VERSION ""

NS_ :

BS_:

BU_:BMS FCS VCU
BO_ 2550530133 BatP5_BMS_PackPowerCapability: 8 BMS
 SG_ P5_PackDschrgPwrLmt : 7|10@0+ (1,0) [0|1000] "kW" VCU
 SG_ P5_PackDschrgPwrStat : 13|2@0+ (1,0) [0|3] "" VCU
 SG_ P5_PackChrgPwrLmt : 11|10@0+ (1,0) [0|1000] "kW" VCU
 SG_ P5_PackChrgPwrStat : 17|2@0+ (1,0) [0|3] "" VCU

BO_ 2550595669 BatP5_BMS_ChargingInfo: 8 BMS
 SG_ P5_ChrgrCplrStat : 7|1@0+ (1,0) [0|1] "" VCU
 SG_ P5_HVBattChrgSysStatus : 6|4@0+ (1,0) [0|15] "" VCU
 SG_ P5_DCChrgCrntCmd : 2|9@0+ (1,0) [0|500] "A" VCU
 SG_ P5_CC2Vlt : 9|8@0+ (0.1,0) [0|25] "V" VCU
 SG_ P5_DCRcptPosTemp : 17|9@0+ (0.5,-40) [-40|150] "C" VCU
 SG_ P5_DCRcptNegTemp : 24|9@0+ (0.5,-40) [-40|150] "C" VCU
 SG_ P5_Tm2FullChrg : 47|14@0+ (1,0) [0|65535] "min" VCU

BO_ 2550661205 BatP5_BMS_ThermalManagement: 8 BMS
 SG_ P5_Inlet1ClntTemp : 7|11@0+ (0.1,-40) [-40|150] "C" VCU
 SG_ P5_Inlet2ClntTemp : 12|11@0+ (0.1,-40) [-40|150] "C" VCU
 SG_ P5_Outlet1ClntTemp : 17|11@0+ (0.1,-40) [-40|150] "C" VCU
 SG_ P5_Outlet2ClntTemp : 38|11@0+ (0.1,-40) [-40|150] "C" VCU
 SG_ P5_TrgtClntTemp : 43|11@0+ (0.1,-40) [-40|150] "C" VCU
 SG_ P5_TrgtClntFlowRate : 48|9@0+ (0.2,0) [0|100] "C" VCU

BO_ 2550726741 BatP5_BMS_CellVoltMaxMin: 8 BMS
 SG_ P5_MaxCellVlt : 7|13@0+ (0.001,0) [0|5] "V" VCU
 SG_ P5_MaxCellVltNum : 10|9@0+ (1,0) [0|500] "" VCU
 SG_ P5_MinCellVlt : 17|13@0+ (0.001,0) [0|5] "V" VCU
 SG_ P5_MinCellVltNum : 36|9@0+ (1,0) [0|500] "" VCU
 SG_ P5_AvgCellVlt : 43|13@0+ (0.001,0) [0|5] "V" VCU

BO_ 2550792277 BatP5_BMS_CellTempMaxMin: 8 BMS
 SG_ P5_MaxCellTemp : 7|11@0+ (0.1,-40) [-40|150] "C" VCU
 SG_ P5_MaxCellTempNum : 12|9@0+ (1,0) [0|500] "" VCU
 SG_ P5_MinCellTemp : 19|11@0+ (0.1,-40) [-40|150] "C" VCU
 SG_ P5_MinCellTempNum : 24|9@0+ (1,0) [0|500] "" VCU
 SG_ P5_AvgCellTemp : 47|11@0+ (0.1,-40) [-40|150] "C" VCU

BO_ 2550857813 BatP5_BMS_PackFaultInfo1: 8 BMS
 SG_ P5_PackTotFltNum : 7|8@0+ (1,0) [0|200] "" VCU
 SG_ P5_CellOverVoltage : 15|2@0+ (1,0) [0|3] "" VCU
 SG_ P5_CellUnderVoltage : 13|2@0+ (1,0) [0|3] "" VCU
 SG_ P5_CellVoltageDiffHi : 11|1@0+ (1,0) [0|1] "" VCU
 SG_ P5_PackOverVoltage : 10|2@0+ (1,0) [0|3] "" VCU
 SG_ P5_PackUnderVoltage : 8|2@0+ (1,0) [0|3] "" VCU
 SG_ P5_CellOverTemp : 22|2@0+ (1,0) [0|3] "" VCU
 SG_ P5_CellTempLow : 20|1@0+ (1,0) [0|1] "" VCU
 SG_ P5_CellTempDiffHi : 19|1@0+ (1,0) [0|1] "" VCU
 SG_ P5_PackDschrgCrntHi : 18|2@0+ (1,0) [0|3] "" VCU
 SG_ P5_PackChrgCrntHi : 16|2@0+ (1,0) [0|3] "" VCU
 SG_ P5_PackCrnSnsr1OffsetHi : 30|1@0+ (1,0) [0|1] "" VCU
 SG_ P5_HVIsolFlt : 29|2@0+ (1,0) [0|3] "" VCU
 SG_ P5_HVILFlt : 27|1@0+ (1,0) [0|1] "" VCU
 SG_ P5_ThrmlRunaway : 26|1@0+ (1,0) [0|1] "" VCU
 SG_ P5_CellVoltInvalid : 25|1@0+ (1,0) [0|1] "" VCU
 SG_ P5_CellTempInvalid : 24|1@0+ (1,0) [0|1] "" VCU
 SG_ P5_DaisyChainComFlt : 39|1@0+ (1,0) [0|1] "" VCU
 SG_ P5_PackVoltRatFlt : 38|1@0+ (1,0) [0|1] "" VCU
 SG_ P5_CrntSnsr1Invalid : 37|1@0+ (1,0) [0|1] "" VCU
 SG_ P5_CrntSnsr1OOR : 36|1@0+ (1,0) [0|1] "" VCU
 SG_ P5_CrntSnsr2Invalid : 35|1@0+ (1,0) [0|1] "" VCU
 SG_ P5_CrntSnsr2OOR : 34|1@0+ (1,0) [0|1] "" VCU
 SG_ P5_PackCrnSnsr2OffsetHi : 33|1@0+ (1,0) [0|1] "" VCU
 SG_ P5_OutofEnergy : 32|1@0+ (1,0) [0|1] "" VCU
 SG_ P5_IsolDetCircErr : 47|1@0+ (1,0) [0|1] "" VCU
 SG_ P5_HVILCircShortToGND : 46|1@0+ (1,0) [0|1] "" VCU
 SG_ P5_HVILCircShortToPwr : 45|1@0+ (1,0) [0|1] "" VCU

BO_ 2550923349 BatP5_BMS_PackFaultInfo2: 8 BMS
 SG_ P5_MainPosCntctrStkClsd : 7|1@0+ (1,0) [0|1] "" VCU
 SG_ P5_MainPosCntctrStkOpn : 6|1@0+ (1,0) [0|1] "" VCU
 SG_ P5_MainNegCntctr1StkClsd : 5|1@0+ (1,0) [0|1] "" VCU
 SG_ P5_MainNegCntctr1StkOpn : 4|1@0+ (1,0) [0|1] "" VCU
 SG_ P5_MainNegCntctr2StkClsd : 3|1@0+ (1,0) [0|1] "" VCU
 SG_ P5_MainNegCntctr2StkOpn : 2|1@0+ (1,0) [0|1] "" VCU
 SG_ P5_PrechargTmOut : 1|1@0+ (1,0) [0|1] "" VCU
 SG_ P5_PrechrgCrntHi : 0|1@0+ (1,0) [0|1] "" VCU
 SG_ P5_ChrgCplrPosTempHi : 15|1@0+ (1,0) [0|1] "" VCU
 SG_ P5_ChrgCplrNegTempHi : 14|1@0+ (1,0) [0|1] "" VCU
 SG_ P5_BMSPwrSuplVlt1Hi : 13|1@0+ (1,0) [0|1] "" VCU
 SG_ P5_BMSPwrSuplVlt1Lo : 12|1@0+ (1,0) [0|1] "" VCU
 SG_ P5_BMSPwrSuplVlt2Hi : 11|1@0+ (1,0) [0|1] "" VCU
 SG_ P5_BMSPwrSuplVlt2Lo : 10|1@0+ (1,0) [0|1] "" VCU
 SG_ P5_CntctrCirPwrSuplVltLo : 9|1@0+ (1,0) [0|1] "" VCU
 SG_ P5_CntctrCirPwrSuplVltHi : 8|1@0+ (1,0) [0|1] "" VCU
 SG_ P5_CAN1BusOff : 23|1@0+ (1,0) [0|1] "" VCU
 SG_ P5_CAN1BusTmOut : 22|1@0+ (1,0) [0|1] "" VCU
 SG_ P5_CAN2BusOff : 21|1@0+ (1,0) [0|1] "" VCU
 SG_ P5_CAN2BusTmOut : 20|1@0+ (1,0) [0|1] "" VCU
 SG_ P5_CellBalCircTempHi : 19|1@0+ (1,0) [0|1] "" VCU
 SG_ P5_ClntInTempHi : 18|1@0+ (1,0) [0|1] "" VCU
 SG_ P5_ClntOutTempHi : 17|1@0+ (1,0) [0|1] "" VCU
 SG_ P5_CellExtrmUdrVolt : 16|1@0+ (1,0) [0|1] "" VCU
 SG_ P5_CellExtrmOvrVolt : 31|1@0+ (1,0) [0|1] "" VCU
 SG_ P5_Branch1DischrgCrntHi  : 30|1@0+ (1,0) [0|1] "" VCU
 SG_ P5_Branch2DischrgCrntHi  : 29|1@0+ (1,0) [0|1] "" VCU
 SG_ P5_Branch1ChrgCrntHi  : 28|1@0+ (1,0) [0|1] "" VCU
 SG_ P5_Branch2ChrgCrntHi  : 27|1@0+ (1,0) [0|1] "" VCU
 SG_ P5_InitFailed : 26|1@0+ (1,0) [0|1] "" VCU
 SG_ P5_PackErrCode : 25|10@0+ (1,0) [0|1023] "" VCU

BO_ 2550988885 BatP5_BMS_PackConfigInfo: 8 BMS
 SG_ P5_PackTotCellNum : 7|9@0+ (1,0) [0|500] "" VCU
 SG_ P5_PackTotCellTempSnsrNum : 14|9@0+ (1,0) [0|500] "" VCU

BO_ 2552299605 BatP5_BMS_BMSVersion: 8 BMS
 SG_ P5_BMSASWMajVerNum : 7|8@0+ (1,0) [0|9] "" VCU
 SG_ P5_BMSASWMinVerNum : 15|8@0+ (1,0) [0|99] "" VCU
 SG_ P5_BMSASWPatchVerNum : 23|8@0+ (1,0) [0|255] "" VCU
 SG_ P5_BMSBSWMajVerNum : 31|8@0+ (1,0) [0|9] "" VCU
 SG_ P5_BMSBSWMinVerNum : 39|8@0+ (1,0) [0|99] "" VCU
 SG_ P5_BMSBSWPatchVerNum : 47|8@0+ (1,0) [0|255] "" VCU

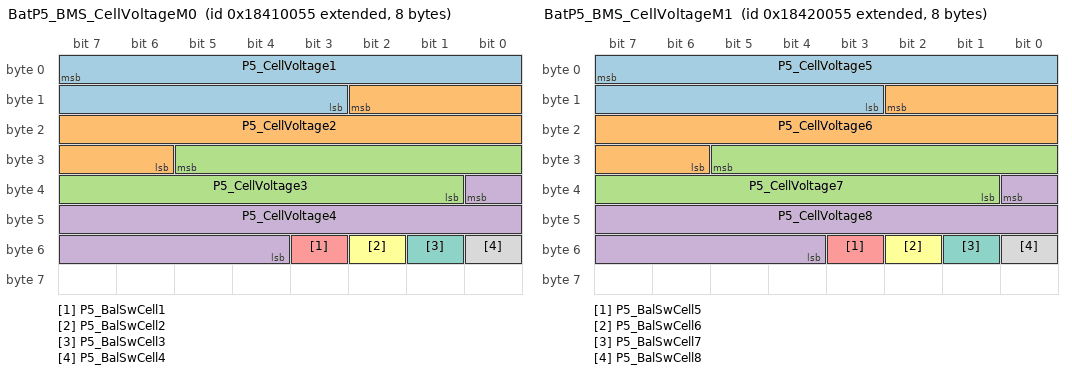
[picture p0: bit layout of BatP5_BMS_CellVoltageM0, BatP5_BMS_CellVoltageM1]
BO_ 2554396757 BatP5_BMS_CellVoltageM0: 8 BMS
 SG_ P5_CellVoltage1 : 7|13@0+ (0.001,0) [0|5] "V" VCU
 SG_ P5_CellVoltage2 : 10|13@0+ (0.001,0) [0|5] "V" VCU
 SG_ P5_CellVoltage3 : 29|13@0+ (0.001,0) [0|5] "V" VCU
 SG_ P5_CellVoltage4 : 32|13@0+ (0.001,0) [0|5] "V" VCU
 SG_ P5_BalSwCell1 : 51|1@0+ (1,0) [0|1] "" VCU
 SG_ P5_BalSwCell2 : 50|1@0+ (1,0) [0|1] "" VCU
 SG_ P5_BalSwCell3 : 49|1@0+ (1,0) [0|1] "" VCU
 SG_ P5_BalSwCell4 : 48|1@0+ (1,0) [0|1] "" VCU

BO_ 2554462293 BatP5_BMS_CellVoltageM1: 8 BMS
 SG_ P5_CellVoltage5 : 7|13@0+ (0.001,0) [0|5] "V" VCU
 SG_ P5_CellVoltage6 : 10|13@0+ (0.001,0) [0|5] "V" VCU
 SG_ P5_CellVoltage7 : 29|13@0+ (0.001,0) [0|5] "V" VCU
 SG_ P5_CellVoltage8 : 32|13@0+ (0.001,0) [0|5] "V" VCU
 SG_ P5_BalSwCell5 : 51|1@0+ (1,0) [0|1] "" VCU
 SG_ P5_BalSwCell6 : 50|1@0+ (1,0) [0|1] "" VCU
 SG_ P5_BalSwCell7 : 49|1@0+ (1,0) [0|1] "" VCU
 SG_ P5_BalSwCell8 : 48|1@0+ (1,0) [0|1] "" VCU

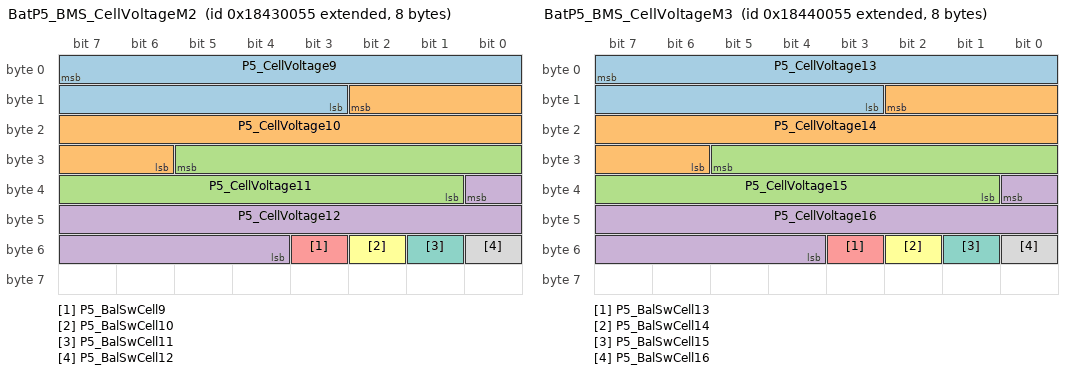
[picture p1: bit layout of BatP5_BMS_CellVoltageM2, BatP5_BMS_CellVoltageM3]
BO_ 2554527829 BatP5_BMS_CellVoltageM2: 8 BMS
 SG_ P5_CellVoltage9 : 7|13@0+ (0.001,0) [0|5] "V" VCU
 SG_ P5_CellVoltage10 : 10|13@0+ (0.001,0) [0|5] "V" VCU
 SG_ P5_CellVoltage11 : 29|13@0+ (0.001,0) [0|5] "V" VCU
 SG_ P5_CellVoltage12 : 32|13@0+ (0.001,0) [0|5] "V" VCU
 SG_ P5_BalSwCell9 : 51|1@0+ (1,0) [0|1] "" VCU
 SG_ P5_BalSwCell10 : 50|1@0+ (1,0) [0|1] "" VCU
 SG_ P5_BalSwCell11 : 49|1@0+ (1,0) [0|1] "" VCU
 SG_ P5_BalSwCell12 : 48|1@0+ (1,0) [0|1] "" VCU

BO_ 2554593365 BatP5_BMS_CellVoltageM3: 8 BMS
 SG_ P5_CellVoltage13 : 7|13@0+ (0.001,0) [0|5] "V" VCU
 SG_ P5_CellVoltage14 : 10|13@0+ (0.001,0) [0|5] "V" VCU
 SG_ P5_CellVoltage15 : 29|13@0+ (0.001,0) [0|5] "V" VCU
 SG_ P5_CellVoltage16 : 32|13@0+ (0.001,0) [0|5] "V" VCU
 SG_ P5_BalSwCell13 : 51|1@0+ (1,0) [0|1] "" VCU
 SG_ P5_BalSwCell14 : 50|1@0+ (1,0) [0|1] "" VCU
 SG_ P5_BalSwCell15 : 49|1@0+ (1,0) [0|1] "" VCU
 SG_ P5_BalSwCell16 : 48|1@0+ (1,0) [0|1] "" VCU

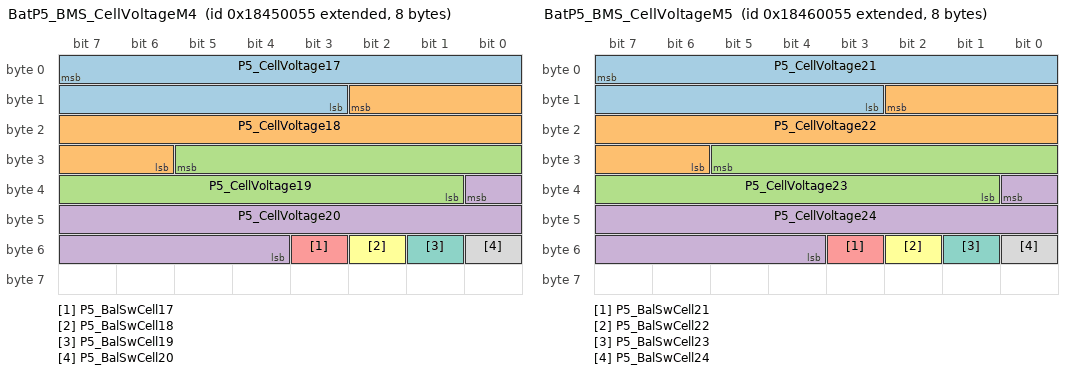
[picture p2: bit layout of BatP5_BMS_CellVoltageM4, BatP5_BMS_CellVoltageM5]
BO_ 2554658901 BatP5_BMS_CellVoltageM4: 8 BMS
 SG_ P5_CellVoltage17 : 7|13@0+ (0.001,0) [0|5] "V" VCU
 SG_ P5_CellVoltage18 : 10|13@0+ (0.001,0) [0|5] "V" VCU
 SG_ P5_CellVoltage19 : 29|13@0+ (0.001,0) [0|5] "V" VCU
 SG_ P5_CellVoltage20 : 32|13@0+ (0.001,0) [0|5] "V" VCU
 SG_ P5_BalSwCell17 : 51|1@0+ (1,0) [0|1] "" VCU
 SG_ P5_BalSwCell18 : 50|1@0+ (1,0) [0|1] "" VCU
 SG_ P5_BalSwCell19 : 49|1@0+ (1,0) [0|1] "" VCU
 SG_ P5_BalSwCell20 : 48|1@0+ (1,0) [0|1] "" VCU

BO_ 2554724437 BatP5_BMS_CellVoltageM5: 8 BMS
 SG_ P5_CellVoltage21 : 7|13@0+ (0.001,0) [0|5] "V" VCU
 SG_ P5_CellVoltage22 : 10|13@0+ (0.001,0) [0|5] "V" VCU
 SG_ P5_CellVoltage23 : 29|13@0+ (0.001,0) [0|5] "V" VCU
 SG_ P5_CellVoltage24 : 32|13@0+ (0.001,0) [0|5] "V" VCU
 SG_ P5_BalSwCell21 : 51|1@0+ (1,0) [0|1] "" VCU
 SG_ P5_BalSwCell22 : 50|1@0+ (1,0) [0|1] "" VCU
 SG_ P5_BalSwCell23 : 49|1@0+ (1,0) [0|1] "" VCU
 SG_ P5_BalSwCell24 : 48|1@0+ (1,0) [0|1] "" VCU

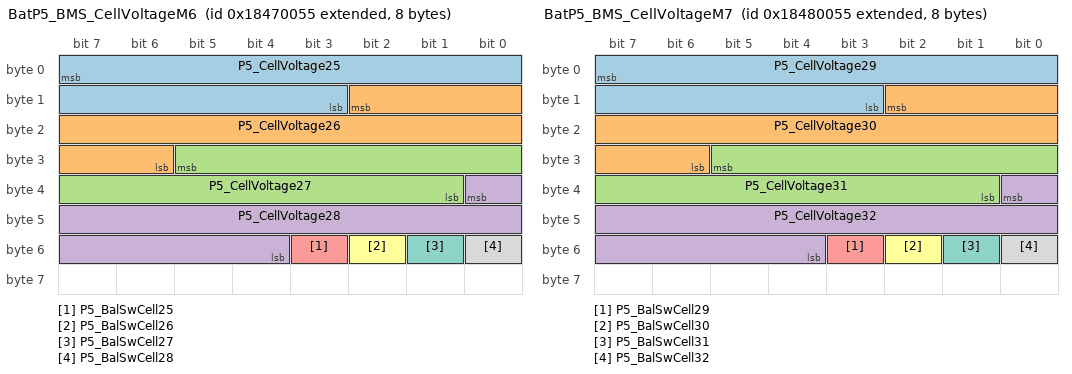
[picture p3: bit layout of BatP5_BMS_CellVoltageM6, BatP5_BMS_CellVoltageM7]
BO_ 2554789973 BatP5_BMS_CellVoltageM6: 8 BMS
 SG_ P5_CellVoltage25 : 7|13@0+ (0.001,0) [0|5] "V" VCU
 SG_ P5_CellVoltage26 : 10|13@0+ (0.001,0) [0|5] "V" VCU
 SG_ P5_CellVoltage27 : 29|13@0+ (0.001,0) [0|5] "V" VCU
 SG_ P5_CellVoltage28 : 32|13@0+ (0.001,0) [0|5] "V" VCU
 SG_ P5_BalSwCell25 : 51|1@0+ (1,0) [0|1] "" VCU
 SG_ P5_BalSwCell26 : 50|1@0+ (1,0) [0|1] "" VCU
 SG_ P5_BalSwCell27 : 49|1@0+ (1,0) [0|1] "" VCU
 SG_ P5_BalSwCell28 : 48|1@0+ (1,0) [0|1] "" VCU

BO_ 2554855509 BatP5_BMS_CellVoltageM7: 8 BMS
 SG_ P5_CellVoltage29 : 7|13@0+ (0.001,0) [0|5] "V" VCU
 SG_ P5_CellVoltage30 : 10|13@0+ (0.001,0) [0|5] "V" VCU
 SG_ P5_CellVoltage31 : 29|13@0+ (0.001,0) [0|5] "V" VCU
 SG_ P5_CellVoltage32 : 32|13@0+ (0.001,0) [0|5] "V" VCU
 SG_ P5_BalSwCell29 : 51|1@0+ (1,0) [0|1] "" VCU
 SG_ P5_BalSwCell30 : 50|1@0+ (1,0) [0|1] "" VCU
 SG_ P5_BalSwCell31 : 49|1@0+ (1,0) [0|1] "" VCU
 SG_ P5_BalSwCell32 : 48|1@0+ (1,0) [0|1] "" VCU

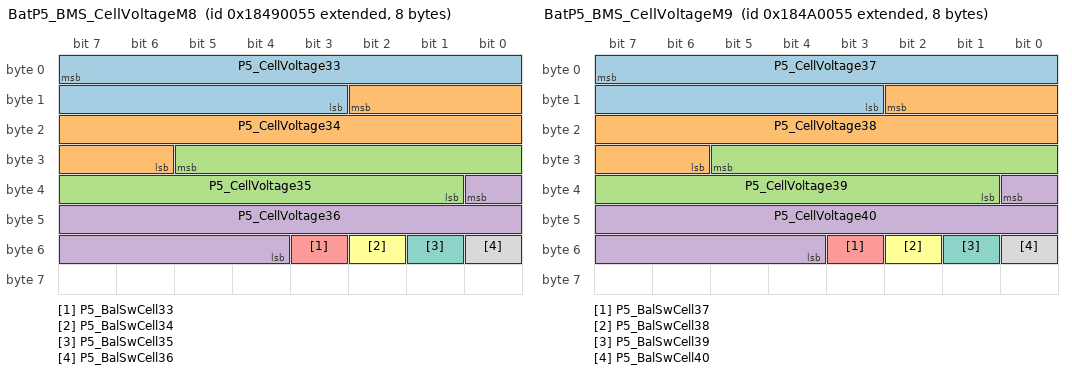
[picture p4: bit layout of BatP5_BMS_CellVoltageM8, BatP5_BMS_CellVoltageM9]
BO_ 2554921045 BatP5_BMS_CellVoltageM8: 8 BMS
 SG_ P5_CellVoltage33 : 7|13@0+ (0.001,0) [0|5] "V" VCU
 SG_ P5_CellVoltage34 : 10|13@0+ (0.001,0) [0|5] "V" VCU
 SG_ P5_CellVoltage35 : 29|13@0+ (0.001,0) [0|5] "V" VCU
 SG_ P5_CellVoltage36 : 32|13@0+ (0.001,0) [0|5] "V" VCU
 SG_ P5_BalSwCell33 : 51|1@0+ (1,0) [0|1] "" VCU
 SG_ P5_BalSwCell34 : 50|1@0+ (1,0) [0|1] "" VCU
 SG_ P5_BalSwCell35 : 49|1@0+ (1,0) [0|1] "" VCU
 SG_ P5_BalSwCell36 : 48|1@0+ (1,0) [0|1] "" VCU

BO_ 2554986581 BatP5_BMS_CellVoltageM9: 8 BMS
 SG_ P5_CellVoltage37 : 7|13@0+ (0.001,0) [0|5] "V" VCU
 SG_ P5_CellVoltage38 : 10|13@0+ (0.001,0) [0|5] "V" VCU
 SG_ P5_CellVoltage39 : 29|13@0+ (0.001,0) [0|5] "V" VCU
 SG_ P5_CellVoltage40 : 32|13@0+ (0.001,0) [0|5] "V" VCU
 SG_ P5_BalSwCell37 : 51|1@0+ (1,0) [0|1] "" VCU
 SG_ P5_BalSwCell38 : 50|1@0+ (1,0) [0|1] "" VCU
 SG_ P5_BalSwCell39 : 49|1@0+ (1,0) [0|1] "" VCU
 SG_ P5_BalSwCell40 : 48|1@0+ (1,0) [0|1] "" VCU

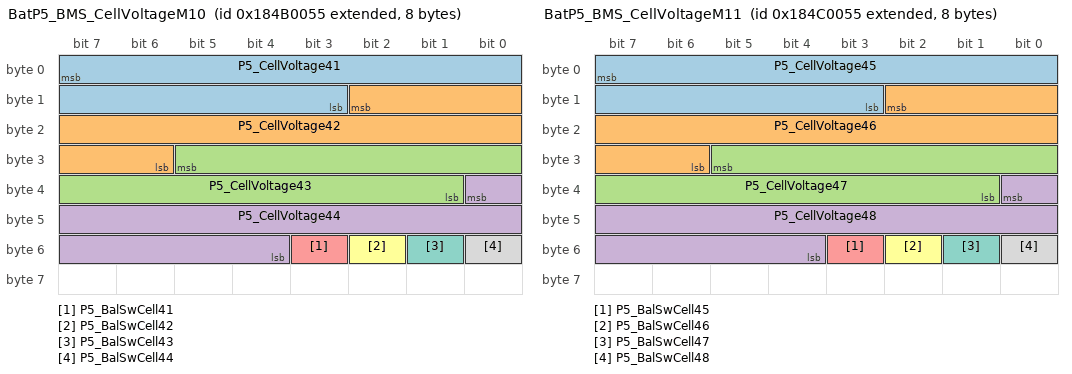
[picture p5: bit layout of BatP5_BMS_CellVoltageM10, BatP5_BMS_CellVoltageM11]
BO_ 2555052117 BatP5_BMS_CellVoltageM10: 8 BMS
 SG_ P5_CellVoltage41 : 7|13@0+ (0.001,0) [0|5] "V" VCU
 SG_ P5_CellVoltage42 : 10|13@0+ (0.001,0) [0|5] "V" VCU
 SG_ P5_CellVoltage43 : 29|13@0+ (0.001,0) [0|5] "V" VCU
 SG_ P5_CellVoltage44 : 32|13@0+ (0.001,0) [0|5] "V" VCU
 SG_ P5_BalSwCell41 : 51|1@0+ (1,0) [0|1] "" VCU
 SG_ P5_BalSwCell42 : 50|1@0+ (1,0) [0|1] "" VCU
 SG_ P5_BalSwCell43 : 49|1@0+ (1,0) [0|1] "" VCU
 SG_ P5_BalSwCell44 : 48|1@0+ (1,0) [0|1] "" VCU

BO_ 2555117653 BatP5_BMS_CellVoltageM11: 8 BMS
 SG_ P5_CellVoltage45 : 7|13@0+ (0.001,0) [0|5] "V" VCU
 SG_ P5_CellVoltage46 : 10|13@0+ (0.001,0) [0|5] "V" VCU
 SG_ P5_CellVoltage47 : 29|13@0+ (0.001,0) [0|5] "V" VCU
 SG_ P5_CellVoltage48 : 32|13@0+ (0.001,0) [0|5] "V" VCU
 SG_ P5_BalSwCell45 : 51|1@0+ (1,0) [0|1] "" VCU
 SG_ P5_BalSwCell46 : 50|1@0+ (1,0) [0|1] "" VCU
 SG_ P5_BalSwCell47 : 49|1@0+ (1,0) [0|1] "" VCU
 SG_ P5_BalSwCell48 : 48|1@0+ (1,0) [0|1] "" VCU

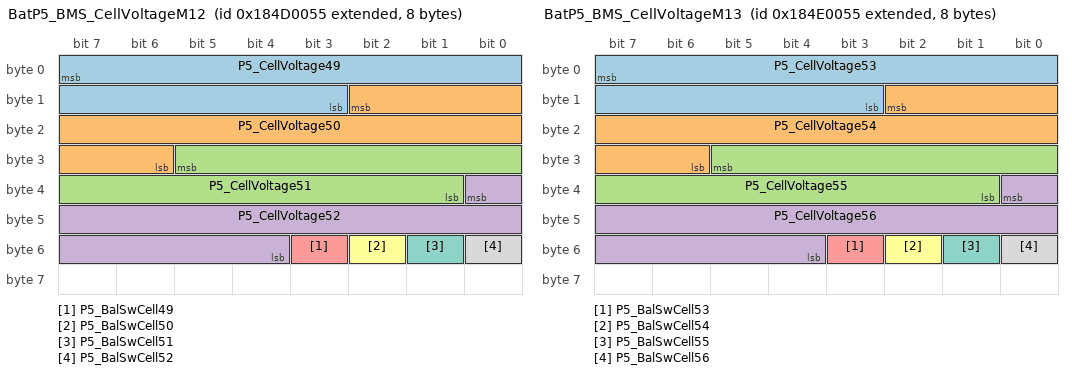
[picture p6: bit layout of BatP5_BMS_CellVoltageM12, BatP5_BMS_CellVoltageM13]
BO_ 2555183189 BatP5_BMS_CellVoltageM12: 8 BMS
 SG_ P5_CellVoltage49 : 7|13@0+ (0.001,0) [0|5] "V" VCU
 SG_ P5_CellVoltage50 : 10|13@0+ (0.001,0) [0|5] "V" VCU
 SG_ P5_CellVoltage51 : 29|13@0+ (0.001,0) [0|5] "V" VCU
 SG_ P5_CellVoltage52 : 32|13@0+ (0.001,0) [0|5] "V" VCU
 SG_ P5_BalSwCell49 : 51|1@0+ (1,0) [0|1] "" VCU
 SG_ P5_BalSwCell50 : 50|1@0+ (1,0) [0|1] "" VCU
 SG_ P5_BalSwCell51 : 49|1@0+ (1,0) [0|1] "" VCU
 SG_ P5_BalSwCell52 : 48|1@0+ (1,0) [0|1] "" VCU

BO_ 2555248725 BatP5_BMS_CellVoltageM13: 8 BMS
 SG_ P5_CellVoltage53 : 7|13@0+ (0.001,0) [0|5] "V" VCU
 SG_ P5_CellVoltage54 : 10|13@0+ (0.001,0) [0|5] "V" VCU
 SG_ P5_CellVoltage55 : 29|13@0+ (0.001,0) [0|5] "V" VCU
 SG_ P5_CellVoltage56 : 32|13@0+ (0.001,0) [0|5] "V" VCU
 SG_ P5_BalSwCell53 : 51|1@0+ (1,0) [0|1] "" VCU
 SG_ P5_BalSwCell54 : 50|1@0+ (1,0) [0|1] "" VCU
 SG_ P5_BalSwCell55 : 49|1@0+ (1,0) [0|1] "" VCU
 SG_ P5_BalSwCell56 : 48|1@0+ (1,0) [0|1] "" VCU

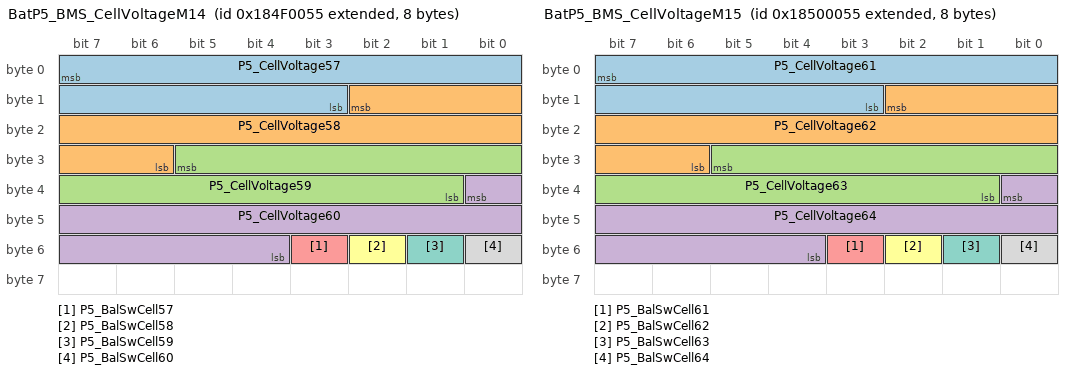
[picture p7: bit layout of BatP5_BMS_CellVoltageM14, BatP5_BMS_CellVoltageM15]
BO_ 2555314261 BatP5_BMS_CellVoltageM14: 8 BMS
 SG_ P5_CellVoltage57 : 7|13@0+ (0.001,0) [0|5] "V" VCU
 SG_ P5_CellVoltage58 : 10|13@0+ (0.001,0) [0|5] "V" VCU
 SG_ P5_CellVoltage59 : 29|13@0+ (0.001,0) [0|5] "V" VCU
 SG_ P5_CellVoltage60 : 32|13@0+ (0.001,0) [0|5] "V" VCU
 SG_ P5_BalSwCell57 : 51|1@0+ (1,0) [0|1] "" VCU
 SG_ P5_BalSwCell58 : 50|1@0+ (1,0) [0|1] "" VCU
 SG_ P5_BalSwCell59 : 49|1@0+ (1,0) [0|1] "" VCU
 SG_ P5_BalSwCell60 : 48|1@0+ (1,0) [0|1] "" VCU

BO_ 2555379797 BatP5_BMS_CellVoltageM15: 8 BMS
 SG_ P5_CellVoltage61 : 7|13@0+ (0.001,0) [0|5] "V" VCU
 SG_ P5_CellVoltage62 : 10|13@0+ (0.001,0) [0|5] "V" VCU
 SG_ P5_CellVoltage63 : 29|13@0+ (0.001,0) [0|5] "V" VCU
 SG_ P5_CellVoltage64 : 32|13@0+ (0.001,0) [0|5] "V" VCU
 SG_ P5_BalSwCell61 : 51|1@0+ (1,0) [0|1] "" VCU
 SG_ P5_BalSwCell62 : 50|1@0+ (1,0) [0|1] "" VCU
 SG_ P5_BalSwCell63 : 49|1@0+ (1,0) [0|1] "" VCU
 SG_ P5_BalSwCell64 : 48|1@0+ (1,0) [0|1] "" VCU

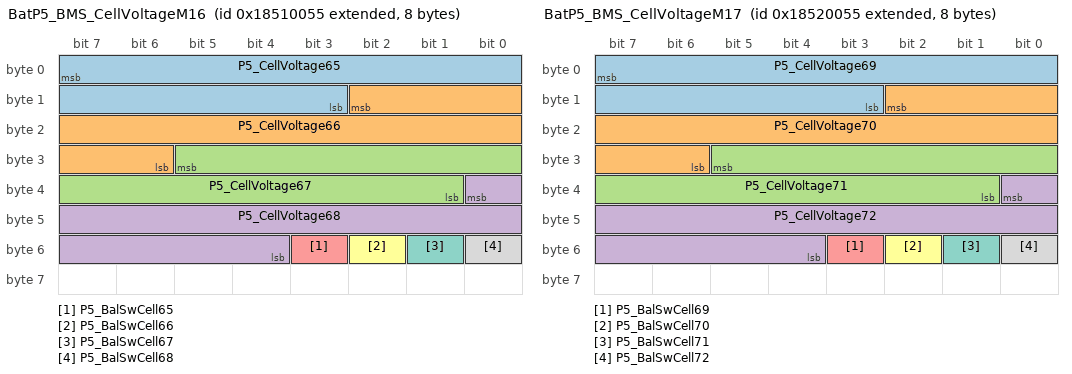
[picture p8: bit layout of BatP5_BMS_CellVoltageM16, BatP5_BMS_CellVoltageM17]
BO_ 2555445333 BatP5_BMS_CellVoltageM16: 8 BMS
 SG_ P5_CellVoltage65 : 7|13@0+ (0.001,0) [0|5] "V" VCU
 SG_ P5_CellVoltage66 : 10|13@0+ (0.001,0) [0|5] "V" VCU
 SG_ P5_CellVoltage67 : 29|13@0+ (0.001,0) [0|5] "V" VCU
 SG_ P5_CellVoltage68 : 32|13@0+ (0.001,0) [0|5] "V" VCU
 SG_ P5_BalSwCell65 : 51|1@0+ (1,0) [0|1] "" VCU
 SG_ P5_BalSwCell66 : 50|1@0+ (1,0) [0|1] "" VCU
 SG_ P5_BalSwCell67 : 49|1@0+ (1,0) [0|1] "" VCU
 SG_ P5_BalSwCell68 : 48|1@0+ (1,0) [0|1] "" VCU

BO_ 2555510869 BatP5_BMS_CellVoltageM17: 8 BMS
 SG_ P5_CellVoltage69 : 7|13@0+ (0.001,0) [0|5] "V" VCU
 SG_ P5_CellVoltage70 : 10|13@0+ (0.001,0) [0|5] "V" VCU
 SG_ P5_CellVoltage71 : 29|13@0+ (0.001,0) [0|5] "V" VCU
 SG_ P5_CellVoltage72 : 32|13@0+ (0.001,0) [0|5] "V" VCU
 SG_ P5_BalSwCell69 : 51|1@0+ (1,0) [0|1] "" VCU
 SG_ P5_BalSwCell70 : 50|1@0+ (1,0) [0|1] "" VCU
 SG_ P5_BalSwCell71 : 49|1@0+ (1,0) [0|1] "" VCU
 SG_ P5_BalSwCell72 : 48|1@0+ (1,0) [0|1] "" VCU

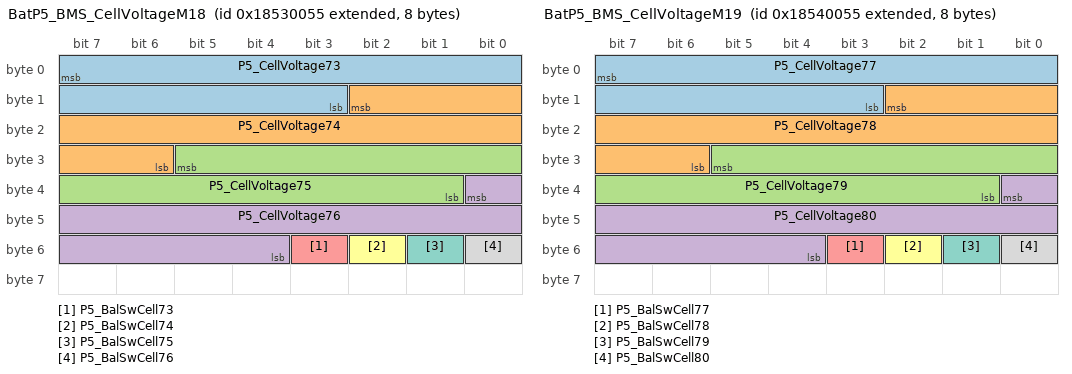
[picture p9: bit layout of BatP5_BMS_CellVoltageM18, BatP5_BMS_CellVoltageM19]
BO_ 2555576405 BatP5_BMS_CellVoltageM18: 8 BMS
 SG_ P5_CellVoltage73 : 7|13@0+ (0.001,0) [0|5] "V" VCU
 SG_ P5_CellVoltage74 : 10|13@0+ (0.001,0) [0|5] "V" VCU
 SG_ P5_CellVoltage75 : 29|13@0+ (0.001,0) [0|5] "V" VCU
 SG_ P5_CellVoltage76 : 32|13@0+ (0.001,0) [0|5] "V" VCU
 SG_ P5_BalSwCell73 : 51|1@0+ (1,0) [0|1] "" VCU
 SG_ P5_BalSwCell74 : 50|1@0+ (1,0) [0|1] "" VCU
 SG_ P5_BalSwCell75 : 49|1@0+ (1,0) [0|1] "" VCU
 SG_ P5_BalSwCell76 : 48|1@0+ (1,0) [0|1] "" VCU

BO_ 2555641941 BatP5_BMS_CellVoltageM19: 8 BMS
 SG_ P5_CellVoltage77 : 7|13@0+ (0.001,0) [0|5] "V" VCU
 SG_ P5_CellVoltage78 : 10|13@0+ (0.001,0) [0|5] "V" VCU
 SG_ P5_CellVoltage79 : 29|13@0+ (0.001,0) [0|5] "V" VCU
 SG_ P5_CellVoltage80 : 32|13@0+ (0.001,0) [0|5] "V" VCU
 SG_ P5_BalSwCell77 : 51|1@0+ (1,0) [0|1] "" VCU
 SG_ P5_BalSwCell78 : 50|1@0+ (1,0) [0|1] "" VCU
 SG_ P5_BalSwCell79 : 49|1@0+ (1,0) [0|1] "" VCU
 SG_ P5_BalSwCell80 : 48|1@0+ (1,0) [0|1] "" VCU

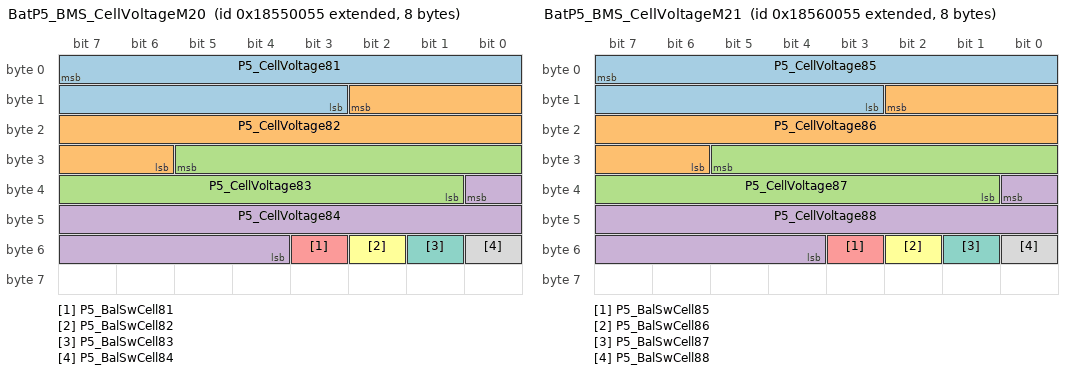
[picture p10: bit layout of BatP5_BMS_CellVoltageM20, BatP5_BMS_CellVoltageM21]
BO_ 2555707477 BatP5_BMS_CellVoltageM20: 8 BMS
 SG_ P5_CellVoltage81 : 7|13@0+ (0.001,0) [0|5] "V" VCU
 SG_ P5_CellVoltage82 : 10|13@0+ (0.001,0) [0|5] "V" VCU
 SG_ P5_CellVoltage83 : 29|13@0+ (0.001,0) [0|5] "V" VCU
 SG_ P5_CellVoltage84 : 32|13@0+ (0.001,0) [0|5] "V" VCU
 SG_ P5_BalSwCell81 : 51|1@0+ (1,0) [0|1] "" VCU
 SG_ P5_BalSwCell82 : 50|1@0+ (1,0) [0|1] "" VCU
 SG_ P5_BalSwCell83 : 49|1@0+ (1,0) [0|1] "" VCU
 SG_ P5_BalSwCell84 : 48|1@0+ (1,0) [0|1] "" VCU

BO_ 2555773013 BatP5_BMS_CellVoltageM21: 8 BMS
 SG_ P5_CellVoltage85 : 7|13@0+ (0.001,0) [0|5] "V" VCU
 SG_ P5_CellVoltage86 : 10|13@0+ (0.001,0) [0|5] "V" VCU
 SG_ P5_CellVoltage87 : 29|13@0+ (0.001,0) [0|5] "V" VCU
 SG_ P5_CellVoltage88 : 32|13@0+ (0.001,0) [0|5] "V" VCU
 SG_ P5_BalSwCell85 : 51|1@0+ (1,0) [0|1] "" VCU
 SG_ P5_BalSwCell86 : 50|1@0+ (1,0) [0|1] "" VCU
 SG_ P5_BalSwCell87 : 49|1@0+ (1,0) [0|1] "" VCU
 SG_ P5_BalSwCell88 : 48|1@0+ (1,0) [0|1] "" VCU

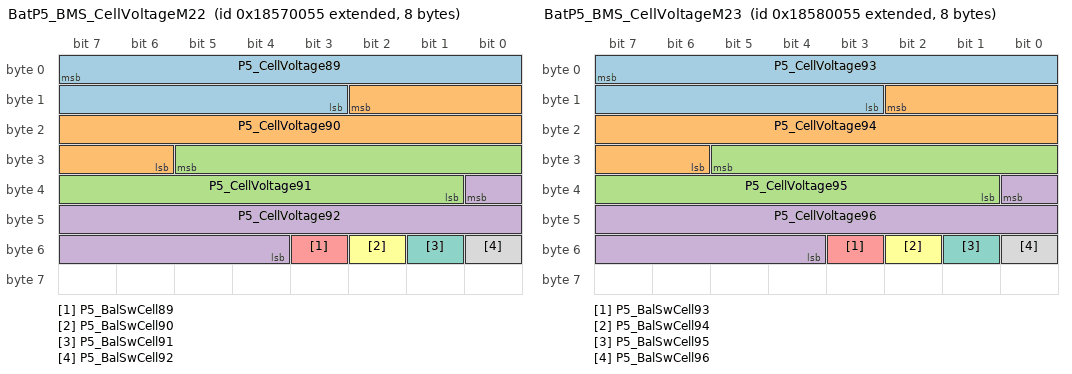
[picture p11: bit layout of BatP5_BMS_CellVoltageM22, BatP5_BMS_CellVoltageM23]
BO_ 2555838549 BatP5_BMS_CellVoltageM22: 8 BMS
 SG_ P5_CellVoltage89 : 7|13@0+ (0.001,0) [0|5] "V" VCU
 SG_ P5_CellVoltage90 : 10|13@0+ (0.001,0) [0|5] "V" VCU
 SG_ P5_CellVoltage91 : 29|13@0+ (0.001,0) [0|5] "V" VCU
 SG_ P5_CellVoltage92 : 32|13@0+ (0.001,0) [0|5] "V" VCU
 SG_ P5_BalSwCell89 : 51|1@0+ (1,0) [0|1] "" VCU
 SG_ P5_BalSwCell90 : 50|1@0+ (1,0) [0|1] "" VCU
 SG_ P5_BalSwCell91 : 49|1@0+ (1,0) [0|1] "" VCU
 SG_ P5_BalSwCell92 : 48|1@0+ (1,0) [0|1] "" VCU

BO_ 2555904085 BatP5_BMS_CellVoltageM23: 8 BMS
 SG_ P5_CellVoltage93 : 7|13@0+ (0.001,0) [0|5] "V" VCU
 SG_ P5_CellVoltage94 : 10|13@0+ (0.001,0) [0|5] "V" VCU
 SG_ P5_CellVoltage95 : 29|13@0+ (0.001,0) [0|5] "V" VCU
 SG_ P5_CellVoltage96 : 32|13@0+ (0.001,0) [0|5] "V" VCU
 SG_ P5_BalSwCell93 : 51|1@0+ (1,0) [0|1] "" VCU
 SG_ P5_BalSwCell94 : 50|1@0+ (1,0) [0|1] "" VCU
 SG_ P5_BalSwCell95 : 49|1@0+ (1,0) [0|1] "" VCU
 SG_ P5_BalSwCell96 : 48|1@0+ (1,0) [0|1] "" VCU

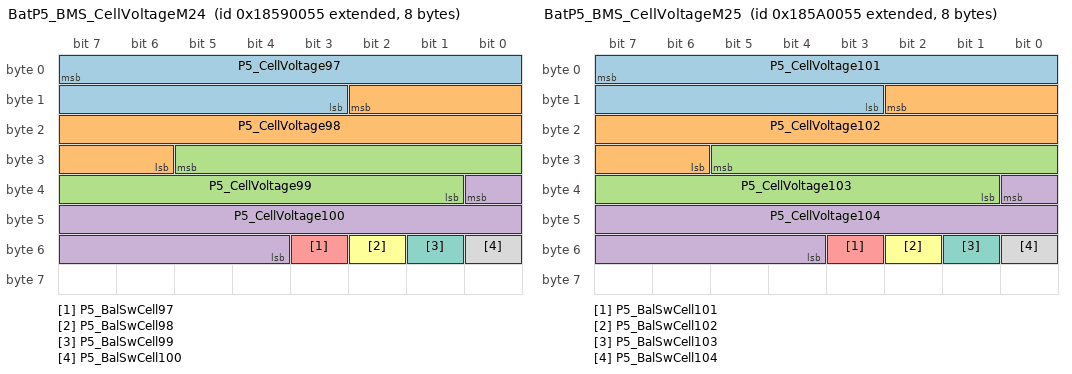
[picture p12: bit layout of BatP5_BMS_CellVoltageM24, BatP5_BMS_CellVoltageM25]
BO_ 2555969621 BatP5_BMS_CellVoltageM24: 8 BMS
 SG_ P5_CellVoltage97 : 7|13@0+ (0.001,0) [0|5] "V" VCU
 SG_ P5_CellVoltage98 : 10|13@0+ (0.001,0) [0|5] "V" VCU
 SG_ P5_CellVoltage99 : 29|13@0+ (0.001,0) [0|5] "V" VCU
 SG_ P5_CellVoltage100 : 32|13@0+ (0.001,0) [0|5] "V" VCU
 SG_ P5_BalSwCell97 : 51|1@0+ (1,0) [0|1] "" VCU
 SG_ P5_BalSwCell98 : 50|1@0+ (1,0) [0|1] "" VCU
 SG_ P5_BalSwCell99 : 49|1@0+ (1,0) [0|1] "" VCU
 SG_ P5_BalSwCell100 : 48|1@0+ (1,0) [0|1] "" VCU

BO_ 2556035157 BatP5_BMS_CellVoltageM25: 8 BMS
 SG_ P5_CellVoltage101 : 7|13@0+ (0.001,0) [0|5] "V" VCU
 SG_ P5_CellVoltage102 : 10|13@0+ (0.001,0) [0|5] "V" VCU
 SG_ P5_CellVoltage103 : 29|13@0+ (0.001,0) [0|5] "V" VCU
 SG_ P5_CellVoltage104 : 32|13@0+ (0.001,0) [0|5] "V" VCU
 SG_ P5_BalSwCell101 : 51|1@0+ (1,0) [0|1] "" VCU
 SG_ P5_BalSwCell102 : 50|1@0+ (1,0) [0|1] "" VCU
 SG_ P5_BalSwCell103 : 49|1@0+ (1,0) [0|1] "" VCU
 SG_ P5_BalSwCell104 : 48|1@0+ (1,0) [0|1] "" VCU

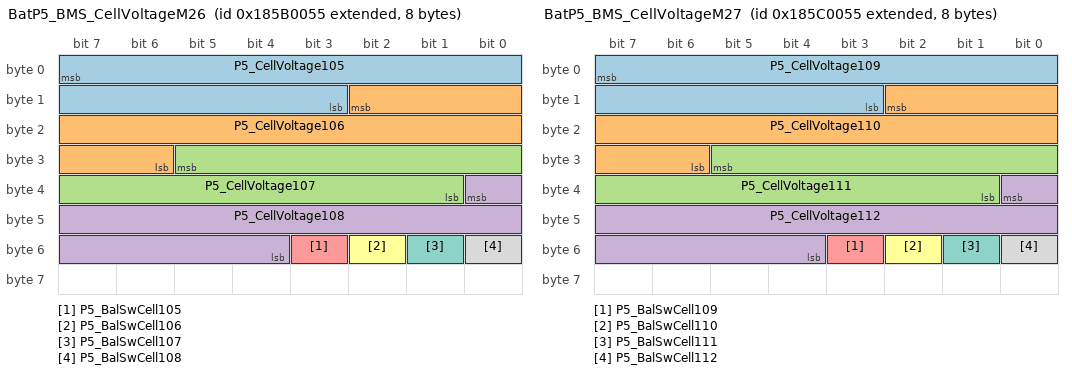
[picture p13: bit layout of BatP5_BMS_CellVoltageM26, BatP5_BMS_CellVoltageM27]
BO_ 2556100693 BatP5_BMS_CellVoltageM26: 8 BMS
 SG_ P5_CellVoltage105 : 7|13@0+ (0.001,0) [0|5] "V" VCU
 SG_ P5_CellVoltage106 : 10|13@0+ (0.001,0) [0|5] "V" VCU
 SG_ P5_CellVoltage107 : 29|13@0+ (0.001,0) [0|5] "V" VCU
 SG_ P5_CellVoltage108 : 32|13@0+ (0.001,0) [0|5] "V" VCU
 SG_ P5_BalSwCell105 : 51|1@0+ (1,0) [0|1] "" VCU
 SG_ P5_BalSwCell106 : 50|1@0+ (1,0) [0|1] "" VCU
 SG_ P5_BalSwCell107 : 49|1@0+ (1,0) [0|1] "" VCU
 SG_ P5_BalSwCell108 : 48|1@0+ (1,0) [0|1] "" VCU

BO_ 2556166229 BatP5_BMS_CellVoltageM27: 8 BMS
 SG_ P5_CellVoltage109 : 7|13@0+ (0.001,0) [0|5] "V" VCU
 SG_ P5_CellVoltage110 : 10|13@0+ (0.001,0) [0|5] "V" VCU
 SG_ P5_CellVoltage111 : 29|13@0+ (0.001,0) [0|5] "V" VCU
 SG_ P5_CellVoltage112 : 32|13@0+ (0.001,0) [0|5] "V" VCU
 SG_ P5_BalSwCell109 : 51|1@0+ (1,0) [0|1] "" VCU
 SG_ P5_BalSwCell110 : 50|1@0+ (1,0) [0|1] "" VCU
 SG_ P5_BalSwCell111 : 49|1@0+ (1,0) [0|1] "" VCU
 SG_ P5_BalSwCell112 : 48|1@0+ (1,0) [0|1] "" VCU

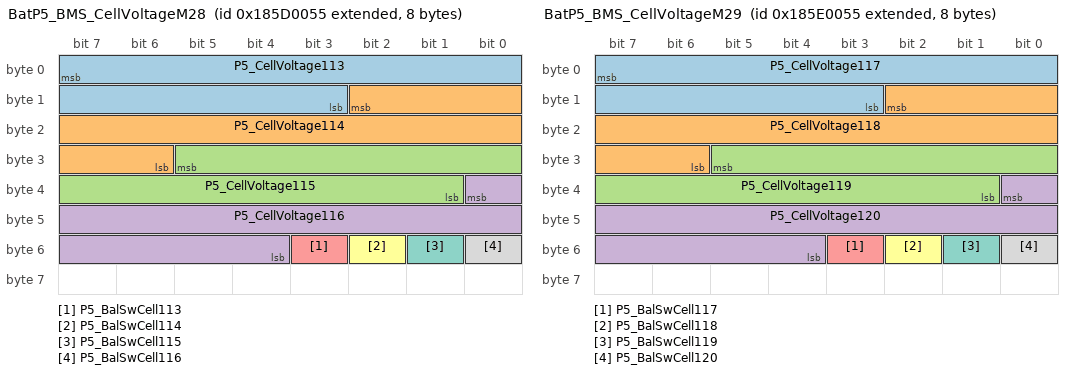
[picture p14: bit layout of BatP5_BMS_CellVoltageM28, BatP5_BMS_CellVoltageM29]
BO_ 2556231765 BatP5_BMS_CellVoltageM28: 8 BMS
 SG_ P5_CellVoltage113 : 7|13@0+ (0.001,0) [0|5] "V" VCU
 SG_ P5_CellVoltage114 : 10|13@0+ (0.001,0) [0|5] "V" VCU
 SG_ P5_CellVoltage115 : 29|13@0+ (0.001,0) [0|5] "V" VCU
 SG_ P5_CellVoltage116 : 32|13@0+ (0.001,0) [0|5] "V" VCU
 SG_ P5_BalSwCell113 : 51|1@0+ (1,0) [0|1] "" VCU
 SG_ P5_BalSwCell114 : 50|1@0+ (1,0) [0|1] "" VCU
 SG_ P5_BalSwCell115 : 49|1@0+ (1,0) [0|1] "" VCU
 SG_ P5_BalSwCell116 : 48|1@0+ (1,0) [0|1] "" VCU

BO_ 2556297301 BatP5_BMS_CellVoltageM29: 8 BMS
 SG_ P5_CellVoltage117 : 7|13@0+ (0.001,0) [0|5] "V" VCU
 SG_ P5_CellVoltage118 : 10|13@0+ (0.001,0) [0|5] "V" VCU
 SG_ P5_CellVoltage119 : 29|13@0+ (0.001,0) [0|5] "V" VCU
 SG_ P5_CellVoltage120 : 32|13@0+ (0.001,0) [0|5] "V" VCU
 SG_ P5_BalSwCell117 : 51|1@0+ (1,0) [0|1] "" VCU
 SG_ P5_BalSwCell118 : 50|1@0+ (1,0) [0|1] "" VCU
 SG_ P5_BalSwCell119 : 49|1@0+ (1,0) [0|1] "" VCU
 SG_ P5_BalSwCell120 : 48|1@0+ (1,0) [0|1] "" VCU

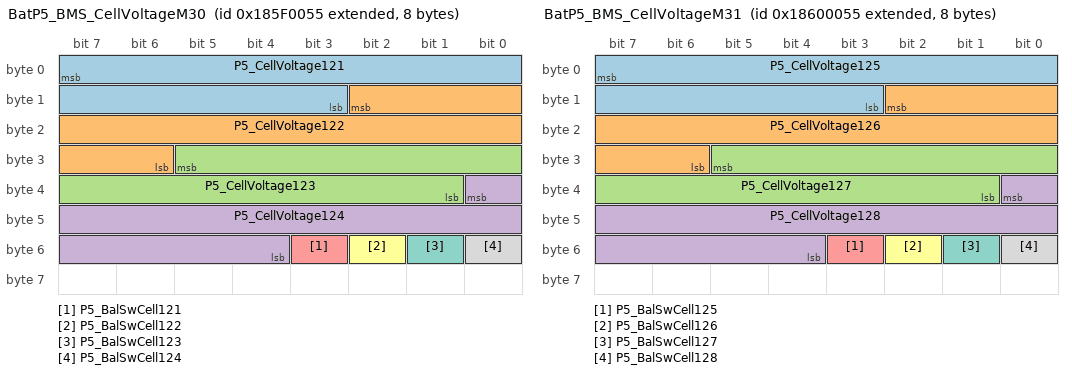
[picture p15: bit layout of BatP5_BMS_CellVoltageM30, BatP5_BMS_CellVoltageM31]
BO_ 2556362837 BatP5_BMS_CellVoltageM30: 8 BMS
 SG_ P5_CellVoltage121 : 7|13@0+ (0.001,0) [0|5] "V" VCU
 SG_ P5_CellVoltage122 : 10|13@0+ (0.001,0) [0|5] "V" VCU
 SG_ P5_CellVoltage123 : 29|13@0+ (0.001,0) [0|5] "V" VCU
 SG_ P5_CellVoltage124 : 32|13@0+ (0.001,0) [0|5] "V" VCU
 SG_ P5_BalSwCell121 : 51|1@0+ (1,0) [0|1] "" VCU
 SG_ P5_BalSwCell122 : 50|1@0+ (1,0) [0|1] "" VCU
 SG_ P5_BalSwCell123 : 49|1@0+ (1,0) [0|1] "" VCU
 SG_ P5_BalSwCell124 : 48|1@0+ (1,0) [0|1] "" VCU

BO_ 2556428373 BatP5_BMS_CellVoltageM31: 8 BMS
 SG_ P5_CellVoltage125 : 7|13@0+ (0.001,0) [0|5] "V" VCU
 SG_ P5_CellVoltage126 : 10|13@0+ (0.001,0) [0|5] "V" VCU
 SG_ P5_CellVoltage127 : 29|13@0+ (0.001,0) [0|5] "V" VCU
 SG_ P5_CellVoltage128 : 32|13@0+ (0.001,0) [0|5] "V" VCU
 SG_ P5_BalSwCell125 : 51|1@0+ (1,0) [0|1] "" VCU
 SG_ P5_BalSwCell126 : 50|1@0+ (1,0) [0|1] "" VCU
 SG_ P5_BalSwCell127 : 49|1@0+ (1,0) [0|1] "" VCU
 SG_ P5_BalSwCell128 : 48|1@0+ (1,0) [0|1] "" VCU

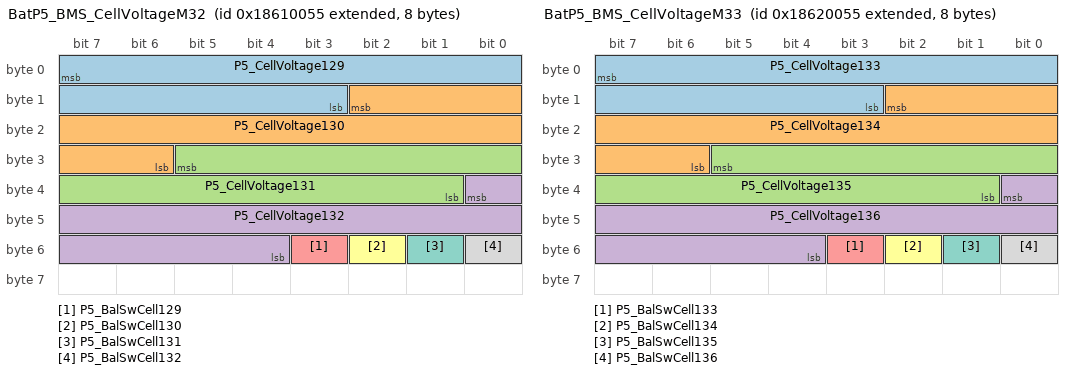
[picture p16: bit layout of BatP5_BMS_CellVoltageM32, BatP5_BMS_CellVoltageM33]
BO_ 2556493909 BatP5_BMS_CellVoltageM32: 8 BMS
 SG_ P5_CellVoltage129 : 7|13@0+ (0.001,0) [0|5] "V" VCU
 SG_ P5_CellVoltage130 : 10|13@0+ (0.001,0) [0|5] "V" VCU
 SG_ P5_CellVoltage131 : 29|13@0+ (0.001,0) [0|5] "V" VCU
 SG_ P5_CellVoltage132 : 32|13@0+ (0.001,0) [0|5] "V" VCU
 SG_ P5_BalSwCell129 : 51|1@0+ (1,0) [0|1] "" VCU
 SG_ P5_BalSwCell130 : 50|1@0+ (1,0) [0|1] "" VCU
 SG_ P5_BalSwCell131 : 49|1@0+ (1,0) [0|1] "" VCU
 SG_ P5_BalSwCell132 : 48|1@0+ (1,0) [0|1] "" VCU

BO_ 2556559445 BatP5_BMS_CellVoltageM33: 8 BMS
 SG_ P5_CellVoltage133 : 7|13@0+ (0.001,0) [0|5] "V" VCU
 SG_ P5_CellVoltage134 : 10|13@0+ (0.001,0) [0|5] "V" VCU
 SG_ P5_CellVoltage135 : 29|13@0+ (0.001,0) [0|5] "V" VCU
 SG_ P5_CellVoltage136 : 32|13@0+ (0.001,0) [0|5] "V" VCU
 SG_ P5_BalSwCell133 : 51|1@0+ (1,0) [0|1] "" VCU
 SG_ P5_BalSwCell134 : 50|1@0+ (1,0) [0|1] "" VCU
 SG_ P5_BalSwCell135 : 49|1@0+ (1,0) [0|1] "" VCU
 SG_ P5_BalSwCell136 : 48|1@0+ (1,0) [0|1] "" VCU

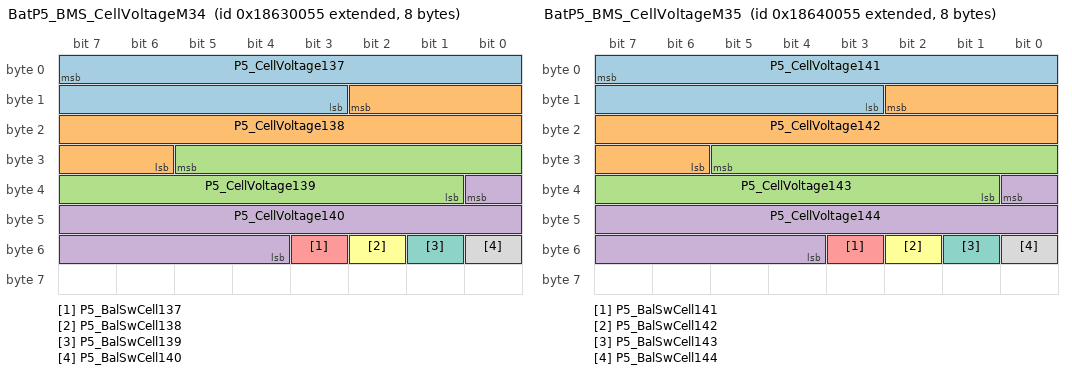
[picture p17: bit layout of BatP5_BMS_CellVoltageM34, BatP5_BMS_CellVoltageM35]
BO_ 2556624981 BatP5_BMS_CellVoltageM34: 8 BMS
 SG_ P5_CellVoltage137 : 7|13@0+ (0.001,0) [0|5] "V" VCU
 SG_ P5_CellVoltage138 : 10|13@0+ (0.001,0) [0|5] "V" VCU
 SG_ P5_CellVoltage139 : 29|13@0+ (0.001,0) [0|5] "V" VCU
 SG_ P5_CellVoltage140 : 32|13@0+ (0.001,0) [0|5] "V" VCU
 SG_ P5_BalSwCell137 : 51|1@0+ (1,0) [0|1] "" VCU
 SG_ P5_BalSwCell138 : 50|1@0+ (1,0) [0|1] "" VCU
 SG_ P5_BalSwCell139 : 49|1@0+ (1,0) [0|1] "" VCU
 SG_ P5_BalSwCell140 : 48|1@0+ (1,0) [0|1] "" VCU

BO_ 2556690517 BatP5_BMS_CellVoltageM35: 8 BMS
 SG_ P5_CellVoltage141 : 7|13@0+ (0.001,0) [0|5] "V" VCU
 SG_ P5_CellVoltage142 : 10|13@0+ (0.001,0) [0|5] "V" VCU
 SG_ P5_CellVoltage143 : 29|13@0+ (0.001,0) [0|5] "V" VCU
 SG_ P5_CellVoltage144 : 32|13@0+ (0.001,0) [0|5] "V" VCU
 SG_ P5_BalSwCell141 : 51|1@0+ (1,0) [0|1] "" VCU
 SG_ P5_BalSwCell142 : 50|1@0+ (1,0) [0|1] "" VCU
 SG_ P5_BalSwCell143 : 49|1@0+ (1,0) [0|1] "" VCU
 SG_ P5_BalSwCell144 : 48|1@0+ (1,0) [0|1] "" VCU

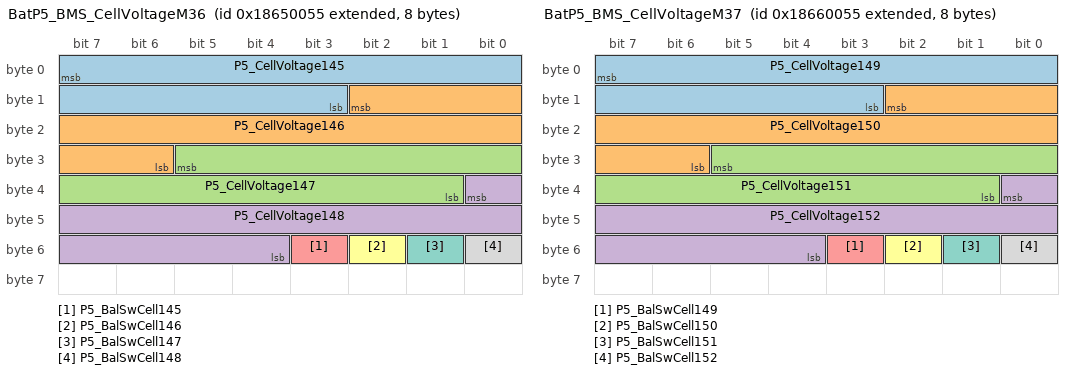
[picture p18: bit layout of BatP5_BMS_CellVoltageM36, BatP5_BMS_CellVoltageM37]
BO_ 2556756053 BatP5_BMS_CellVoltageM36: 8 BMS
 SG_ P5_CellVoltage145 : 7|13@0+ (0.001,0) [0|5] "V" VCU
 SG_ P5_CellVoltage146 : 10|13@0+ (0.001,0) [0|5] "V" VCU
 SG_ P5_CellVoltage147 : 29|13@0+ (0.001,0) [0|5] "V" VCU
 SG_ P5_CellVoltage148 : 32|13@0+ (0.001,0) [0|5] "V" VCU
 SG_ P5_BalSwCell145 : 51|1@0+ (1,0) [0|1] "" VCU
 SG_ P5_BalSwCell146 : 50|1@0+ (1,0) [0|1] "" VCU
 SG_ P5_BalSwCell147 : 49|1@0+ (1,0) [0|1] "" VCU
 SG_ P5_BalSwCell148 : 48|1@0+ (1,0) [0|1] "" VCU

BO_ 2556821589 BatP5_BMS_CellVoltageM37: 8 BMS
 SG_ P5_CellVoltage149 : 7|13@0+ (0.001,0) [0|5] "V" VCU
 SG_ P5_CellVoltage150 : 10|13@0+ (0.001,0) [0|5] "V" VCU
 SG_ P5_CellVoltage151 : 29|13@0+ (0.001,0) [0|5] "V" VCU
 SG_ P5_CellVoltage152 : 32|13@0+ (0.001,0) [0|5] "V" VCU
 SG_ P5_BalSwCell149 : 51|1@0+ (1,0) [0|1] "" VCU
 SG_ P5_BalSwCell150 : 50|1@0+ (1,0) [0|1] "" VCU
 SG_ P5_BalSwCell151 : 49|1@0+ (1,0) [0|1] "" VCU
 SG_ P5_BalSwCell152 : 48|1@0+ (1,0) [0|1] "" VCU

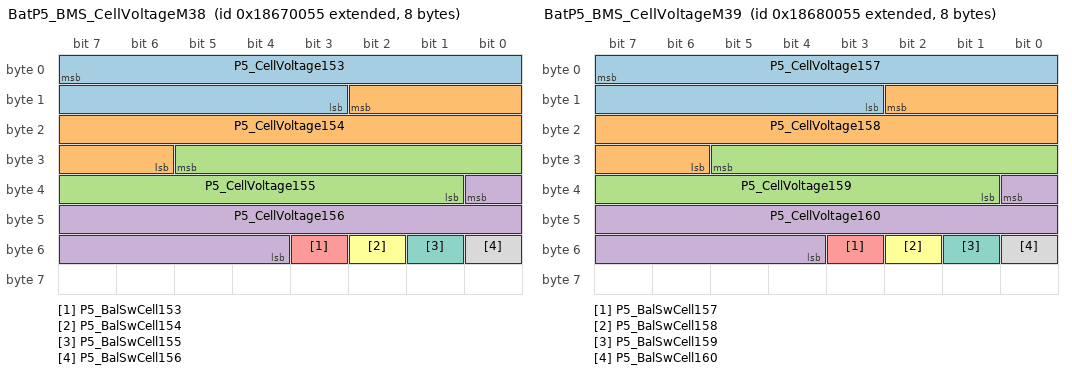
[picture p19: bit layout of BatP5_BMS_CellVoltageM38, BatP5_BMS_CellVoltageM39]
BO_ 2556887125 BatP5_BMS_CellVoltageM38: 8 BMS
 SG_ P5_CellVoltage153 : 7|13@0+ (0.001,0) [0|5] "V" VCU
 SG_ P5_CellVoltage154 : 10|13@0+ (0.001,0) [0|5] "V" VCU
 SG_ P5_CellVoltage155 : 29|13@0+ (0.001,0) [0|5] "V" VCU
 SG_ P5_CellVoltage156 : 32|13@0+ (0.001,0) [0|5] "V" VCU
 SG_ P5_BalSwCell153 : 51|1@0+ (1,0) [0|1] "" VCU
 SG_ P5_BalSwCell154 : 50|1@0+ (1,0) [0|1] "" VCU
 SG_ P5_BalSwCell155 : 49|1@0+ (1,0) [0|1] "" VCU
 SG_ P5_BalSwCell156 : 48|1@0+ (1,0) [0|1] "" VCU

BO_ 2556952661 BatP5_BMS_CellVoltageM39: 8 BMS
 SG_ P5_CellVoltage157 : 7|13@0+ (0.001,0) [0|5] "V" VCU
 SG_ P5_CellVoltage158 : 10|13@0+ (0.001,0) [0|5] "V" VCU
 SG_ P5_CellVoltage159 : 29|13@0+ (0.001,0) [0|5] "V" VCU
 SG_ P5_CellVoltage160 : 32|13@0+ (0.001,0) [0|5] "V" VCU
 SG_ P5_BalSwCell157 : 51|1@0+ (1,0) [0|1] "" VCU
 SG_ P5_BalSwCell158 : 50|1@0+ (1,0) [0|1] "" VCU
 SG_ P5_BalSwCell159 : 49|1@0+ (1,0) [0|1] "" VCU
 SG_ P5_BalSwCell160 : 48|1@0+ (1,0) [0|1] "" VCU

BO_ 2557018197 BatP5_BMS_CellVoltageM40: 8 BMS
 SG_ P5_CellVoltage161 : 7|13@0+ (0.001,0) [0|5] "V" VCU
 SG_ P5_CellVoltage162 : 10|13@0+ (0.001,0) [0|5] "V" VCU
 SG_ P5_CellVoltage163 : 29|13@0+ (0.001,0) [0|5] "V" VCU
 SG_ P5_CellVoltage164 : 32|13@0+ (0.001,0) [0|5] "V" VCU
 SG_ P5_BalSwCell161 : 51|1@0+ (1,0) [0|1] "" VCU
 SG_ P5_BalSwCell162 : 50|1@0+ (1,0) [0|1] "" VCU
 SG_ P5_BalSwCell163 : 49|1@0+ (1,0) [0|1] "" VCU
 SG_ P5_BalSwCell164 : 48|1@0+ (1,0) [0|1] "" VCU

BO_ 2557083733 BatP5_BMS_CellVoltageM41: 8 BMS
 SG_ P5_CellVoltage165 : 7|13@0+ (0.001,0) [0|5] "V" VCU
 SG_ P5_CellVoltage166 : 10|13@0+ (0.001,0) [0|5] "V" VCU
 SG_ P5_CellVoltage167 : 29|13@0+ (0.001,0) [0|5] "V" VCU
 SG_ P5_CellVoltage168 : 32|13@0+ (0.001,0) [0|5] "V" VCU
 SG_ P5_BalSwCell165 : 51|1@0+ (1,0) [0|1] "" VCU
 SG_ P5_BalSwCell166 : 50|1@0+ (1,0) [0|1] "" VCU
 SG_ P5_BalSwCell167 : 49|1@0+ (1,0) [0|1] "" VCU
 SG_ P5_BalSwCell168 : 48|1@0+ (1,0) [0|1] "" VCU

BO_ 2557149269 BatP5_BMS_CellVoltageM42: 8 BMS
 SG_ P5_CellVoltage169 : 7|13@0+ (0.001,0) [0|5] "V" VCU
 SG_ P5_CellVoltage170 : 10|13@0+ (0.001,0) [0|5] "V" VCU
 SG_ P5_CellVoltage171 : 29|13@0+ (0.001,0) [0|5] "V" VCU
 SG_ P5_CellVoltage172 : 32|13@0+ (0.001,0) [0|5] "V" VCU
 SG_ P5_BalSwCell169 : 51|1@0+ (1,0) [0|1] "" VCU
 SG_ P5_BalSwCell170 : 50|1@0+ (1,0) [0|1] "" VCU
 SG_ P5_BalSwCell171 : 49|1@0+ (1,0) [0|1] "" VCU
 SG_ P5_BalSwCell172 : 48|1@0+ (1,0) [0|1] "" VCU

BO_ 2557214805 BatP5_BMS_CellVoltageM43: 8 BMS
 SG_ P5_CellVoltage173 : 7|13@0+ (0.001,0) [0|5] "V" VCU
 SG_ P5_CellVoltage174 : 10|13@0+ (0.001,0) [0|5] "V" VCU
 SG_ P5_CellVoltage175 : 29|13@0+ (0.001,0) [0|5] "V" VCU
 SG_ P5_CellVoltage176 : 32|13@0+ (0.001,0) [0|5] "V" VCU
 SG_ P5_BalSwCell173 : 51|1@0+ (1,0) [0|1] "" VCU
 SG_ P5_BalSwCell174 : 50|1@0+ (1,0) [0|1] "" VCU
 SG_ P5_BalSwCell175 : 49|1@0+ (1,0) [0|1] "" VCU
 SG_ P5_BalSwCell176 : 48|1@0+ (1,0) [0|1] "" VCU

BO_ 2557280341 BatP5_BMS_CellVoltageM44: 8 BMS
 SG_ P5_CellVoltage177 : 7|13@0+ (0.001,0) [0|5] "V" VCU
 SG_ P5_CellVoltage178 : 10|13@0+ (0.001,0) [0|5] "V" VCU
 SG_ P5_CellVoltage179 : 29|13@0+ (0.001,0) [0|5] "V" VCU
 SG_ P5_CellVoltage180 : 32|13@0+ (0.001,0) [0|5] "V" VCU
 SG_ P5_BalSwCell177 : 51|1@0+ (1,0) [0|1] "" VCU
 SG_ P5_BalSwCell178 : 50|1@0+ (1,0) [0|1] "" VCU
 SG_ P5_BalSwCell179 : 49|1@0+ (1,0) [0|1] "" VCU
 SG_ P5_BalSwCell180 : 48|1@0+ (1,0) [0|1] "" VCU

BO_ 2557345877 BatP5_BMS_CellVoltageM45: 8 BMS
 SG_ P5_CellVoltage181 : 7|13@0+ (0.001,0) [0|5] "V" VCU
 SG_ P5_CellVoltage182 : 10|13@0+ (0.001,0) [0|5] "V" VCU
 SG_ P5_CellVoltage183 : 29|13@0+ (0.001,0) [0|5] "V" VCU
 SG_ P5_CellVoltage184 : 32|13@0+ (0.001,0) [0|5] "V" VCU
 SG_ P5_BalSwCell181 : 51|1@0+ (1,0) [0|1] "" VCU
 SG_ P5_BalSwCell182 : 50|1@0+ (1,0) [0|1] "" VCU
 SG_ P5_BalSwCell183 : 49|1@0+ (1,0) [0|1] "" VCU
 SG_ P5_BalSwCell184 : 48|1@0+ (1,0) [0|1] "" VCU

BO_ 2557411413 BatP5_BMS_CellVoltageM46: 8 BMS
 SG_ P5_CellVoltage185 : 7|13@0+ (0.001,0) [0|5] "V" VCU
 SG_ P5_CellVoltage186 : 10|13@0+ (0.001,0) [0|5] "V" VCU
 SG_ P5_CellVoltage187 : 29|13@0+ (0.001,0) [0|5] "V" VCU
 SG_ P5_CellVoltage188 : 32|13@0+ (0.001,0) [0|5] "V" VCU
 SG_ P5_BalSwCell185 : 51|1@0+ (1,0) [0|1] "" VCU
 SG_ P5_BalSwCell186 : 50|1@0+ (1,0) [0|1] "" VCU
 SG_ P5_BalSwCell187 : 49|1@0+ (1,0) [0|1] "" VCU
 SG_ P5_BalSwCell188 : 48|1@0+ (1,0) [0|1] "" VCU

BO_ 2557476949 BatP5_BMS_CellVoltageM47: 8 BMS
 SG_ P5_CellVoltage189 : 7|13@0+ (0.001,0) [0|5] "V" VCU
 SG_ P5_CellVoltage190 : 10|13@0+ (0.001,0) [0|5] "V" VCU
 SG_ P5_CellVoltage191 : 29|13@0+ (0.001,0) [0|5] "V" VCU
 SG_ P5_CellVoltage192 : 32|13@0+ (0.001,0) [0|5] "V" VCU
 SG_ P5_BalSwCell189 : 51|1@0+ (1,0) [0|1] "" VCU
 SG_ P5_BalSwCell190 : 50|1@0+ (1,0) [0|1] "" VCU
 SG_ P5_BalSwCell191 : 49|1@0+ (1,0) [0|1] "" VCU
 SG_ P5_BalSwCell192 : 48|1@0+ (1,0) [0|1] "" VCU

BO_ 2558525525 BatP5_BMS_CellTempM0: 8 BMS
 SG_ P5_CellTemp1 : 7|11@0+ (0.1,-40) [-40|150] "C" VCU
 SG_ P5_CellTemp2 : 12|11@0+ (0.1,-40) [-40|150] "C" VCU
 SG_ P5_CellTemp3 : 17|11@0+ (0.1,-40) [-40|150] "C" VCU
 SG_ P5_CellTemp4 : 38|11@0+ (0.1,-40) [-40|150] "C" VCU
 SG_ P5_CellTemp5 : 43|11@0+ (0.1,-40) [-40|150] "C" VCU

BO_ 2558591061 BatP5_BMS_CellTempM1: 8 BMS
 SG_ P5_CellTemp6 : 7|11@0+ (0.1,-40) [-40|150] "C" VCU
 SG_ P5_CellTemp7 : 12|11@0+ (0.1,-40) [-40|150] "C" VCU
 SG_ P5_CellTemp8 : 17|11@0+ (0.1,-40) [-40|150] "C" VCU
 SG_ P5_CellTemp9 : 38|11@0+ (0.1,-40) [-40|150] "C" VCU
 SG_ P5_CellTemp10 : 43|11@0+ (0.1,-40) [-40|150] "C" VCU

BO_ 2558656597 BatP5_BMS_CellTempM2: 8 BMS
 SG_ P5_CellTemp11 : 7|11@0+ (0.1,-40) [-40|150] "C" VCU
 SG_ P5_CellTemp12 : 12|11@0+ (0.1,-40) [-40|150] "C" VCU
 SG_ P5_CellTemp13 : 17|11@0+ (0.1,-40) [-40|150] "C" VCU
 SG_ P5_CellTemp14 : 38|11@0+ (0.1,-40) [-40|150] "C" VCU
 SG_ P5_CellTemp15 : 43|11@0+ (0.1,-40) [-40|150] "C" VCU

BO_ 2558722133 BatP5_BMS_CellTempM3: 8 BMS
 SG_ P5_CellTemp16 : 7|11@0+ (0.1,-40) [-40|150] "C" VCU
 SG_ P5_CellTemp17 : 12|11@0+ (0.1,-40) [-40|150] "C" VCU
 SG_ P5_CellTemp18 : 17|11@0+ (0.1,-40) [-40|150] "C" VCU
 SG_ P5_CellTemp19 : 38|11@0+ (0.1,-40) [-40|150] "C" VCU
 SG_ P5_CellTemp20 : 43|11@0+ (0.1,-40) [-40|150] "C" VCU

BO_ 2558787669 BatP5_BMS_CellTempM4: 8 BMS
 SG_ P5_CellTemp21 : 7|11@0+ (0.1,-40) [-40|150] "C" VCU
 SG_ P5_CellTemp22 : 12|11@0+ (0.1,-40) [-40|150] "C" VCU
 SG_ P5_CellTemp23 : 17|11@0+ (0.1,-40) [-40|150] "C" VCU
 SG_ P5_CellTemp24 : 38|11@0+ (0.1,-40) [-40|150] "C" VCU
 SG_ P5_CellTemp25 : 43|11@0+ (0.1,-40) [-40|150] "C" VCU

BO_ 2558853205 BatP5_BMS_CellTempM5: 8 BMS
 SG_ P5_CellTemp26 : 7|11@0+ (0.1,-40) [-40|150] "C" VCU
 SG_ P5_CellTemp27 : 12|11@0+ (0.1,-40) [-40|150] "C" VCU
 SG_ P5_CellTemp28 : 17|11@0+ (0.1,-40) [-40|150] "C" VCU
 SG_ P5_CellTemp29 : 38|11@0+ (0.1,-40) [-40|150] "C" VCU
 SG_ P5_CellTemp30 : 43|11@0+ (0.1,-40) [-40|150] "C" VCU

BO_ 2558918741 BatP5_BMS_CellTempM6: 8 BMS
 SG_ P5_CellTemp31 : 7|11@0+ (0.1,-40) [-40|150] "C" VCU
 SG_ P5_CellTemp32 : 12|11@0+ (0.1,-40) [-40|150] "C" VCU
 SG_ P5_CellTemp33 : 17|11@0+ (0.1,-40) [-40|150] "C" VCU
 SG_ P5_CellTemp34 : 38|11@0+ (0.1,-40) [-40|150] "C" VCU
 SG_ P5_CellTemp35 : 43|11@0+ (0.1,-40) [-40|150] "C" VCU

BO_ 2558984277 BatP5_BMS_CellTempM7: 8 BMS
 SG_ P5_CellTemp36 : 7|11@0+ (0.1,-40) [-40|150] "C" VCU
 SG_ P5_CellTemp37 : 12|11@0+ (0.1,-40) [-40|150] "C" VCU
 SG_ P5_CellTemp38 : 17|11@0+ (0.1,-40) [-40|150] "C" VCU
 SG_ P5_CellTemp39 : 38|11@0+ (0.1,-40) [-40|150] "C" VCU
 SG_ P5_CellTemp40 : 43|11@0+ (0.1,-40) [-40|150] "C" VCU

BO_ 2559049813 BatP5_BMS_CellTempM8: 8 BMS
 SG_ P5_CellTemp41 : 7|11@0+ (0.1,-40) [-40|150] "C" VCU
 SG_ P5_CellTemp42 : 12|11@0+ (0.1,-40) [-40|150] "C" VCU
 SG_ P5_CellTemp43 : 17|11@0+ (0.1,-40) [-40|150] "C" VCU
 SG_ P5_CellTemp44 : 38|11@0+ (0.1,-40) [-40|150] "C" VCU
 SG_ P5_CellTemp45 : 43|11@0+ (0.1,-40) [-40|150] "C" VCU

BO_ 2559115349 BatP5_BMS_CellTempM9: 8 BMS
 SG_ P5_CellTemp46 : 7|11@0+ (0.1,-40) [-40|150] "C" VCU
 SG_ P5_CellTemp47 : 12|11@0+ (0.1,-40) [-40|150] "C" VCU
 SG_ P5_CellTemp48 : 17|11@0+ (0.1,-40) [-40|150] "C" VCU
 SG_ P5_CellTemp49 : 38|11@0+ (0.1,-40) [-40|150] "C" VCU
 SG_ P5_CellTemp50 : 43|11@0+ (0.1,-40) [-40|150] "C" VCU

BO_ 2559180885 BatP5_BMS_CellTempM10: 8 BMS
 SG_ P5_CellTemp51 : 7|11@0+ (0.1,-40) [-40|150] "C" VCU
 SG_ P5_CellTemp52 : 12|11@0+ (0.1,-40) [-40|150] "C" VCU
 SG_ P5_CellTemp53 : 17|11@0+ (0.1,-40) [-40|150] "C" VCU
 SG_ P5_CellTemp54 : 38|11@0+ (0.1,-40) [-40|150] "C" VCU
 SG_ P5_CellTemp55 : 43|11@0+ (0.1,-40) [-40|150] "C" VCU

BO_ 2559246421 BatP5_BMS_CellTempM11: 8 BMS
 SG_ P5_CellTemp56 : 7|11@0+ (0.1,-40) [-40|150] "C" VCU
 SG_ P5_CellTemp57 : 12|11@0+ (0.1,-40) [-40|150] "C" VCU
 SG_ P5_CellTemp58 : 17|11@0+ (0.1,-40) [-40|150] "C" VCU
 SG_ P5_CellTemp59 : 38|11@0+ (0.1,-40) [-40|150] "C" VCU
 SG_ P5_CellTemp60 : 43|11@0+ (0.1,-40) [-40|150] "C" VCU

BO_ 2559311957 BatP5_BMS_CellTempM12: 8 BMS
 SG_ P5_CellTemp61 : 7|11@0+ (0.1,-40) [-40|150] "C" VCU
 SG_ P5_CellTemp62 : 12|11@0+ (0.1,-40) [-40|150] "C" VCU
 SG_ P5_CellTemp63 : 17|11@0+ (0.1,-40) [-40|150] "C" VCU
 SG_ P5_CellTemp64 : 38|11@0+ (0.1,-40) [-40|150] "C" VCU
 SG_ P5_CellTemp65 : 43|11@0+ (0.1,-40) [-40|150] "C" VCU

BO_ 2559377493 BatP5_BMS_CellTempM13: 8 BMS
 SG_ P5_CellTemp66 : 7|11@0+ (0.1,-40) [-40|150] "C" VCU
 SG_ P5_CellTemp67 : 12|11@0+ (0.1,-40) [-40|150] "C" VCU
 SG_ P5_CellTemp68 : 17|11@0+ (0.1,-40) [-40|150] "C" VCU
 SG_ P5_CellTemp69 : 38|11@0+ (0.1,-40) [-40|150] "C" VCU
 SG_ P5_CellTemp70 : 43|11@0+ (0.1,-40) [-40|150] "C" VCU

BO_ 2559443029 BatP5_BMS_CellTempM14: 8 BMS
 SG_ P5_CellTemp71 : 7|11@0+ (0.1,-40) [-40|150] "C" VCU
 SG_ P5_CellTemp72 : 12|11@0+ (0.1,-40) [-40|150] "C" VCU
 SG_ P5_CellTemp73 : 17|11@0+ (0.1,-40) [-40|150] "C" VCU
 SG_ P5_CellTemp74 : 38|11@0+ (0.1,-40) [-40|150] "C" VCU
 SG_ P5_CellTemp75 : 43|11@0+ (0.1,-40) [-40|150] "C" VCU

BO_ 2559508565 BatP5_BMS_CellTempM15: 8 BMS
 SG_ P5_CellTemp76 : 7|11@0+ (0.1,-40) [-40|150] "C" VCU
 SG_ P5_CellTemp77 : 12|11@0+ (0.1,-40) [-40|150] "C" VCU
 SG_ P5_CellTemp78 : 17|11@0+ (0.1,-40) [-40|150] "C" VCU
 SG_ P5_CellTemp79 : 38|11@0+ (0.1,-40) [-40|150] "C" VCU
 SG_ P5_CellTemp80 : 43|11@0+ (0.1,-40) [-40|150] "C" VCU

BO_ 2559574101 BatP5_BMS_CellTempM16: 8 BMS
 SG_ P5_CellTemp81 : 7|11@0+ (0.1,-40) [-40|150] "C" VCU
 SG_ P5_CellTemp82 : 12|11@0+ (0.1,-40) [-40|150] "C" VCU
 SG_ P5_CellTemp83 : 17|11@0+ (0.1,-40) [-40|150] "C" VCU
 SG_ P5_CellTemp84 : 38|11@0+ (0.1,-40) [-40|150] "C" VCU
 SG_ P5_CellTemp85 : 43|11@0+ (0.1,-40) [-40|150] "C" VCU

BO_ 2559639637 BatP5_BMS_CellTempM17: 8 BMS
 SG_ P5_CellTemp86 : 7|11@0+ (0.1,-40) [-40|150] "C" VCU
 SG_ P5_CellTemp87 : 12|11@0+ (0.1,-40) [-40|150] "C" VCU
 SG_ P5_CellTemp88 : 17|11@0+ (0.1,-40) [-40|150] "C" VCU
 SG_ P5_CellTemp89 : 38|11@0+ (0.1,-40) [-40|150] "C" VCU
 SG_ P5_CellTemp90 : 43|11@0+ (0.1,-40) [-40|150] "C" VCU

BO_ 2559705173 BatP5_BMS_CellTempM18: 8 BMS
 SG_ P5_CellTemp91 : 7|11@0+ (0.1,-40) [-40|150] "C" VCU
 SG_ P5_CellTemp92 : 12|11@0+ (0.1,-40) [-40|150] "C" VCU
 SG_ P5_CellTemp93 : 17|11@0+ (0.1,-40) [-40|150] "C" VCU
 SG_ P5_CellTemp94 : 38|11@0+ (0.1,-40) [-40|150] "C" VCU
 SG_ P5_CellTemp95 : 43|11@0+ (0.1,-40) [-40|150] "C" VCU

BO_ 2559770709 BatP5_BMS_CellTempM19: 8 BMS
 SG_ P5_CellTemp96 : 7|11@0+ (0.1,-40) [-40|150] "C" VCU
 SG_ P5_CellTemp97 : 12|11@0+ (0.1,-40) [-40|150] "C" VCU
 SG_ P5_CellTemp98 : 17|11@0+ (0.1,-40) [-40|150] "C" VCU
 SG_ P5_CellTemp99 : 38|11@0+ (0.1,-40) [-40|150] "C" VCU
 SG_ P5_CellTemp100 : 43|11@0+ (0.1,-40) [-40|150] "C" VCU

BO_ 2559836245 BatP5_BMS_CellTempM20: 8 BMS
 SG_ P5_CellTemp101 : 7|11@0+ (0.1,-40) [-40|150] "C" VCU
 SG_ P5_CellTemp102 : 12|11@0+ (0.1,-40) [-40|150] "C" VCU
 SG_ P5_CellTemp103 : 17|11@0+ (0.1,-40) [-40|150] "C" VCU
 SG_ P5_CellTemp104 : 38|11@0+ (0.1,-40) [-40|150] "C" VCU
 SG_ P5_CellTemp105 : 43|11@0+ (0.1,-40) [-40|150] "C" VCU

BO_ 2559901781 BatP5_BMS_CellTempM21: 8 BMS
 SG_ P5_CellTemp106 : 7|11@0+ (0.1,-40) [-40|150] "C" VCU
 SG_ P5_CellTemp107 : 12|11@0+ (0.1,-40) [-40|150] "C" VCU
 SG_ P5_CellTemp108 : 17|11@0+ (0.1,-40) [-40|150] "C" VCU
 SG_ P5_CellTemp109 : 38|11@0+ (0.1,-40) [-40|150] "C" VCU
 SG_ P5_CellTemp110 : 43|11@0+ (0.1,-40) [-40|150] "C" VCU

BO_ 2559967317 BatP5_BMS_CellTempM22: 8 BMS
 SG_ P5_CellTemp111 : 7|11@0+ (0.1,-40) [-40|150] "C" VCU
 SG_ P5_CellTemp112 : 12|11@0+ (0.1,-40) [-40|150] "C" VCU
 SG_ P5_CellTemp113 : 17|11@0+ (0.1,-40) [-40|150] "C" VCU
 SG_ P5_CellTemp114 : 38|11@0+ (0.1,-40) [-40|150] "C" VCU
 SG_ P5_CellTemp115 : 43|11@0+ (0.1,-40) [-40|150] "C" VCU

BO_ 2560032853 BatP5_BMS_CellTempM23: 8 BMS
 SG_ P5_CellTemp116 : 7|11@0+ (0.1,-40) [-40|150] "C" VCU
 SG_ P5_CellTemp117 : 12|11@0+ (0.1,-40) [-40|150] "C" VCU
 SG_ P5_CellTemp118 : 17|11@0+ (0.1,-40) [-40|150] "C" VCU
 SG_ P5_CellTemp119 : 38|11@0+ (0.1,-40) [-40|150] "C" VCU
 SG_ P5_CellTemp120 : 43|11@0+ (0.1,-40) [-40|150] "C" VCU

BO_ 2560098389 BatP5_BMS_CellTempM24: 8 BMS
 SG_ P5_CellTemp121 : 7|11@0+ (0.1,-40) [-40|150] "C" VCU
 SG_ P5_CellTemp122 : 12|11@0+ (0.1,-40) [-40|150] "C" VCU
 SG_ P5_CellTemp123 : 17|11@0+ (0.1,-40) [-40|150] "C" VCU
 SG_ P5_CellTemp124 : 38|11@0+ (0.1,-40) [-40|150] "C" VCU
 SG_ P5_CellTemp125 : 43|11@0+ (0.1,-40) [-40|150] "C" VCU

BO_ 2560163925 BatP5_BMS_CellTempM25: 8 BMS
 SG_ P5_CellTemp126 : 7|11@0+ (0.1,-40) [-40|150] "C" VCU
 SG_ P5_CellTemp127 : 12|11@0+ (0.1,-40) [-40|150] "C" VCU
 SG_ P5_CellTemp128 : 17|11@0+ (0.1,-40) [-40|150] "C" VCU
 SG_ P5_CellTemp129 : 38|11@0+ (0.1,-40) [-40|150] "C" VCU
 SG_ P5_CellTemp130 : 43|11@0+ (0.1,-40) [-40|150] "C" VCU

BO_ 2560229461 BatP5_BMS_CellTempM26: 8 BMS
 SG_ P5_CellTemp131 : 7|11@0+ (0.1,-40) [-40|150] "C" VCU
 SG_ P5_CellTemp132 : 12|11@0+ (0.1,-40) [-40|150] "C" VCU
 SG_ P5_CellTemp133 : 17|11@0+ (0.1,-40) [-40|150] "C" VCU
 SG_ P5_CellTemp134 : 38|11@0+ (0.1,-40) [-40|150] "C" VCU
 SG_ P5_CellTemp135 : 43|11@0+ (0.1,-40) [-40|150] "C" VCU

BO_ 2560294997 BatP5_BMS_CellTempM27: 8 BMS
 SG_ P5_CellTemp136 : 7|11@0+ (0.1,-40) [-40|150] "C" VCU
 SG_ P5_CellTemp137 : 12|11@0+ (0.1,-40) [-40|150] "C" VCU
 SG_ P5_CellTemp138 : 17|11@0+ (0.1,-40) [-40|150] "C" VCU
 SG_ P5_CellTemp139 : 38|11@0+ (0.1,-40) [-40|150] "C" VCU
 SG_ P5_CellTemp140 : 43|11@0+ (0.1,-40) [-40|150] "C" VCU

BO_ 2560360533 BatP5_BMS_CellTempM28: 8 BMS
 SG_ P5_CellTemp141 : 7|11@0+ (0.1,-40) [-40|150] "C" VCU
 SG_ P5_CellTemp142 : 12|11@0+ (0.1,-40) [-40|150] "C" VCU
 SG_ P5_CellTemp143 : 17|11@0+ (0.1,-40) [-40|150] "C" VCU
 SG_ P5_CellTemp144 : 38|11@0+ (0.1,-40) [-40|150] "C" VCU
 SG_ P5_CellTemp145 : 43|11@0+ (0.1,-40) [-40|150] "C" VCU

BO_ 2560426069 BatP5_BMS_CellTempM29: 8 BMS
 SG_ P5_CellTemp146 : 7|11@0+ (0.1,-40) [-40|150] "C" VCU
 SG_ P5_CellTemp147 : 12|11@0+ (0.1,-40) [-40|150] "C" VCU
 SG_ P5_CellTemp148 : 17|11@0+ (0.1,-40) [-40|150] "C" VCU
 SG_ P5_CellTemp149 : 38|11@0+ (0.1,-40) [-40|150] "C" VCU
 SG_ P5_CellTemp150 : 43|11@0+ (0.1,-40) [-40|150] "C" VCU

BO_ 2560491605 BatP5_BMS_CellTempM30: 8 BMS
 SG_ P5_CellTemp151 : 7|11@0+ (0.1,-40) [-40|150] "C" VCU
 SG_ P5_CellTemp152 : 12|11@0+ (0.1,-40) [-40|150] "C" VCU
 SG_ P5_CellTemp153 : 17|11@0+ (0.1,-40) [-40|150] "C" VCU
 SG_ P5_CellTemp154 : 38|11@0+ (0.1,-40) [-40|150] "C" VCU
 SG_ P5_CellTemp155 : 43|11@0+ (0.1,-40) [-40|150] "C" VCU

BO_ 2560557141 BatP5_BMS_CellTempM31: 8 BMS
 SG_ P5_CellTemp156 : 7|11@0+ (0.1,-40) [-40|150] "C" VCU
 SG_ P5_CellTemp157 : 12|11@0+ (0.1,-40) [-40|150] "C" VCU
 SG_ P5_CellTemp158 : 17|11@0+ (0.1,-40) [-40|150] "C" VCU
 SG_ P5_CellTemp159 : 38|11@0+ (0.1,-40) [-40|150] "C" VCU
 SG_ P5_CellTemp160 : 43|11@0+ (0.1,-40) [-40|150] "C" VCU

BO_ 2560622677 BatP5_BMS_CellTempM32: 8 BMS
 SG_ P5_CellTemp161 : 7|11@0+ (0.1,-40) [-40|150] "C" VCU
 SG_ P5_CellTemp162 : 12|11@0+ (0.1,-40) [-40|150] "C" VCU
 SG_ P5_CellTemp163 : 17|11@0+ (0.1,-40) [-40|150] "C" VCU
 SG_ P5_CellTemp164 : 38|11@0+ (0.1,-40) [-40|150] "C" VCU
 SG_ P5_CellTemp165 : 43|11@0+ (0.1,-40) [-40|150] "C" VCU

BO_ 2560688213 BatP5_BMS_CellTempM33: 8 BMS
 SG_ P5_CellTemp166 : 7|11@0+ (0.1,-40) [-40|150] "C" VCU
 SG_ P5_CellTemp167 : 12|11@0+ (0.1,-40) [-40|150] "C" VCU
 SG_ P5_CellTemp168 : 17|11@0+ (0.1,-40) [-40|150] "C" VCU
 SG_ P5_CellTemp169 : 38|11@0+ (0.1,-40) [-40|150] "C" VCU
 SG_ P5_CellTemp170 : 43|11@0+ (0.1,-40) [-40|150] "C" VCU

BO_ 2560753749 BatP5_BMS_CellTempM34: 8 BMS
 SG_ P5_CellTemp171 : 7|11@0+ (0.1,-40) [-40|150] "C" VCU
 SG_ P5_CellTemp172 : 12|11@0+ (0.1,-40) [-40|150] "C" VCU
 SG_ P5_CellTemp173 : 17|11@0+ (0.1,-40) [-40|150] "C" VCU
 SG_ P5_CellTemp174 : 38|11@0+ (0.1,-40) [-40|150] "C" VCU
 SG_ P5_CellTemp175 : 43|11@0+ (0.1,-40) [-40|150] "C" VCU

BO_ 2560819285 BatP5_BMS_CellTempM35: 8 BMS
 SG_ P5_CellTemp176 : 7|11@0+ (0.1,-40) [-40|150] "C" VCU
 SG_ P5_CellTemp177 : 12|11@0+ (0.1,-40) [-40|150] "C" VCU
 SG_ P5_CellTemp178 : 17|11@0+ (0.1,-40) [-40|150] "C" VCU
 SG_ P5_CellTemp179 : 38|11@0+ (0.1,-40) [-40|150] "C" VCU
 SG_ P5_CellTemp180 : 43|11@0+ (0.1,-40) [-40|150] "C" VCU

BO_ 2560884821 BatP5_BMS_CellTempM36: 8 BMS
 SG_ P5_CellTemp181 : 7|11@0+ (0.1,-40) [-40|150] "C" VCU
 SG_ P5_CellTemp182 : 12|11@0+ (0.1,-40) [-40|150] "C" VCU
 SG_ P5_CellTemp183 : 17|11@0+ (0.1,-40) [-40|150] "C" VCU
 SG_ P5_CellTemp184 : 38|11@0+ (0.1,-40) [-40|150] "C" VCU
 SG_ P5_CellTemp185 : 43|11@0+ (0.1,-40) [-40|150] "C" VCU

BO_ 2560950357 BatP5_BMS_CellTempM37: 8 BMS
 SG_ P5_CellTemp186 : 7|11@0+ (0.1,-40) [-40|150] "C" VCU
 SG_ P5_CellTemp187 : 12|11@0+ (0.1,-40) [-40|150] "C" VCU
 SG_ P5_CellTemp188 : 17|11@0+ (0.1,-40) [-40|150] "C" VCU
 SG_ P5_CellTemp189 : 38|11@0+ (0.1,-40) [-40|150] "C" VCU
 SG_ P5_CellTemp190 : 43|11@0+ (0.1,-40) [-40|150] "C" VCU

BO_ 2561015893 BatP5_BMS_CellTempM38: 8 BMS
 SG_ P5_CellTemp191 : 7|11@0+ (0.1,-40) [-40|150] "C" VCU
 SG_ P5_CellTemp192 : 12|11@0+ (0.1,-40) [-40|150] "C" VCU
 SG_ P5_DatLen16DbgInfo1 : 7|16@0+ (1,0) [0|65535] "" VCU
 SG_ P5_DatLen16DbgInfo2 : 23|16@0+ (1,0) [0|65535] "" VCU
 SG_ P5_DatLen16DbgInfo3 : 39|16@0+ (1,0) [0|65535] "" VCU
 SG_ P5_DatLen16DbgInfo4 : 55|16@0+ (1,0) [0|65535] "" VCU

BO_ 2550399078 BatP6_BMS_PowerSupplyInfo: 8 BMS
 SG_ P6_BMSPwrSuplVlt1 : 7|9@0+ (0.1,0) [0|50] "V" VCU
 SG_ P6_BMSPwrSuplVlt2 : 14|9@0+ (0.1,0) [0|50] "V" VCU
 SG_ P6_ChrgStationAuxPwrSuplVlt : 21|9@0+ (0.1,0) [0|50] "V" VCU
 SG_ P6_BMSKL15ON : 28|1@0+ (1,0) [0|1] "" VCU
 SG_ P6_DCStepState : 27|8@0+ (1,0) [0|255] "" VCU
 SG_ P6_ExtLvWakeup_28VOnly : 35|9@0+ (0.1,0) [0|50] "V" VCU

BO_ 2550464614 BatP6_BMS_PackUsageLimit: 8 BMS
 SG_ P6_PackVltUprLmt : 7|14@0+ (0.1,0) [0|1200] "V" VCU
 SG_ P6_PackVltLoLmt : 9|14@0+ (0.1,0) [0|1200] "V" VCU
 SG_ P6_PackMaxDschrgCrnt : 27|14@0+ (0.1,0) [0|1600] "A" VCU
 SG_ P6_PackMaxChrgCrnt : 45|14@0+ (0.1,0) [0|1600] "A" VCU

BO_ 2550530150 BatP6_BMS_PackPowerCapability: 8 BMS
 SG_ P6_PackDschrgPwrLmt : 7|10@0+ (1,0) [0|1000] "kW" VCU
 SG_ P6_PackDschrgPwrStat : 13|2@0+ (1,0) [0|3] "" VCU
 SG_ P6_PackChrgPwrLmt : 11|10@0+ (1,0) [0|1000] "kW" VCU
 SG_ P6_PackChrgPwrStat : 17|2@0+ (1,0) [0|3] "" VCU

BO_ 2550595686 BatP6_BMS_ChargingInfo: 8 BMS
 SG_ P6_ChrgrCplrStat : 7|1@0+ (1,0) [0|1] "" VCU
 SG_ P6_HVBattChrgSysStatus : 6|4@0+ (1,0) [0|15] "" VCU
 SG_ P6_DCChrgCrntCmd : 2|9@0+ (1,0) [0|500] "A" VCU
 SG_ P6_CC2Vlt : 9|8@0+ (0.1,0) [0|25] "V" VCU
 SG_ P6_DCRcptPosTemp : 17|9@0+ (0.5,-40) [-40|150] "C" VCU
 SG_ P6_DCRcptNegTemp : 24|9@0+ (0.5,-40) [-40|150] "C" VCU
 SG_ P6_Tm2FullChrg : 47|14@0+ (1,0) [0|65535] "min" VCU

BO_ 2550661222 BatP6_BMS_ThermalManagement: 8 BMS
 SG_ P6_Inlet1ClntTemp : 7|11@0+ (0.1,-40) [-40|150] "C" VCU
 SG_ P6_Inlet2ClntTemp : 12|11@0+ (0.1,-40) [-40|150] "C" VCU
 SG_ P6_Outlet1ClntTemp : 17|11@0+ (0.1,-40) [-40|150] "C" VCU
 SG_ P6_Outlet2ClntTemp : 38|11@0+ (0.1,-40) [-40|150] "C" VCU
 SG_ P6_TrgtClntTemp : 43|11@0+ (0.1,-40) [-40|150] "C" VCU
 SG_ P6_TrgtClntFlowRate : 48|9@0+ (0.2,0) [0|100] "C" VCU

BO_ 2550726758 BatP6_BMS_CellVoltMaxMin: 8 BMS
 SG_ P6_MaxCellVlt : 7|13@0+ (0.001,0) [0|5] "V" VCU
 SG_ P6_MaxCellVltNum : 10|9@0+ (1,0) [0|500] "" VCU
 SG_ P6_MinCellVlt : 17|13@0+ (0.001,0) [0|5] "V" VCU
 SG_ P6_MinCellVltNum : 36|9@0+ (1,0) [0|500] "" VCU
 SG_ P6_AvgCellVlt : 43|13@0+ (0.001,0) [0|5] "V" VCU

BO_ 2550792294 BatP6_BMS_CellTempMaxMin: 8 BMS
 SG_ P6_MaxCellTemp : 7|11@0+ (0.1,-40) [-40|150] "C" VCU
 SG_ P6_MaxCellTempNum : 12|9@0+ (1,0) [0|500] "" VCU
 SG_ P6_MinCellTemp : 19|11@0+ (0.1,-40) [-40|150] "C" VCU
 SG_ P6_MinCellTempNum : 24|9@0+ (1,0) [0|500] "" VCU
 SG_ P6_AvgCellTemp : 47|11@0+ (0.1,-40) [-40|150] "C" VCU

BO_ 2550857830 BatP6_BMS_PackFaultInfo1: 8 BMS
 SG_ P6_PackTotFltNum : 7|8@0+ (1,0) [0|200] "" VCU
 SG_ P6_CellOverVoltage : 15|2@0+ (1,0) [0|3] "" VCU
 SG_ P6_CellUnderVoltage : 13|2@0+ (1,0) [0|3] "" VCU
 SG_ P6_CellVoltageDiffHi : 11|1@0+ (1,0) [0|1] "" VCU
 SG_ P6_PackOverVoltage : 10|2@0+ (1,0) [0|3] "" VCU
 SG_ P6_PackUnderVoltage : 8|2@0+ (1,0) [0|3] "" VCU
 SG_ P6_CellOverTemp : 22|2@0+ (1,0) [0|3] "" VCU
 SG_ P6_CellTempLow : 20|1@0+ (1,0) [0|1] "" VCU
 SG_ P6_CellTempDiffHi : 19|1@0+ (1,0) [0|1] "" VCU
 SG_ P6_PackDschrgCrntHi : 18|2@0+ (1,0) [0|3] "" VCU
 SG_ P6_PackChrgCrntHi : 16|2@0+ (1,0) [0|3] "" VCU
 SG_ P6_PackCrnSnsr1OffsetHi : 30|1@0+ (1,0) [0|1] "" VCU
 SG_ P6_HVIsolFlt : 29|2@0+ (1,0) [0|3] "" VCU
 SG_ P6_HVILFlt : 27|1@0+ (1,0) [0|1] "" VCU
 SG_ P6_ThrmlRunaway : 26|1@0+ (1,0) [0|1] "" VCU
 SG_ P6_CellVoltInvalid : 25|1@0+ (1,0) [0|1] "" VCU
 SG_ P6_CellTempInvalid : 24|1@0+ (1,0) [0|1] "" VCU
 SG_ P6_DaisyChainComFlt : 39|1@0+ (1,0) [0|1] "" VCU
 SG_ P6_PackVoltRatFlt : 38|1@0+ (1,0) [0|1] "" VCU
 SG_ P6_CrntSnsr1Invalid : 37|1@0+ (1,0) [0|1] "" VCU
 SG_ P6_CrntSnsr1OOR : 36|1@0+ (1,0) [0|1] "" VCU
 SG_ P6_CrntSnsr2Invalid : 35|1@0+ (1,0) [0|1] "" VCU
 SG_ P6_CrntSnsr2OOR : 34|1@0+ (1,0) [0|1] "" VCU
 SG_ P6_PackCrnSnsr2OffsetHi : 33|1@0+ (1,0) [0|1] "" VCU
 SG_ P6_OutofEnergy : 32|1@0+ (1,0) [0|1] "" VCU
 SG_ P6_IsolDetCircErr : 47|1@0+ (1,0) [0|1] "" VCU
 SG_ P6_HVILCircShortToGND : 46|1@0+ (1,0) [0|1] "" VCU
 SG_ P6_HVILCircShortToPwr : 45|1@0+ (1,0) [0|1] "" VCU

BO_ 2550923366 BatP6_BMS_PackFaultInfo2: 8 BMS
 SG_ P6_MainPosCntctrStkClsd : 7|1@0+ (1,0) [0|1] "" VCU
 SG_ P6_MainPosCntctrStkOpn : 6|1@0+ (1,0) [0|1] "" VCU
 SG_ P6_MainNegCntctr1StkClsd : 5|1@0+ (1,0) [0|1] "" VCU
 SG_ P6_MainNegCntctr1StkOpn : 4|1@0+ (1,0) [0|1] "" VCU
 SG_ P6_MainNegCntctr2StkClsd : 3|1@0+ (1,0) [0|1] "" VCU
 SG_ P6_MainNegCntctr2StkOpn : 2|1@0+ (1,0) [0|1] "" VCU
 SG_ P6_PrechargTmOut : 1|1@0+ (1,0) [0|1] "" VCU
 SG_ P6_PrechrgCrntHi : 0|1@0+ (1,0) [0|1] "" VCU
 SG_ P6_ChrgCplrPosTempHi : 15|1@0+ (1,0) [0|1] "" VCU
 SG_ P6_ChrgCplrNegTempHi : 14|1@0+ (1,0) [0|1] "" VCU
 SG_ P6_BMSPwrSuplVlt1Hi : 13|1@0+ (1,0) [0|1] "" VCU
 SG_ P6_BMSPwrSuplVlt1Lo : 12|1@0+ (1,0) [0|1] "" VCU
 SG_ P6_BMSPwrSuplVlt2Hi : 11|1@0+ (1,0) [0|1] "" VCU
 SG_ P6_BMSPwrSuplVlt2Lo : 10|1@0+ (1,0) [0|1] "" VCU
 SG_ P6_CntctrCirPwrSuplVltLo : 9|1@0+ (1,0) [0|1] "" VCU
 SG_ P6_CntctrCirPwrSuplVltHi : 8|1@0+ (1,0) [0|1] "" VCU
 SG_ P6_CAN1BusOff : 23|1@0+ (1,0) [0|1] "" VCU
 SG_ P6_CAN1BusTmOut : 22|1@0+ (1,0) [0|1] "" VCU
 SG_ P6_CAN2BusOff : 21|1@0+ (1,0) [0|1] "" VCU
 SG_ P6_CAN2BusTmOut : 20|1@0+ (1,0) [0|1] "" VCU
 SG_ P6_CellBalCircTempHi : 19|1@0+ (1,0) [0|1] "" VCU
 SG_ P6_ClntInTempHi : 18|1@0+ (1,0) [0|1] "" VCU
 SG_ P6_ClntOutTempHi : 17|1@0+ (1,0) [0|1] "" VCU
 SG_ P6_CellExtrmUdrVolt : 16|1@0+ (1,0) [0|1] "" VCU
 SG_ P6_CellExtrmOvrVolt : 31|1@0+ (1,0) [0|1] "" VCU
 SG_ P6_Branch1DischrgCrntHi  : 30|1@0+ (1,0) [0|1] "" VCU
 SG_ P6_Branch2DischrgCrntHi  : 29|1@0+ (1,0) [0|1] "" VCU
 SG_ P6_Branch1ChrgCrntHi  : 28|1@0+ (1,0) [0|1] "" VCU
 SG_ P6_Branch2ChrgCrntHi  : 27|1@0+ (1,0) [0|1] "" VCU
 SG_ P6_InitFailed : 26|1@0+ (1,0) [0|1] "" VCU
 SG_ P6_PackErrCode : 25|10@0+ (1,0) [0|1023] "" VCU

BO_ 2550988902 BatP6_BMS_PackConfigInfo: 8 BMS
 SG_ P6_PackTotCellNum : 7|9@0+ (1,0) [0|500] "" VCU
 SG_ P6_PackTotCellTempSnsrNum : 14|9@0+ (1,0) [0|500] "" VCU

BO_ 2552299622 BatP6_BMS_BMSVersion: 8 BMS
 SG_ P6_BMSASWMajVerNum : 7|8@0+ (1,0) [0|9] "" VCU
 SG_ P6_BMSASWMinVerNum : 15|8@0+ (1,0) [0|99] "" VCU
 SG_ P6_BMSASWPatchVerNum : 23|8@0+ (1,0) [0|255] "" VCU
 SG_ P6_BMSBSWMajVerNum : 31|8@0+ (1,0) [0|9] "" VCU
 SG_ P6_BMSBSWMinVerNum : 39|8@0+ (1,0) [0|99] "" VCU
 SG_ P6_BMSBSWPatchVerNum : 47|8@0+ (1,0) [0|255] "" VCU

BO_ 2554396774 BatP6_BMS_CellVoltageM0: 8 BMS
 SG_ P6_CellVoltage1 : 7|13@0+ (0.001,0) [0|5] "V" VCU
 SG_ P6_CellVoltage2 : 10|13@0+ (0.001,0) [0|5] "V" VCU
 SG_ P6_CellVoltage3 : 29|13@0+ (0.001,0) [0|5] "V" VCU
 SG_ P6_CellVoltage4 : 32|13@0+ (0.001,0) [0|5] "V" VCU
 SG_ P6_BalSwCell1 : 51|1@0+ (1,0) [0|1] "" VCU
 SG_ P6_BalSwCell2 : 50|1@0+ (1,0) [0|1] "" VCU
 SG_ P6_BalSwCell3 : 49|1@0+ (1,0) [0|1] "" VCU
 SG_ P6_BalSwCell4 : 48|1@0+ (1,0) [0|1] "" VCU

BO_ 2554462310 BatP6_BMS_CellVoltageM1: 8 BMS
 SG_ P6_CellVoltage5 : 7|13@0+ (0.001,0) [0|5] "V" VCU
 SG_ P6_CellVoltage6 : 10|13@0+ (0.001,0) [0|5] "V" VCU
 SG_ P6_CellVoltage7 : 29|13@0+ (0.001,0) [0|5] "V" VCU
 SG_ P6_CellVoltage8 : 32|13@0+ (0.001,0) [0|5] "V" VCU
 SG_ P6_BalSwCell5 : 51|1@0+ (1,0) [0|1] "" VCU
 SG_ P6_BalSwCell6 : 50|1@0+ (1,0) [0|1] "" VCU
 SG_ P6_BalSwCell7 : 49|1@0+ (1,0) [0|1] "" VCU
 SG_ P6_BalSwCell8 : 48|1@0+ (1,0) [0|1] "" VCU

BO_ 2554527846 BatP6_BMS_CellVoltageM2: 8 BMS
 SG_ P6_CellVoltage9 : 7|13@0+ (0.001,0) [0|5] "V" VCU
 SG_ P6_CellVoltage10 : 10|13@0+ (0.001,0) [0|5] "V" VCU
 SG_ P6_CellVoltage11 : 29|13@0+ (0.001,0) [0|5] "V" VCU
 SG_ P6_CellVoltage12 : 32|13@0+ (0.001,0) [0|5] "V" VCU
 SG_ P6_BalSwCell9 : 51|1@0+ (1,0) [0|1] "" VCU
 SG_ P6_BalSwCell10 : 50|1@0+ (1,0) [0|1] "" VCU
 SG_ P6_BalSwCell11 : 49|1@0+ (1,0) [0|1] "" VCU
 SG_ P6_BalSwCell12 : 48|1@0+ (1,0) [0|1] "" VCU

BO_ 2554593382 BatP6_BMS_CellVoltageM3: 8 BMS
 SG_ P6_CellVoltage13 : 7|13@0+ (0.001,0) [0|5] "V" VCU
 SG_ P6_CellVoltage14 : 10|13@0+ (0.001,0) [0|5] "V" VCU
 SG_ P6_CellVoltage15 : 29|13@0+ (0.001,0) [0|5] "V" VCU
 SG_ P6_CellVoltage16 : 32|13@0+ (0.001,0) [0|5] "V" VCU
 SG_ P6_BalSwCell13 : 51|1@0+ (1,0) [0|1] "" VCU
 SG_ P6_BalSwCell14 : 50|1@0+ (1,0) [0|1] "" VCU
 SG_ P6_BalSwCell15 : 49|1@0+ (1,0) [0|1] "" VCU
 SG_ P6_BalSwCell16 : 48|1@0+ (1,0) [0|1] "" VCU

BO_ 2554658918 BatP6_BMS_CellVoltageM4: 8 BMS
 SG_ P6_CellVoltage17 : 7|13@0+ (0.001,0) [0|5] "V" VCU
 SG_ P6_CellVoltage18 : 10|13@0+ (0.001,0) [0|5] "V" VCU
 SG_ P6_CellVoltage19 : 29|13@0+ (0.001,0) [0|5] "V" VCU
 SG_ P6_CellVoltage20 : 32|13@0+ (0.001,0) [0|5] "V" VCU
 SG_ P6_BalSwCell17 : 51|1@0+ (1,0) [0|1] "" VCU
 SG_ P6_BalSwCell18 : 50|1@0+ (1,0) [0|1] "" VCU
 SG_ P6_BalSwCell19 : 49|1@0+ (1,0) [0|1] "" VCU
 SG_ P6_BalSwCell20 : 48|1@0+ (1,0) [0|1] "" VCU

BO_ 2554724454 BatP6_BMS_CellVoltageM5: 8 BMS
 SG_ P6_CellVoltage21 : 7|13@0+ (0.001,0) [0|5] "V" VCU
 SG_ P6_CellVoltage22 : 10|13@0+ (0.001,0) [0|5] "V" VCU
 SG_ P6_CellVoltage23 : 29|13@0+ (0.001,0) [0|5] "V" VCU
 SG_ P6_CellVoltage24 : 32|13@0+ (0.001,0) [0|5] "V" VCU
 SG_ P6_BalSwCell21 : 51|1@0+ (1,0) [0|1] "" VCU
 SG_ P6_BalSwCell22 : 50|1@0+ (1,0) [0|1] "" VCU
 SG_ P6_BalSwCell23 : 49|1@0+ (1,0) [0|1] "" VCU
 SG_ P6_BalSwCell24 : 48|1@0+ (1,0) [0|1] "" VCU

BO_ 2554789990 BatP6_BMS_CellVoltageM6: 8 BMS
 SG_ P6_CellVoltage25 : 7|13@0+ (0.001,0) [0|5] "V" VCU
 SG_ P6_CellVoltage26 : 10|13@0+ (0.001,0) [0|5] "V" VCU
 SG_ P6_CellVoltage27 : 29|13@0+ (0.001,0) [0|5] "V" VCU
 SG_ P6_CellVoltage28 : 32|13@0+ (0.001,0) [0|5] "V" VCU
 SG_ P6_BalSwCell25 : 51|1@0+ (1,0) [0|1] "" VCU
 SG_ P6_BalSwCell26 : 50|1@0+ (1,0) [0|1] "" VCU
 SG_ P6_BalSwCell27 : 49|1@0+ (1,0) [0|1] "" VCU
 SG_ P6_BalSwCell28 : 48|1@0+ (1,0) [0|1] "" VCU

BO_ 2554855526 BatP6_BMS_CellVoltageM7: 8 BMS
 SG_ P6_CellVoltage29 : 7|13@0+ (0.001,0) [0|5] "V" VCU
 SG_ P6_CellVoltage30 : 10|13@0+ (0.001,0) [0|5] "V" VCU
 SG_ P6_CellVoltage31 : 29|13@0+ (0.001,0) [0|5] "V" VCU
 SG_ P6_CellVoltage32 : 32|13@0+ (0.001,0) [0|5] "V" VCU
 SG_ P6_BalSwCell29 : 51|1@0+ (1,0) [0|1] "" VCU
 SG_ P6_BalSwCell30 : 50|1@0+ (1,0) [0|1] "" VCU
 SG_ P6_BalSwCell31 : 49|1@0+ (1,0) [0|1] "" VCU
 SG_ P6_BalSwCell32 : 48|1@0+ (1,0) [0|1] "" VCU

BO_ 2554921062 BatP6_BMS_CellVoltageM8: 8 BMS
 SG_ P6_CellVoltage33 : 7|13@0+ (0.001,0) [0|5] "V" VCU
 SG_ P6_CellVoltage34 : 10|13@0+ (0.001,0) [0|5] "V" VCU
 SG_ P6_CellVoltage35 : 29|13@0+ (0.001,0) [0|5] "V" VCU
 SG_ P6_CellVoltage36 : 32|13@0+ (0.001,0) [0|5] "V" VCU
 SG_ P6_BalSwCell33 : 51|1@0+ (1,0) [0|1] "" VCU
 SG_ P6_BalSwCell34 : 50|1@0+ (1,0) [0|1] "" VCU
 SG_ P6_BalSwCell35 : 49|1@0+ (1,0) [0|1] "" VCU
 SG_ P6_BalSwCell36 : 48|1@0+ (1,0) [0|1] "" VCU

BO_ 2554986598 BatP6_BMS_CellVoltageM9: 8 BMS
 SG_ P6_CellVoltage37 : 7|13@0+ (0.001,0) [0|5] "V" VCU
 SG_ P6_CellVoltage38 : 10|13@0+ (0.001,0) [0|5] "V" VCU
 SG_ P6_CellVoltage39 : 29|13@0+ (0.001,0) [0|5] "V" VCU
 SG_ P6_CellVoltage40 : 32|13@0+ (0.001,0) [0|5] "V" VCU
 SG_ P6_BalSwCell37 : 51|1@0+ (1,0) [0|1] "" VCU
 SG_ P6_BalSwCell38 : 50|1@0+ (1,0) [0|1] "" VCU
 SG_ P6_BalSwCell39 : 49|1@0+ (1,0) [0|1] "" VCU
 SG_ P6_BalSwCell40 : 48|1@0+ (1,0) [0|1] "" VCU

BO_ 2555052134 BatP6_BMS_CellVoltageM10: 8 BMS
 SG_ P6_CellVoltage41 : 7|13@0+ (0.001,0) [0|5] "V" VCU
 SG_ P6_CellVoltage42 : 10|13@0+ (0.001,0) [0|5] "V" VCU
 SG_ P6_CellVoltage43 : 29|13@0+ (0.001,0) [0|5] "V" VCU
 SG_ P6_CellVoltage44 : 32|13@0+ (0.001,0) [0|5] "V" VCU
 SG_ P6_BalSwCell41 : 51|1@0+ (1,0) [0|1] "" VCU
 SG_ P6_BalSwCell42 : 50|1@0+ (1,0) [0|1] "" VCU
 SG_ P6_BalSwCell43 : 49|1@0+ (1,0) [0|1] "" VCU
 SG_ P6_BalSwCell44 : 48|1@0+ (1,0) [0|1] "" VCU

BO_ 2555117670 BatP6_BMS_CellVoltageM11: 8 BMS
 SG_ P6_CellVoltage45 : 7|13@0+ (0.001,0) [0|5] "V" VCU
 SG_ P6_CellVoltage46 : 10|13@0+ (0.001,0) [0|5] "V" VCU
 SG_ P6_CellVoltage47 : 29|13@0+ (0.001,0) [0|5] "V" VCU
 SG_ P6_CellVoltage48 : 32|13@0+ (0.001,0) [0|5] "V" VCU
 SG_ P6_BalSwCell45 : 51|1@0+ (1,0) [0|1] "" VCU
 SG_ P6_BalSwCell46 : 50|1@0+ (1,0) [0|1] "" VCU
 SG_ P6_BalSwCell47 : 49|1@0+ (1,0) [0|1] "" VCU
 SG_ P6_BalSwCell48 : 48|1@0+ (1,0) [0|1] "" VCU

BO_ 2555183206 BatP6_BMS_CellVoltageM12: 8 BMS
 SG_ P6_CellVoltage49 : 7|13@0+ (0.001,0) [0|5] "V" VCU
 SG_ P6_CellVoltage50 : 10|13@0+ (0.001,0) [0|5] "V" VCU
 SG_ P6_CellVoltage51 : 29|13@0+ (0.001,0) [0|5] "V" VCU
 SG_ P6_CellVoltage52 : 32|13@0+ (0.001,0) [0|5] "V" VCU
 SG_ P6_BalSwCell49 : 51|1@0+ (1,0) [0|1] "" VCU
 SG_ P6_BalSwCell50 : 50|1@0+ (1,0) [0|1] "" VCU
 SG_ P6_BalSwCell51 : 49|1@0+ (1,0) [0|1] "" VCU
 SG_ P6_BalSwCell52 : 48|1@0+ (1,0) [0|1] "" VCU

BO_ 2555248742 BatP6_BMS_CellVoltageM13: 8 BMS
 SG_ P6_CellVoltage53 : 7|13@0+ (0.001,0) [0|5] "V" VCU
 SG_ P6_CellVoltage54 : 10|13@0+ (0.001,0) [0|5] "V" VCU
 SG_ P6_CellVoltage55 : 29|13@0+ (0.001,0) [0|5] "V" VCU
 SG_ P6_CellVoltage56 : 32|13@0+ (0.001,0) [0|5] "V" VCU
 SG_ P6_BalSwCell53 : 51|1@0+ (1,0) [0|1] "" VCU
 SG_ P6_BalSwCell54 : 50|1@0+ (1,0) [0|1] "" VCU
 SG_ P6_BalSwCell55 : 49|1@0+ (1,0) [0|1] "" VCU
 SG_ P6_BalSwCell56 : 48|1@0+ (1,0) [0|1] "" VCU

BO_ 2555314278 BatP6_BMS_CellVoltageM14: 8 BMS
 SG_ P6_CellVoltage57 : 7|13@0+ (0.001,0) [0|5] "V" VCU
 SG_ P6_CellVoltage58 : 10|13@0+ (0.001,0) [0|5] "V" VCU
 SG_ P6_CellVoltage59 : 29|13@0+ (0.001,0) [0|5] "V" VCU
 SG_ P6_CellVoltage60 : 32|13@0+ (0.001,0) [0|5] "V" VCU
 SG_ P6_BalSwCell57 : 51|1@0+ (1,0) [0|1] "" VCU
 SG_ P6_BalSwCell58 : 50|1@0+ (1,0) [0|1] "" VCU
 SG_ P6_BalSwCell59 : 49|1@0+ (1,0) [0|1] "" VCU
 SG_ P6_BalSwCell60 : 48|1@0+ (1,0) [0|1] "" VCU

BO_ 2555379814 BatP6_BMS_CellVoltageM15: 8 BMS
 SG_ P6_CellVoltage61 : 7|13@0+ (0.001,0) [0|5] "V" VCU
 SG_ P6_CellVoltage62 : 10|13@0+ (0.001,0) [0|5] "V" VCU
 SG_ P6_CellVoltage63 : 29|13@0+ (0.001,0) [0|5] "V" VCU
 SG_ P6_CellVoltage64 : 32|13@0+ (0.001,0) [0|5] "V" VCU
 SG_ P6_BalSwCell61 : 51|1@0+ (1,0) [0|1] "" VCU
 SG_ P6_BalSwCell62 : 50|1@0+ (1,0) [0|1] "" VCU
 SG_ P6_BalSwCell63 : 49|1@0+ (1,0) [0|1] "" VCU
 SG_ P6_BalSwCell64 : 48|1@0+ (1,0) [0|1] "" VCU

BO_ 2555445350 BatP6_BMS_CellVoltageM16: 8 BMS
 SG_ P6_CellVoltage65 : 7|13@0+ (0.001,0) [0|5] "V" VCU
 SG_ P6_CellVoltage66 : 10|13@0+ (0.001,0) [0|5] "V" VCU
 SG_ P6_CellVoltage67 : 29|13@0+ (0.001,0) [0|5] "V" VCU
 SG_ P6_CellVoltage68 : 32|13@0+ (0.001,0) [0|5] "V" VCU
 SG_ P6_BalSwCell65 : 51|1@0+ (1,0) [0|1] "" VCU
 SG_ P6_BalSwCell66 : 50|1@0+ (1,0) [0|1] "" VCU
 SG_ P6_BalSwCell67 : 49|1@0+ (1,0) [0|1] "" VCU
 SG_ P6_BalSwCell68 : 48|1@0+ (1,0) [0|1] "" VCU

BO_ 2555510886 BatP6_BMS_CellVoltageM17: 8 BMS
 SG_ P6_CellVoltage69 : 7|13@0+ (0.001,0) [0|5] "V" VCU
 SG_ P6_CellVoltage70 : 10|13@0+ (0.001,0) [0|5] "V" VCU
 SG_ P6_CellVoltage71 : 29|13@0+ (0.001,0) [0|5] "V" VCU
 SG_ P6_CellVoltage72 : 32|13@0+ (0.001,0) [0|5] "V" VCU
 SG_ P6_BalSwCell69 : 51|1@0+ (1,0) [0|1] "" VCU
 SG_ P6_BalSwCell70 : 50|1@0+ (1,0) [0|1] "" VCU
 SG_ P6_BalSwCell71 : 49|1@0+ (1,0) [0|1] "" VCU
 SG_ P6_BalSwCell72 : 48|1@0+ (1,0) [0|1] "" VCU

BO_ 2555576422 BatP6_BMS_CellVoltageM18: 8 BMS
 SG_ P6_CellVoltage73 : 7|13@0+ (0.001,0) [0|5] "V" VCU
 SG_ P6_CellVoltage74 : 10|13@0+ (0.001,0) [0|5] "V" VCU
 SG_ P6_CellVoltage75 : 29|13@0+ (0.001,0) [0|5] "V" VCU
 SG_ P6_CellVoltage76 : 32|13@0+ (0.001,0) [0|5] "V" VCU
 SG_ P6_BalSwCell73 : 51|1@0+ (1,0) [0|1] "" VCU
 SG_ P6_BalSwCell74 : 50|1@0+ (1,0) [0|1] "" VCU
 SG_ P6_BalSwCell75 : 49|1@0+ (1,0) [0|1] "" VCU
 SG_ P6_BalSwCell76 : 48|1@0+ (1,0) [0|1] "" VCU

BO_ 2555641958 BatP6_BMS_CellVoltageM19: 8 BMS
 SG_ P6_CellVoltage77 : 7|13@0+ (0.001,0) [0|5] "V" VCU
 SG_ P6_CellVoltage78 : 10|13@0+ (0.001,0) [0|5] "V" VCU
 SG_ P6_CellVoltage79 : 29|13@0+ (0.001,0) [0|5] "V" VCU
 SG_ P6_CellVoltage80 : 32|13@0+ (0.001,0) [0|5] "V" VCU
 SG_ P6_BalSwCell77 : 51|1@0+ (1,0) [0|1] "" VCU
 SG_ P6_BalSwCell78 : 50|1@0+ (1,0) [0|1] "" VCU
 SG_ P6_BalSwCell79 : 49|1@0+ (1,0) [0|1] "" VCU
 SG_ P6_BalSwCell80 : 48|1@0+ (1,0) [0|1] "" VCU

BO_ 2555707494 BatP6_BMS_CellVoltageM20: 8 BMS
 SG_ P6_CellVoltage81 : 7|13@0+ (0.001,0) [0|5] "V" VCU
 SG_ P6_CellVoltage82 : 10|13@0+ (0.001,0) [0|5] "V" VCU
 SG_ P6_CellVoltage83 : 29|13@0+ (0.001,0) [0|5] "V" VCU
 SG_ P6_CellVoltage84 : 32|13@0+ (0.001,0) [0|5] "V" VCU
 SG_ P6_BalSwCell81 : 51|1@0+ (1,0) [0|1] "" VCU
 SG_ P6_BalSwCell82 : 50|1@0+ (1,0) [0|1] "" VCU
 SG_ P6_BalSwCell83 : 49|1@0+ (1,0) [0|1] "" VCU
 SG_ P6_BalSwCell84 : 48|1@0+ (1,0) [0|1] "" VCU

BO_ 2555773030 BatP6_BMS_CellVoltageM21: 8 BMS
 SG_ P6_CellVoltage85 : 7|13@0+ (0.001,0) [0|5] "V" VCU
 SG_ P6_CellVoltage86 : 10|13@0+ (0.001,0) [0|5] "V" VCU
 SG_ P6_CellVoltage87 : 29|13@0+ (0.001,0) [0|5] "V" VCU
 SG_ P6_CellVoltage88 : 32|13@0+ (0.001,0) [0|5] "V" VCU
 SG_ P6_BalSwCell85 : 51|1@0+ (1,0) [0|1] "" VCU
 SG_ P6_BalSwCell86 : 50|1@0+ (1,0) [0|1] "" VCU
 SG_ P6_BalSwCell87 : 49|1@0+ (1,0) [0|1] "" VCU
 SG_ P6_BalSwCell88 : 48|1@0+ (1,0) [0|1] "" VCU

BO_ 2555838566 BatP6_BMS_CellVoltageM22: 8 BMS
 SG_ P6_CellVoltage89 : 7|13@0+ (0.001,0) [0|5] "V" VCU
 SG_ P6_CellVoltage90 : 10|13@0+ (0.001,0) [0|5] "V" VCU
 SG_ P6_CellVoltage91 : 29|13@0+ (0.001,0) [0|5] "V" VCU
 SG_ P6_CellVoltage92 : 32|13@0+ (0.001,0) [0|5] "V" VCU
 SG_ P6_BalSwCell89 : 51|1@0+ (1,0) [0|1] "" VCU
 SG_ P6_BalSwCell90 : 50|1@0+ (1,0) [0|1] "" VCU
 SG_ P6_BalSwCell91 : 49|1@0+ (1,0) [0|1] "" VCU
 SG_ P6_BalSwCell92 : 48|1@0+ (1,0) [0|1] "" VCU

BO_ 2555904102 BatP6_BMS_CellVoltageM23: 8 BMS
 SG_ P6_CellVoltage93 : 7|13@0+ (0.001,0) [0|5] "V" VCU
 SG_ P6_CellVoltage94 : 10|13@0+ (0.001,0) [0|5] "V" VCU
 SG_ P6_CellVoltage95 : 29|13@0+ (0.001,0) [0|5] "V" VCU
 SG_ P6_CellVoltage96 : 32|13@0+ (0.001,0) [0|5] "V" VCU
 SG_ P6_BalSwCell93 : 51|1@0+ (1,0) [0|1] "" VCU
 SG_ P6_BalSwCell94 : 50|1@0+ (1,0) [0|1] "" VCU
 SG_ P6_BalSwCell95 : 49|1@0+ (1,0) [0|1] "" VCU
 SG_ P6_BalSwCell96 : 48|1@0+ (1,0) [0|1] "" VCU

BO_ 2555969638 BatP6_BMS_CellVoltageM24: 8 BMS
 SG_ P6_CellVoltage97 : 7|13@0+ (0.001,0) [0|5] "V" VCU
 SG_ P6_CellVoltage98 : 10|13@0+ (0.001,0) [0|5] "V" VCU
 SG_ P6_CellVoltage99 : 29|13@0+ (0.001,0) [0|5] "V" VCU
 SG_ P6_CellVoltage100 : 32|13@0+ (0.001,0) [0|5] "V" VCU
 SG_ P6_BalSwCell97 : 51|1@0+ (1,0) [0|1] "" VCU
 SG_ P6_BalSwCell98 : 50|1@0+ (1,0) [0|1] "" VCU
 SG_ P6_BalSwCell99 : 49|1@0+ (1,0) [0|1] "" VCU
 SG_ P6_BalSwCell100 : 48|1@0+ (1,0) [0|1] "" VCU

BO_ 2556035174 BatP6_BMS_CellVoltageM25: 8 BMS
 SG_ P6_CellVoltage101 : 7|13@0+ (0.001,0) [0|5] "V" VCU
 SG_ P6_CellVoltage102 : 10|13@0+ (0.001,0) [0|5] "V" VCU
 SG_ P6_CellVoltage103 : 29|13@0+ (0.001,0) [0|5] "V" VCU
 SG_ P6_CellVoltage104 : 32|13@0+ (0.001,0) [0|5] "V" VCU
 SG_ P6_BalSwCell101 : 51|1@0+ (1,0) [0|1] "" VCU
 SG_ P6_BalSwCell102 : 50|1@0+ (1,0) [0|1] "" VCU
 SG_ P6_BalSwCell103 : 49|1@0+ (1,0) [0|1] "" VCU
 SG_ P6_BalSwCell104 : 48|1@0+ (1,0) [0|1] "" VCU

BO_ 2556100710 BatP6_BMS_CellVoltageM26: 8 BMS
 SG_ P6_CellVoltage105 : 7|13@0+ (0.001,0) [0|5] "V" VCU
 SG_ P6_CellVoltage106 : 10|13@0+ (0.001,0) [0|5] "V" VCU
 SG_ P6_CellVoltage107 : 29|13@0+ (0.001,0) [0|5] "V" VCU
 SG_ P6_CellVoltage108 : 32|13@0+ (0.001,0) [0|5] "V" VCU
 SG_ P6_BalSwCell105 : 51|1@0+ (1,0) [0|1] "" VCU
 SG_ P6_BalSwCell106 : 50|1@0+ (1,0) [0|1] "" VCU
 SG_ P6_BalSwCell107 : 49|1@0+ (1,0) [0|1] "" VCU
 SG_ P6_BalSwCell108 : 48|1@0+ (1,0) [0|1] "" VCU

BO_ 2556166246 BatP6_BMS_CellVoltageM27: 8 BMS
 SG_ P6_CellVoltage109 : 7|13@0+ (0.001,0) [0|5] "V" VCU
 SG_ P6_CellVoltage110 : 10|13@0+ (0.001,0) [0|5] "V" VCU
 SG_ P6_CellVoltage111 : 29|13@0+ (0.001,0) [0|5] "V" VCU
 SG_ P6_CellVoltage112 : 32|13@0+ (0.001,0) [0|5] "V" VCU
 SG_ P6_BalSwCell109 : 51|1@0+ (1,0) [0|1] "" VCU
 SG_ P6_BalSwCell110 : 50|1@0+ (1,0) [0|1] "" VCU
 SG_ P6_BalSwCell111 : 49|1@0+ (1,0) [0|1] "" VCU
 SG_ P6_BalSwCell112 : 48|1@0+ (1,0) [0|1] "" VCU

BO_ 2556231782 BatP6_BMS_CellVoltageM28: 8 BMS
 SG_ P6_CellVoltage113 : 7|13@0+ (0.001,0) [0|5] "V" VCU
 SG_ P6_CellVoltage114 : 10|13@0+ (0.001,0) [0|5] "V" VCU
 SG_ P6_CellVoltage115 : 29|13@0+ (0.001,0) [0|5] "V" VCU
 SG_ P6_CellVoltage116 : 32|13@0+ (0.001,0) [0|5] "V" VCU
 SG_ P6_BalSwCell113 : 51|1@0+ (1,0) [0|1] "" VCU
 SG_ P6_BalSwCell114 : 50|1@0+ (1,0) [0|1] "" VCU
 SG_ P6_BalSwCell115 : 49|1@0+ (1,0) [0|1] "" VCU
 SG_ P6_BalSwCell116 : 48|1@0+ (1,0) [0|1] "" VCU

BO_ 2556297318 BatP6_BMS_CellVoltageM29: 8 BMS
 SG_ P6_CellVoltage117 : 7|13@0+ (0.001,0) [0|5] "V" VCU
 SG_ P6_CellVoltage118 : 10|13@0+ (0.001,0) [0|5] "V" VCU
 SG_ P6_CellVoltage119 : 29|13@0+ (0.001,0) [0|5] "V" VCU
 SG_ P6_CellVoltage120 : 32|13@0+ (0.001,0) [0|5] "V" VCU
 SG_ P6_BalSwCell117 : 51|1@0+ (1,0) [0|1] "" VCU
 SG_ P6_BalSwCell118 : 50|1@0+ (1,0) [0|1] "" VCU
 SG_ P6_BalSwCell119 : 49|1@0+ (1,0) [0|1] "" VCU
 SG_ P6_BalSwCell120 : 48|1@0+ (1,0) [0|1] "" VCU

BO_ 2556362854 BatP6_BMS_CellVoltageM30: 8 BMS
 SG_ P6_CellVoltage121 : 7|13@0+ (0.001,0) [0|5] "V" VCU
 SG_ P6_CellVoltage122 : 10|13@0+ (0.001,0) [0|5] "V" VCU
 SG_ P6_CellVoltage123 : 29|13@0+ (0.001,0) [0|5] "V" VCU
 SG_ P6_CellVoltage124 : 32|13@0+ (0.001,0) [0|5] "V" VCU
 SG_ P6_BalSwCell121 : 51|1@0+ (1,0) [0|1] "" VCU
 SG_ P6_BalSwCell122 : 50|1@0+ (1,0) [0|1] "" VCU
 SG_ P6_BalSwCell123 : 49|1@0+ (1,0) [0|1] "" VCU
 SG_ P6_BalSwCell124 : 48|1@0+ (1,0) [0|1] "" VCU

BO_ 2556428390 BatP6_BMS_CellVoltageM31: 8 BMS
 SG_ P6_CellVoltage125 : 7|13@0+ (0.001,0) [0|5] "V" VCU
 SG_ P6_CellVoltage126 : 10|13@0+ (0.001,0) [0|5] "V" VCU
 SG_ P6_CellVoltage127 : 29|13@0+ (0.001,0) [0|5] "V" VCU
 SG_ P6_CellVoltage128 : 32|13@0+ (0.001,0) [0|5] "V" VCU
 SG_ P6_BalSwCell125 : 51|1@0+ (1,0) [0|1] "" VCU
 SG_ P6_BalSwCell126 : 50|1@0+ (1,0) [0|1] "" VCU
 SG_ P6_BalSwCell127 : 49|1@0+ (1,0) [0|1] "" VCU
 SG_ P6_BalSwCell128 : 48|1@0+ (1,0) [0|1] "" VCU

BO_ 2556493926 BatP6_BMS_CellVoltageM32: 8 BMS
 SG_ P6_CellVoltage129 : 7|13@0+ (0.001,0) [0|5] "V" VCU
 SG_ P6_CellVoltage130 : 10|13@0+ (0.001,0) [0|5] "V" VCU
 SG_ P6_CellVoltage131 : 29|13@0+ (0.001,0) [0|5] "V" VCU
 SG_ P6_CellVoltage132 : 32|13@0+ (0.001,0) [0|5] "V" VCU
 SG_ P6_BalSwCell129 : 51|1@0+ (1,0) [0|1] "" VCU
 SG_ P6_BalSwCell130 : 50|1@0+ (1,0) [0|1] "" VCU
 SG_ P6_BalSwCell131 : 49|1@0+ (1,0) [0|1] "" VCU
 SG_ P6_BalSwCell132 : 48|1@0+ (1,0) [0|1] "" VCU

BO_ 2556559462 BatP6_BMS_CellVoltageM33: 8 BMS
 SG_ P6_CellVoltage133 : 7|13@0+ (0.001,0) [0|5] "V" VCU
 SG_ P6_CellVoltage134 : 10|13@0+ (0.001,0) [0|5] "V" VCU
 SG_ P6_CellVoltage135 : 29|13@0+ (0.001,0) [0|5] "V" VCU
 SG_ P6_CellVoltage136 : 32|13@0+ (0.001,0) [0|5] "V" VCU
 SG_ P6_BalSwCell133 : 51|1@0+ (1,0) [0|1] "" VCU
 SG_ P6_BalSwCell134 : 50|1@0+ (1,0) [0|1] "" VCU
 SG_ P6_BalSwCell135 : 49|1@0+ (1,0) [0|1] "" VCU
 SG_ P6_BalSwCell136 : 48|1@0+ (1,0) [0|1] "" VCU

BO_ 2556624998 BatP6_BMS_CellVoltageM34: 8 BMS
 SG_ P6_CellVoltage137 : 7|13@0+ (0.001,0) [0|5] "V" VCU
 SG_ P6_CellVoltage138 : 10|13@0+ (0.001,0) [0|5] "V" VCU
 SG_ P6_CellVoltage139 : 29|13@0+ (0.001,0) [0|5] "V" VCU
 SG_ P6_CellVoltage140 : 32|13@0+ (0.001,0) [0|5] "V" VCU
 SG_ P6_BalSwCell137 : 51|1@0+ (1,0) [0|1] "" VCU
 SG_ P6_BalSwCell138 : 50|1@0+ (1,0) [0|1] "" VCU
 SG_ P6_BalSwCell139 : 49|1@0+ (1,0) [0|1] "" VCU
 SG_ P6_BalSwCell140 : 48|1@0+ (1,0) [0|1] "" VCU

BO_ 2556690534 BatP6_BMS_CellVoltageM35: 8 BMS
 SG_ P6_CellVoltage141 : 7|13@0+ (0.001,0) [0|5] "V" VCU
 SG_ P6_CellVoltage142 : 10|13@0+ (0.001,0) [0|5] "V" VCU
 SG_ P6_CellVoltage143 : 29|13@0+ (0.001,0) [0|5] "V" VCU
 SG_ P6_CellVoltage144 : 32|13@0+ (0.001,0) [0|5] "V" VCU
 SG_ P6_BalSwCell141 : 51|1@0+ (1,0) [0|1] "" VCU
 SG_ P6_BalSwCell142 : 50|1@0+ (1,0) [0|1] "" VCU
 SG_ P6_BalSwCell143 : 49|1@0+ (1,0) [0|1] "" VCU
 SG_ P6_BalSwCell144 : 48|1@0+ (1,0) [0|1] "" VCU

BO_ 2556756070 BatP6_BMS_CellVoltageM36: 8 BMS
 SG_ P6_CellVoltage145 : 7|13@0+ (0.001,0) [0|5] "V" VCU
 SG_ P6_CellVoltage146 : 10|13@0+ (0.001,0) [0|5] "V" VCU
 SG_ P6_CellVoltage147 : 29|13@0+ (0.001,0) [0|5] "V" VCU
 SG_ P6_CellVoltage148 : 32|13@0+ (0.001,0) [0|5] "V" VCU
 SG_ P6_BalSwCell145 : 51|1@0+ (1,0) [0|1] "" VCU
 SG_ P6_BalSwCell146 : 50|1@0+ (1,0) [0|1] "" VCU
 SG_ P6_BalSwCell147 : 49|1@0+ (1,0) [0|1] "" VCU
 SG_ P6_BalSwCell148 : 48|1@0+ (1,0) [0|1] "" VCU

BO_ 2556821606 BatP6_BMS_CellVoltageM37: 8 BMS
 SG_ P6_CellVoltage149 : 7|13@0+ (0.001,0) [0|5] "V" VCU
 SG_ P6_CellVoltage150 : 10|13@0+ (0.001,0) [0|5] "V" VCU
 SG_ P6_CellVoltage151 : 29|13@0+ (0.001,0) [0|5] "V" VCU
 SG_ P6_CellVoltage152 : 32|13@0+ (0.001,0) [0|5] "V" VCU
 SG_ P6_BalSwCell149 : 51|1@0+ (1,0) [0|1] "" VCU
 SG_ P6_BalSwCell150 : 50|1@0+ (1,0) [0|1] "" VCU
 SG_ P6_BalSwCell151 : 49|1@0+ (1,0) [0|1] "" VCU
 SG_ P6_BalSwCell152 : 48|1@0+ (1,0) [0|1] "" VCU

BO_ 2556887142 BatP6_BMS_CellVoltageM38: 8 BMS
 SG_ P6_CellVoltage153 : 7|13@0+ (0.001,0) [0|5] "V" VCU
 SG_ P6_CellVoltage154 : 10|13@0+ (0.001,0) [0|5] "V" VCU
 SG_ P6_CellVoltage155 : 29|13@0+ (0.001,0) [0|5] "V" VCU
 SG_ P6_CellVoltage156 : 32|13@0+ (0.001,0) [0|5] "V" VCU
 SG_ P6_BalSwCell153 : 51|1@0+ (1,0) [0|1] "" VCU
 SG_ P6_BalSwCell154 : 50|1@0+ (1,0) [0|1] "" VCU
 SG_ P6_BalSwCell155 : 49|1@0+ (1,0) [0|1] "" VCU
 SG_ P6_BalSwCell156 : 48|1@0+ (1,0) [0|1] "" VCU

BO_ 2556952678 BatP6_BMS_CellVoltageM39: 8 BMS
 SG_ P6_CellVoltage157 : 7|13@0+ (0.001,0) [0|5] "V" VCU
 SG_ P6_CellVoltage158 : 10|13@0+ (0.001,0) [0|5] "V" VCU
 SG_ P6_CellVoltage159 : 29|13@0+ (0.001,0) [0|5] "V" VCU
 SG_ P6_CellVoltage160 : 32|13@0+ (0.001,0) [0|5] "V" VCU
 SG_ P6_BalSwCell157 : 51|1@0+ (1,0) [0|1] "" VCU
 SG_ P6_BalSwCell158 : 50|1@0+ (1,0) [0|1] "" VCU
 SG_ P6_BalSwCell159 : 49|1@0+ (1,0) [0|1] "" VCU
 SG_ P6_BalSwCell160 : 48|1@0+ (1,0) [0|1] "" VCU

BO_ 2557018214 BatP6_BMS_CellVoltageM40: 8 BMS
 SG_ P6_CellVoltage161 : 7|13@0+ (0.001,0) [0|5] "V" VCU
 SG_ P6_CellVoltage162 : 10|13@0+ (0.001,0) [0|5] "V" VCU
 SG_ P6_CellVoltage163 : 29|13@0+ (0.001,0) [0|5] "V" VCU
 SG_ P6_CellVoltage164 : 32|13@0+ (0.001,0) [0|5] "V" VCU
 SG_ P6_BalSwCell161 : 51|1@0+ (1,0) [0|1] "" VCU
 SG_ P6_BalSwCell162 : 50|1@0+ (1,0) [0|1] "" VCU
 SG_ P6_BalSwCell163 : 49|1@0+ (1,0) [0|1] "" VCU
 SG_ P6_BalSwCell164 : 48|1@0+ (1,0) [0|1] "" VCU

BO_ 2557083750 BatP6_BMS_CellVoltageM41: 8 BMS
 SG_ P6_CellVoltage165 : 7|13@0+ (0.001,0) [0|5] "V" VCU
 SG_ P6_CellVoltage166 : 10|13@0+ (0.001,0) [0|5] "V" VCU
 SG_ P6_CellVoltage167 : 29|13@0+ (0.001,0) [0|5] "V" VCU
 SG_ P6_CellVoltage168 : 32|13@0+ (0.001,0) [0|5] "V" VCU
 SG_ P6_BalSwCell165 : 51|1@0+ (1,0) [0|1] "" VCU
 SG_ P6_BalSwCell166 : 50|1@0+ (1,0) [0|1] "" VCU
 SG_ P6_BalSwCell167 : 49|1@0+ (1,0) [0|1] "" VCU
 SG_ P6_BalSwCell168 : 48|1@0+ (1,0) [0|1] "" VCU

BO_ 2557149286 BatP6_BMS_CellVoltageM42: 8 BMS
 SG_ P6_CellVoltage169 : 7|13@0+ (0.001,0) [0|5] "V" VCU
 SG_ P6_CellVoltage170 : 10|13@0+ (0.001,0) [0|5] "V" VCU
 SG_ P6_CellVoltage171 : 29|13@0+ (0.001,0) [0|5] "V" VCU
 SG_ P6_CellVoltage172 : 32|13@0+ (0.001,0) [0|5] "V" VCU
 SG_ P6_BalSwCell169 : 51|1@0+ (1,0) [0|1] "" VCU
 SG_ P6_BalSwCell170 : 50|1@0+ (1,0) [0|1] "" VCU
 SG_ P6_BalSwCell171 : 49|1@0+ (1,0) [0|1] "" VCU
 SG_ P6_BalSwCell172 : 48|1@0+ (1,0) [0|1] "" VCU

BO_ 2557214822 BatP6_BMS_CellVoltageM43: 8 BMS
 SG_ P6_CellVoltage173 : 7|13@0+ (0.001,0) [0|5] "V" VCU
 SG_ P6_CellVoltage174 : 10|13@0+ (0.001,0) [0|5] "V" VCU
 SG_ P6_CellVoltage175 : 29|13@0+ (0.001,0) [0|5] "V" VCU
 SG_ P6_CellVoltage176 : 32|13@0+ (0.001,0) [0|5] "V" VCU
 SG_ P6_BalSwCell173 : 51|1@0+ (1,0) [0|1] "" VCU
 SG_ P6_BalSwCell174 : 50|1@0+ (1,0) [0|1] "" VCU
 SG_ P6_BalSwCell175 : 49|1@0+ (1,0) [0|1] "" VCU
 SG_ P6_BalSwCell176 : 48|1@0+ (1,0) [0|1] "" VCU

BO_ 2557280358 BatP6_BMS_CellVoltageM44: 8 BMS
 SG_ P6_CellVoltage177 : 7|13@0+ (0.001,0) [0|5] "V" VCU
 SG_ P6_CellVoltage178 : 10|13@0+ (0.001,0) [0|5] "V" VCU
 SG_ P6_CellVoltage179 : 29|13@0+ (0.001,0) [0|5] "V" VCU
 SG_ P6_CellVoltage180 : 32|13@0+ (0.001,0) [0|5] "V" VCU
 SG_ P6_BalSwCell177 : 51|1@0+ (1,0) [0|1] "" VCU
 SG_ P6_BalSwCell178 : 50|1@0+ (1,0) [0|1] "" VCU
 SG_ P6_BalSwCell179 : 49|1@0+ (1,0) [0|1] "" VCU
 SG_ P6_BalSwCell180 : 48|1@0+ (1,0) [0|1] "" VCU

BO_ 2557345894 BatP6_BMS_CellVoltageM45: 8 BMS
 SG_ P6_CellVoltage181 : 7|13@0+ (0.001,0) [0|5] "V" VCU
 SG_ P6_CellVoltage182 : 10|13@0+ (0.001,0) [0|5] "V" VCU
 SG_ P6_CellVoltage183 : 29|13@0+ (0.001,0) [0|5] "V" VCU
 SG_ P6_CellVoltage184 : 32|13@0+ (0.001,0) [0|5] "V" VCU
 SG_ P6_BalSwCell181 : 51|1@0+ (1,0) [0|1] "" VCU
 SG_ P6_BalSwCell182 : 50|1@0+ (1,0) [0|1] "" VCU
 SG_ P6_BalSwCell183 : 49|1@0+ (1,0) [0|1] "" VCU
 SG_ P6_BalSwCell184 : 48|1@0+ (1,0) [0|1] "" VCU

BO_ 2557411430 BatP6_BMS_CellVoltageM46: 8 BMS
 SG_ P6_CellVoltage185 : 7|13@0+ (0.001,0) [0|5] "V" VCU
 SG_ P6_CellVoltage186 : 10|13@0+ (0.001,0) [0|5] "V" VCU
 SG_ P6_CellVoltage187 : 29|13@0+ (0.001,0) [0|5] "V" VCU
 SG_ P6_CellVoltage188 : 32|13@0+ (0.001,0) [0|5] "V" VCU
 SG_ P6_BalSwCell185 : 51|1@0+ (1,0) [0|1] "" VCU
 SG_ P6_BalSwCell186 : 50|1@0+ (1,0) [0|1] "" VCU
 SG_ P6_BalSwCell187 : 49|1@0+ (1,0) [0|1] "" VCU
 SG_ P6_BalSwCell188 : 48|1@0+ (1,0) [0|1] "" VCU

BO_ 2557476966 BatP6_BMS_CellVoltageM47: 8 BMS
 SG_ P6_CellVoltage189 : 7|13@0+ (0.001,0) [0|5] "V" VCU
 SG_ P6_CellVoltage190 : 10|13@0+ (0.001,0) [0|5] "V" VCU
 SG_ P6_CellVoltage191 : 29|13@0+ (0.001,0) [0|5] "V" VCU
 SG_ P6_CellVoltage192 : 32|13@0+ (0.001,0) [0|5] "V" VCU
 SG_ P6_BalSwCell189 : 51|1@0+ (1,0) [0|1] "" VCU
 SG_ P6_BalSwCell190 : 50|1@0+ (1,0) [0|1] "" VCU
 SG_ P6_BalSwCell191 : 49|1@0+ (1,0) [0|1] "" VCU
 SG_ P6_BalSwCell192 : 48|1@0+ (1,0) [0|1] "" VCU

BO_ 2558525542 BatP6_BMS_CellTempM0: 8 BMS
 SG_ P6_CellTemp1 : 7|11@0+ (0.1,-40) [-40|150] "C" VCU
 SG_ P6_CellTemp2 : 12|11@0+ (0.1,-40) [-40|150] "C" VCU
 SG_ P6_CellTemp3 : 17|11@0+ (0.1,-40) [-40|150] "C" VCU
 SG_ P6_CellTemp4 : 38|11@0+ (0.1,-40) [-40|150] "C" VCU
 SG_ P6_CellTemp5 : 43|11@0+ (0.1,-40) [-40|150] "C" VCU

BO_ 2558591078 BatP6_BMS_CellTempM1: 8 BMS
 SG_ P6_CellTemp6 : 7|11@0+ (0.1,-40) [-40|150] "C" VCU
 SG_ P6_CellTemp7 : 12|11@0+ (0.1,-40) [-40|150] "C" VCU
 SG_ P6_CellTemp8 : 17|11@0+ (0.1,-40) [-40|150] "C" VCU
 SG_ P6_CellTemp9 : 38|11@0+ (0.1,-40) [-40|150] "C" VCU
 SG_ P6_CellTemp10 : 43|11@0+ (0.1,-40) [-40|150] "C" VCU

BO_ 2558656614 BatP6_BMS_CellTempM2: 8 BMS
 SG_ P6_CellTemp11 : 7|11@0+ (0.1,-40) [-40|150] "C" VCU
 SG_ P6_CellTemp12 : 12|11@0+ (0.1,-40) [-40|150] "C" VCU
 SG_ P6_CellTemp13 : 17|11@0+ (0.1,-40) [-40|150] "C" VCU
 SG_ P6_CellTemp14 : 38|11@0+ (0.1,-40) [-40|150] "C" VCU
 SG_ P6_CellTemp15 : 43|11@0+ (0.1,-40) [-40|150] "C" VCU

BO_ 2558722150 BatP6_BMS_CellTempM3: 8 BMS
 SG_ P6_CellTemp16 : 7|11@0+ (0.1,-40) [-40|150] "C" VCU
 SG_ P6_CellTemp17 : 12|11@0+ (0.1,-40) [-40|150] "C" VCU
 SG_ P6_CellTemp18 : 17|11@0+ (0.1,-40) [-40|150] "C" VCU
 SG_ P6_CellTemp19 : 38|11@0+ (0.1,-40) [-40|150] "C" VCU
 SG_ P6_CellTemp20 : 43|11@0+ (0.1,-40) [-40|150] "C" VCU

BO_ 2558787686 BatP6_BMS_CellTempM4: 8 BMS
 SG_ P6_CellTemp21 : 7|11@0+ (0.1,-40) [-40|150] "C" VCU
 SG_ P6_CellTemp22 : 12|11@0+ (0.1,-40) [-40|150] "C" VCU
 SG_ P6_CellTemp23 : 17|11@0+ (0.1,-40) [-40|150] "C" VCU
 SG_ P6_CellTemp24 : 38|11@0+ (0.1,-40) [-40|150] "C" VCU
 SG_ P6_CellTemp25 : 43|11@0+ (0.1,-40) [-40|150] "C" VCU

BO_ 2558853222 BatP6_BMS_CellTempM5: 8 BMS
 SG_ P6_CellTemp26 : 7|11@0+ (0.1,-40) [-40|150] "C" VCU
 SG_ P6_CellTemp27 : 12|11@0+ (0.1,-40) [-40|150] "C" VCU
 SG_ P6_CellTemp28 : 17|11@0+ (0.1,-40) [-40|150] "C" VCU
 SG_ P6_CellTemp29 : 38|11@0+ (0.1,-40) [-40|150] "C" VCU
 SG_ P6_CellTemp30 : 43|11@0+ (0.1,-40) [-40|150] "C" VCU

BO_ 2558918758 BatP6_BMS_CellTempM6: 8 BMS
 SG_ P6_CellTemp31 : 7|11@0+ (0.1,-40) [-40|150] "C" VCU
 SG_ P6_CellTemp32 : 12|11@0+ (0.1,-40) [-40|150] "C" VCU
 SG_ P6_CellTemp33 : 17|11@0+ (0.1,-40) [-40|150] "C" VCU
 SG_ P6_CellTemp34 : 38|11@0+ (0.1,-40) [-40|150] "C" VCU
 SG_ P6_CellTemp35 : 43|11@0+ (0.1,-40) [-40|150] "C" VCU

BO_ 2558984294 BatP6_BMS_CellTempM7: 8 BMS
 SG_ P6_CellTemp36 : 7|11@0+ (0.1,-40) [-40|150] "C" VCU
 SG_ P6_CellTemp37 : 12|11@0+ (0.1,-40) [-40|150] "C" VCU
 SG_ P6_CellTemp38 : 17|11@0+ (0.1,-40) [-40|150] "C" VCU
 SG_ P6_CellTemp39 : 38|11@0+ (0.1,-40) [-40|150] "C" VCU
 SG_ P6_CellTemp40 : 43|11@0+ (0.1,-40) [-40|150] "C" VCU

BO_ 2559049830 BatP6_BMS_CellTempM8: 8 BMS
 SG_ P6_CellTemp41 : 7|11@0+ (0.1,-40) [-40|150] "C" VCU
 SG_ P6_CellTemp42 : 12|11@0+ (0.1,-40) [-40|150] "C" VCU
 SG_ P6_CellTemp43 : 17|11@0+ (0.1,-40) [-40|150] "C" VCU
 SG_ P6_CellTemp44 : 38|11@0+ (0.1,-40) [-40|150] "C" VCU
 SG_ P6_CellTemp45 : 43|11@0+ (0.1,-40) [-40|150] "C" VCU

BO_ 2559115366 BatP6_BMS_CellTempM9: 8 BMS
 SG_ P6_CellTemp46 : 7|11@0+ (0.1,-40) [-40|150] "C" VCU
 SG_ P6_CellTemp47 : 12|11@0+ (0.1,-40) [-40|150] "C" VCU
 SG_ P6_CellTemp48 : 17|11@0+ (0.1,-40) [-40|150] "C" VCU
 SG_ P6_CellTemp49 : 38|11@0+ (0.1,-40) [-40|150] "C" VCU
 SG_ P6_CellTemp50 : 43|11@0+ (0.1,-40) [-40|150] "C" VCU

BO_ 2559180902 BatP6_BMS_CellTempM10: 8 BMS
 SG_ P6_CellTemp51 : 7|11@0+ (0.1,-40) [-40|150] "C" VCU
 SG_ P6_CellTemp52 : 12|11@0+ (0.1,-40) [-40|150] "C" VCU
 SG_ P6_CellTemp53 : 17|11@0+ (0.1,-40) [-40|150] "C" VCU
 SG_ P6_CellTemp54 : 38|11@0+ (0.1,-40) [-40|150] "C" VCU
 SG_ P6_CellTemp55 : 43|11@0+ (0.1,-40) [-40|150] "C" VCU

BO_ 2559246438 BatP6_BMS_CellTempM11: 8 BMS
 SG_ P6_CellTemp56 : 7|11@0+ (0.1,-40) [-40|150] "C" VCU
 SG_ P6_CellTemp57 : 12|11@0+ (0.1,-40) [-40|150] "C" VCU
 SG_ P6_CellTemp58 : 17|11@0+ (0.1,-40) [-40|150] "C" VCU
 SG_ P6_CellTemp59 : 38|11@0+ (0.1,-40) [-40|150] "C" VCU
 SG_ P6_CellTemp60 : 43|11@0+ (0.1,-40) [-40|150] "C" VCU

BO_ 2559311974 BatP6_BMS_CellTempM12: 8 BMS
 SG_ P6_CellTemp61 : 7|11@0+ (0.1,-40) [-40|150] "C" VCU
 SG_ P6_CellTemp62 : 12|11@0+ (0.1,-40) [-40|150] "C" VCU
 SG_ P6_CellTemp63 : 17|11@0+ (0.1,-40) [-40|150] "C" VCU
 SG_ P6_CellTemp64 : 38|11@0+ (0.1,-40) [-40|150] "C" VCU
 SG_ P6_CellTemp65 : 43|11@0+ (0.1,-40) [-40|150] "C" VCU

BO_ 2559377510 BatP6_BMS_CellTempM13: 8 BMS
 SG_ P6_CellTemp66 : 7|11@0+ (0.1,-40) [-40|150] "C" VCU
 SG_ P6_CellTemp67 : 12|11@0+ (0.1,-40) [-40|150] "C" VCU
 SG_ P6_CellTemp68 : 17|11@0+ (0.1,-40) [-40|150] "C" VCU
 SG_ P6_CellTemp69 : 38|11@0+ (0.1,-40) [-40|150] "C" VCU
 SG_ P6_CellTemp70 : 43|11@0+ (0.1,-40) [-40|150] "C" VCU

BO_ 2559443046 BatP6_BMS_CellTempM14: 8 BMS
 SG_ P6_CellTemp71 : 7|11@0+ (0.1,-40) [-40|150] "C" VCU
 SG_ P6_CellTemp72 : 12|11@0+ (0.1,-40) [-40|150] "C" VCU
 SG_ P6_CellTemp73 : 17|11@0+ (0.1,-40) [-40|150] "C" VCU
 SG_ P6_CellTemp74 : 38|11@0+ (0.1,-40) [-40|150] "C" VCU
 SG_ P6_CellTemp75 : 43|11@0+ (0.1,-40) [-40|150] "C" VCU

BO_ 2559508582 BatP6_BMS_CellTempM15: 8 BMS
 SG_ P6_CellTemp76 : 7|11@0+ (0.1,-40) [-40|150] "C" VCU
 SG_ P6_CellTemp77 : 12|11@0+ (0.1,-40) [-40|150] "C" VCU
 SG_ P6_CellTemp78 : 17|11@0+ (0.1,-40) [-40|150] "C" VCU
 SG_ P6_CellTemp79 : 38|11@0+ (0.1,-40) [-40|150] "C" VCU
 SG_ P6_CellTemp80 : 43|11@0+ (0.1,-40) [-40|150] "C" VCU

BO_ 2559574118 BatP6_BMS_CellTempM16: 8 BMS
 SG_ P6_CellTemp81 : 7|11@0+ (0.1,-40) [-40|150] "C" VCU
 SG_ P6_CellTemp82 : 12|11@0+ (0.1,-40) [-40|150] "C" VCU
 SG_ P6_CellTemp83 : 17|11@0+ (0.1,-40) [-40|150] "C" VCU
 SG_ P6_CellTemp84 : 38|11@0+ (0.1,-40) [-40|150] "C" VCU
 SG_ P6_CellTemp85 : 43|11@0+ (0.1,-40) [-40|150] "C" VCU

BO_ 2559639654 BatP6_BMS_CellTempM17: 8 BMS
 SG_ P6_CellTemp86 : 7|11@0+ (0.1,-40) [-40|150] "C" VCU
 SG_ P6_CellTemp87 : 12|11@0+ (0.1,-40) [-40|150] "C" VCU
 SG_ P6_CellTemp88 : 17|11@0+ (0.1,-40) [-40|150] "C" VCU
 SG_ P6_CellTemp89 : 38|11@0+ (0.1,-40) [-40|150] "C" VCU
 SG_ P6_CellTemp90 : 43|11@0+ (0.1,-40) [-40|150] "C" VCU

BO_ 2559705190 BatP6_BMS_CellTempM18: 8 BMS
 SG_ P6_CellTemp91 : 7|11@0+ (0.1,-40) [-40|150] "C" VCU
 SG_ P6_CellTemp92 : 12|11@0+ (0.1,-40) [-40|150] "C" VCU
 SG_ P6_CellTemp93 : 17|11@0+ (0.1,-40) [-40|150] "C" VCU
 SG_ P6_CellTemp94 : 38|11@0+ (0.1,-40) [-40|150] "C" VCU
 SG_ P6_CellTemp95 : 43|11@0+ (0.1,-40) [-40|150] "C" VCU

BO_ 2559770726 BatP6_BMS_CellTempM19: 8 BMS
 SG_ P6_CellTemp96 : 7|11@0+ (0.1,-40) [-40|150] "C" VCU
 SG_ P6_CellTemp97 : 12|11@0+ (0.1,-40) [-40|150] "C" VCU
 SG_ P6_CellTemp98 : 17|11@0+ (0.1,-40) [-40|150] "C" VCU
 SG_ P6_CellTemp99 : 38|11@0+ (0.1,-40) [-40|150] "C" VCU
 SG_ P6_CellTemp100 : 43|11@0+ (0.1,-40) [-40|150] "C" VCU

BO_ 2559836262 BatP6_BMS_CellTempM20: 8 BMS
 SG_ P6_CellTemp101 : 7|11@0+ (0.1,-40) [-40|150] "C" VCU
 SG_ P6_CellTemp102 : 12|11@0+ (0.1,-40) [-40|150] "C" VCU
 SG_ P6_CellTemp103 : 17|11@0+ (0.1,-40) [-40|150] "C" VCU
 SG_ P6_CellTemp104 : 38|11@0+ (0.1,-40) [-40|150] "C" VCU
 SG_ P6_CellTemp105 : 43|11@0+ (0.1,-40) [-40|150] "C" VCU

BO_ 2559901798 BatP6_BMS_CellTempM21: 8 BMS
 SG_ P6_CellTemp106 : 7|11@0+ (0.1,-40) [-40|150] "C" VCU
 SG_ P6_CellTemp107 : 12|11@0+ (0.1,-40) [-40|150] "C" VCU
 SG_ P6_CellTemp108 : 17|11@0+ (0.1,-40) [-40|150] "C" VCU
 SG_ P6_CellTemp109 : 38|11@0+ (0.1,-40) [-40|150] "C" VCU
 SG_ P6_CellTemp110 : 43|11@0+ (0.1,-40) [-40|150] "C" VCU

BO_ 2559967334 BatP6_BMS_CellTempM22: 8 BMS
 SG_ P6_CellTemp111 : 7|11@0+ (0.1,-40) [-40|150] "C" VCU
 SG_ P6_CellTemp112 : 12|11@0+ (0.1,-40) [-40|150] "C" VCU
 SG_ P6_CellTemp113 : 17|11@0+ (0.1,-40) [-40|150] "C" VCU
 SG_ P6_CellTemp114 : 38|11@0+ (0.1,-40) [-40|150] "C" VCU
 SG_ P6_CellTemp115 : 43|11@0+ (0.1,-40) [-40|150] "C" VCU

BO_ 2560032870 BatP6_BMS_CellTempM23: 8 BMS
 SG_ P6_CellTemp116 : 7|11@0+ (0.1,-40) [-40|150] "C" VCU
 SG_ P6_CellTemp117 : 12|11@0+ (0.1,-40) [-40|150] "C" VCU
 SG_ P6_CellTemp118 : 17|11@0+ (0.1,-40) [-40|150] "C" VCU
 SG_ P6_CellTemp119 : 38|11@0+ (0.1,-40) [-40|150] "C" VCU
 SG_ P6_CellTemp120 : 43|11@0+ (0.1,-40) [-40|150] "C" VCU

BO_ 2560098406 BatP6_BMS_CellTempM24: 8 BMS
 SG_ P6_CellTemp121 : 7|11@0+ (0.1,-40) [-40|150] "C" VCU
 SG_ P6_CellTemp122 : 12|11@0+ (0.1,-40) [-40|150] "C" VCU
 SG_ P6_CellTemp123 : 17|11@0+ (0.1,-40) [-40|150] "C" VCU
 SG_ P6_CellTemp124 : 38|11@0+ (0.1,-40) [-40|150] "C" VCU
 SG_ P6_CellTemp125 : 43|11@0+ (0.1,-40) [-40|150] "C" VCU

BO_ 2560163942 BatP6_BMS_CellTempM25: 8 BMS
 SG_ P6_CellTemp126 : 7|11@0+ (0.1,-40) [-40|150] "C" VCU
 SG_ P6_CellTemp127 : 12|11@0+ (0.1,-40) [-40|150] "C" VCU
 SG_ P6_CellTemp128 : 17|11@0+ (0.1,-40) [-40|150] "C" VCU
 SG_ P6_CellTemp129 : 38|11@0+ (0.1,-40) [-40|150] "C" VCU
 SG_ P6_CellTemp130 : 43|11@0+ (0.1,-40) [-40|150] "C" VCU

BO_ 2560229478 BatP6_BMS_CellTempM26: 8 BMS
 SG_ P6_CellTemp131 : 7|11@0+ (0.1,-40) [-40|150] "C" VCU
 SG_ P6_CellTemp132 : 12|11@0+ (0.1,-40) [-40|150] "C" VCU
 SG_ P6_CellTemp133 : 17|11@0+ (0.1,-40) [-40|150] "C" VCU
 SG_ P6_CellTemp134 : 38|11@0+ (0.1,-40) [-40|150] "C" VCU
 SG_ P6_CellTemp135 : 43|11@0+ (0.1,-40) [-40|150] "C" VCU

BO_ 2560295014 BatP6_BMS_CellTempM27: 8 BMS
 SG_ P6_CellTemp136 : 7|11@0+ (0.1,-40) [-40|150] "C" VCU
 SG_ P6_CellTemp137 : 12|11@0+ (0.1,-40) [-40|150] "C" VCU
 SG_ P6_CellTemp138 : 17|11@0+ (0.1,-40) [-40|150] "C" VCU
 SG_ P6_CellTemp139 : 38|11@0+ (0.1,-40) [-40|150] "C" VCU
 SG_ P6_CellTemp140 : 43|11@0+ (0.1,-40) [-40|150] "C" VCU

BO_ 2560360550 BatP6_BMS_CellTempM28: 8 BMS
 SG_ P6_CellTemp141 : 7|11@0+ (0.1,-40) [-40|150] "C" VCU
 SG_ P6_CellTemp142 : 12|11@0+ (0.1,-40) [-40|150] "C" VCU
 SG_ P6_CellTemp143 : 17|11@0+ (0.1,-40) [-40|150] "C" VCU
 SG_ P6_CellTemp144 : 38|11@0+ (0.1,-40) [-40|150] "C" VCU
 SG_ P6_CellTemp145 : 43|11@0+ (0.1,-40) [-40|150] "C" VCU

BO_ 2560426086 BatP6_BMS_CellTempM29: 8 BMS
 SG_ P6_CellTemp146 : 7|11@0+ (0.1,-40) [-40|150] "C" VCU
 SG_ P6_CellTemp147 : 12|11@0+ (0.1,-40) [-40|150] "C" VCU
 SG_ P6_CellTemp148 : 17|11@0+ (0.1,-40) [-40|150] "C" VCU
 SG_ P6_CellTemp149 : 38|11@0+ (0.1,-40) [-40|150] "C" VCU
 SG_ P6_CellTemp150 : 43|11@0+ (0.1,-40) [-40|150] "C" VCU

BO_ 2560491622 BatP6_BMS_CellTempM30: 8 BMS
 SG_ P6_CellTemp151 : 7|11@0+ (0.1,-40) [-40|150] "C" VCU
 SG_ P6_CellTemp152 : 12|11@0+ (0.1,-40) [-40|150] "C" VCU
 SG_ P6_CellTemp153 : 17|11@0+ (0.1,-40) [-40|150] "C" VCU
 SG_ P6_CellTemp154 : 38|11@0+ (0.1,-40) [-40|150] "C" VCU
 SG_ P6_CellTemp155 : 43|11@0+ (0.1,-40) [-40|150] "C" VCU

BO_ 2560557158 BatP6_BMS_CellTempM31: 8 BMS
 SG_ P6_CellTemp156 : 7|11@0+ (0.1,-40) [-40|150] "C" VCU
 SG_ P6_CellTemp157 : 12|11@0+ (0.1,-40) [-40|150] "C" VCU
 SG_ P6_CellTemp158 : 17|11@0+ (0.1,-40) [-40|150] "C" VCU
 SG_ P6_CellTemp159 : 38|11@0+ (0.1,-40) [-40|150] "C" VCU
 SG_ P6_CellTemp160 : 43|11@0+ (0.1,-40) [-40|150] "C" VCU

BO_ 2560622694 BatP6_BMS_CellTempM32: 8 BMS
 SG_ P6_CellTemp161 : 7|11@0+ (0.1,-40) [-40|150] "C" VCU
 SG_ P6_CellTemp162 : 12|11@0+ (0.1,-40) [-40|150] "C" VCU
 SG_ P6_CellTemp163 : 17|11@0+ (0.1,-40) [-40|150] "C" VCU
 SG_ P6_CellTemp164 : 38|11@0+ (0.1,-40) [-40|150] "C" VCU
 SG_ P6_CellTemp165 : 43|11@0+ (0.1,-40) [-40|150] "C" VCU

BO_ 2560688230 BatP6_BMS_CellTempM33: 8 BMS
 SG_ P6_CellTemp166 : 7|11@0+ (0.1,-40) [-40|150] "C" VCU
 SG_ P6_CellTemp167 : 12|11@0+ (0.1,-40) [-40|150] "C" VCU
 SG_ P6_CellTemp168 : 17|11@0+ (0.1,-40) [-40|150] "C" VCU
 SG_ P6_CellTemp169 : 38|11@0+ (0.1,-40) [-40|150] "C" VCU
 SG_ P6_CellTemp170 : 43|11@0+ (0.1,-40) [-40|150] "C" VCU

BO_ 2560753766 BatP6_BMS_CellTempM34: 8 BMS
 SG_ P6_CellTemp171 : 7|11@0+ (0.1,-40) [-40|150] "C" VCU
 SG_ P6_CellTemp172 : 12|11@0+ (0.1,-40) [-40|150] "C" VCU
 SG_ P6_CellTemp173 : 17|11@0+ (0.1,-40) [-40|150] "C" VCU
 SG_ P6_CellTemp174 : 38|11@0+ (0.1,-40) [-40|150] "C" VCU
 SG_ P6_CellTemp175 : 43|11@0+ (0.1,-40) [-40|150] "C" VCU

BO_ 2560819302 BatP6_BMS_CellTempM35: 8 BMS
 SG_ P6_CellTemp176 : 7|11@0+ (0.1,-40) [-40|150] "C" VCU
 SG_ P6_CellTemp177 : 12|11@0+ (0.1,-40) [-40|150] "C" VCU
 SG_ P6_CellTemp178 : 17|11@0+ (0.1,-40) [-40|150] "C" VCU
 SG_ P6_CellTemp179 : 38|11@0+ (0.1,-40) [-40|150] "C" VCU
 SG_ P6_CellTemp180 : 43|11@0+ (0.1,-40) [-40|150] "C" VCU

BO_ 2560884838 BatP6_BMS_CellTempM36: 8 BMS
 SG_ P6_CellTemp181 : 7|11@0+ (0.1,-40) [-40|150] "C" VCU
 SG_ P6_CellTemp182 : 12|11@0+ (0.1,-40) [-40|150] "C" VCU
 SG_ P6_CellTemp183 : 17|11@0+ (0.1,-40) [-40|150] "C" VCU
 SG_ P6_CellTemp184 : 38|11@0+ (0.1,-40) [-40|150] "C" VCU
 SG_ P6_CellTemp185 : 43|11@0+ (0.1,-40) [-40|150] "C" VCU

BO_ 2560950374 BatP6_BMS_CellTempM37: 8 BMS
 SG_ P6_CellTemp186 : 7|11@0+ (0.1,-40) [-40|150] "C" VCU
 SG_ P6_CellTemp187 : 12|11@0+ (0.1,-40) [-40|150] "C" VCU
 SG_ P6_CellTemp188 : 17|11@0+ (0.1,-40) [-40|150] "C" VCU
 SG_ P6_CellTemp189 : 38|11@0+ (0.1,-40) [-40|150] "C" VCU
 SG_ P6_CellTemp190 : 43|11@0+ (0.1,-40) [-40|150] "C" VCU

BO_ 2561015910 BatP6_BMS_CellTempM38: 8 BMS
 SG_ P6_CellTemp191 : 7|11@0+ (0.1,-40) [-40|150] "C" VCU
 SG_ P6_CellTemp192 : 12|11@0+ (0.1,-40) [-40|150] "C" VCU
 SG_ P6_DatLen16DbgInfo1 : 7|16@0+ (1,0) [0|65535] "" VCU
 SG_ P6_DatLen16DbgInfo2 : 23|16@0+ (1,0) [0|65535] "" VCU
 SG_ P6_DatLen16DbgInfo3 : 39|16@0+ (1,0) [0|65535] "" VCU
 SG_ P6_DatLen16DbgInfo4 : 55|16@0+ (1,0) [0|65535] "" VCU

BO_ 2550399095 BatP7_BMS_PowerSupplyInfo: 8 BMS
 SG_ P7_BMSPwrSuplVlt1 : 7|9@0+ (0.1,0) [0|50] "V" VCU
 SG_ P7_BMSPwrSuplVlt2 : 14|9@0+ (0.1,0) [0|50] "V" VCU
 SG_ P7_ChrgStationAuxPwrSuplVlt : 21|9@0+ (0.1,0) [0|50] "V" VCU
 SG_ P7_BMSKL15ON : 28|1@0+ (1,0) [0|1] "" VCU
 SG_ P7_DCStepState : 27|8@0+ (1,0) [0|255] "" VCU
 SG_ P7_ExtLvWakeup_28VOnly : 35|9@0+ (0.1,0) [0|50] "V" VCU

BO_ 2550464631 BatP7_BMS_PackUsageLimit: 8 BMS
 SG_ P7_PackVltUprLmt : 7|14@0+ (0.1,0) [0|1200] "V" VCU
 SG_ P7_PackVltLoLmt : 9|14@0+ (0.1,0) [0|1200] "V" VCU
 SG_ P7_PackMaxDschrgCrnt : 27|14@0+ (0.1,0) [0|1600] "A" VCU
 SG_ P7_PackMaxChrgCrnt : 45|14@0+ (0.1,0) [0|1600] "A" VCU

BO_ 2550530167 BatP7_BMS_PackPowerCapability: 8 BMS
 SG_ P7_PackDschrgPwrLmt : 7|10@0+ (1,0) [0|1000] "kW" VCU
 SG_ P7_PackDschrgPwrStat : 13|2@0+ (1,0) [0|3] "" VCU
 SG_ P7_PackChrgPwrLmt : 11|10@0+ (1,0) [0|1000] "kW" VCU
 SG_ P7_PackChrgPwrStat : 17|2@0+ (1,0) [0|3] "" VCU

CM_ SG_ 2550530133 P5_PackDschrgPwrLmt "电池包5的放电功率限值";
CM_ SG_ 2550530133 P5_PackDschrgPwrStat "电池包5的放电功率状态";
CM_ SG_ 2550530133 P5_PackChrgPwrLmt "电池包5的充电功率限值";
CM_ SG_ 2550530133 P5_PackChrgPwrStat "电池包5的充电功率状态";
CM_ SG_ 2550595669 P5_ChrgrCplrStat "电池包5的充电枪连接状态";
CM_ SG_ 2550595669 P5_HVBattChrgSysStatus "电池包5的充电系统状态";
CM_ SG_ 2550595669 P5_DCChrgCrntCmd "电池包5的直流充电请求电流";
CM_ SG_ 2550595669 P5_CC2Vlt "电池包5的CC2电压值";
CM_ SG_ 2550595669 P5_DCRcptPosTemp "电池包5的快充充电插座正极温度";
CM_ SG_ 2550595669 P5_DCRcptNegTemp "电池包5的快充充电插座负极温度";
CM_ SG_ 2550595669 P5_Tm2FullChrg "电池包5满充剩余时间";
CM_ SG_ 2550661205 P5_Inlet1ClntTemp "进水口1冷却液温度";
CM_ SG_ 2550661205 P5_Inlet2ClntTemp "进水口2冷却液温度";
CM_ SG_ 2550661205 P5_Outlet1ClntTemp "出水口1冷却液温度";
CM_ SG_ 2550661205 P5_Outlet2ClntTemp "出水口2冷却液温度";
CM_ SG_ 2550661205 P5_TrgtClntTemp "冷却水目标温度";
CM_ SG_ 2550661205 P5_TrgtClntFlowRate "冷却水目标流量";
CM_ SG_ 2550726741 P5_MaxCellVlt "电池包5的最大单体电压";
CM_ SG_ 2550726741 P5_MaxCellVltNum "电池包5的最大单体电压编号";
CM_ SG_ 2550726741 P5_MinCellVlt "电池包5的最小单体电压";
CM_ SG_ 2550726741 P5_MinCellVltNum "电池包5的最小单体电压编号";
CM_ SG_ 2550726741 P5_AvgCellVlt "电池包5的平均单体电压";
CM_ SG_ 2550792277 P5_MaxCellTemp "电池包5的最高单体温度";
CM_ SG_ 2550792277 P5_MaxCellTempNum "电池包5的最高单体温度编号";
CM_ SG_ 2550792277 P5_MinCellTemp "电池包5的最低单体温度";
CM_ SG_ 2550792277 P5_MinCellTempNum "电池包5的最低单体温度编号";
CM_ SG_ 2550792277 P5_AvgCellTemp "电池包5的单体平均温度";
CM_ SG_ 2550857813 P5_PackTotFltNum "电池包5的电池故障总数";
CM_ SG_ 2550857813 P5_CellOverVoltage "电池包5的单体过压";
CM_ SG_ 2550857813 P5_CellUnderVoltage "电池包5的单体欠压";
CM_ SG_ 2550857813 P5_CellVoltageDiffHi "电池包5的单体压差过大";
CM_ SG_ 2550857813 P5_PackOverVoltage "电池包5的电压过高";
CM_ SG_ 2550857813 P5_PackUnderVoltage "电池包5的电压过低";
CM_ SG_ 2550857813 P5_CellOverTemp "电池包5的单体过温";
CM_ SG_ 2550857813 P5_CellTempLow "电池包5的单体温度过低";
CM_ SG_ 2550857813 P5_CellTempDiffHi "电池包5的单体温度差异过大";
CM_ SG_ 2550857813 P5_PackDschrgCrntHi "电池包5的放电电流过流";
CM_ SG_ 2550857813 P5_PackChrgCrntHi "电池包5的充电电流过流";
CM_ SG_ 2550857813 P5_PackCrnSnsr1OffsetHi "电池包5的电流传感器1零漂过大";
CM_ SG_ 2550857813 P5_HVIsolFlt "电池包5的高压绝缘故障";
CM_ SG_ 2550857813 P5_HVILFlt "电池包5的高压互锁故障";
CM_ SG_ 2550857813 P5_ThrmlRunaway "电池包5的热失控故障";
CM_ SG_ 2550857813 P5_CellVoltInvalid "电池包5的单体电压采样失效";
CM_ SG_ 2550857813 P5_CellTempInvalid "电池包5的电芯温度采样失效";
CM_ SG_ 2550857813 P5_DaisyChainComFlt "电池包5的菊花链通信故障";
CM_ SG_ 2550857813 P5_PackVoltRatFlt "电池包5的总电压与单体电压总和偏差过大";
CM_ SG_ 2550857813 P5_CrntSnsr1Invalid "电池包5的电流传感器1电流采样失效";
CM_ SG_ 2550857813 P5_CrntSnsr1OOR "电池包5的电流传感器1电流超出采样范围";
CM_ SG_ 2550857813 P5_CrntSnsr2Invalid "电池包5的电流传感器2电流采样失效";
CM_ SG_ 2550857813 P5_CrntSnsr2OOR "电池包5的电流传感器2电流超出采样范围";
CM_ SG_ 2550857813 P5_PackCrnSnsr2OffsetHi "电池包5的电流传感器2零漂过大";
CM_ SG_ 2550857813 P5_OutofEnergy "电池包5的电池剩余电量低";
CM_ SG_ 2550857813 P5_IsolDetCircErr "电池包5的绝缘检测电路失效";
CM_ SG_ 2550857813 P5_HVILCircShortToGND "电池包5的高压互锁对地短路";
CM_ SG_ 2550857813 P5_HVILCircShortToPwr "电池包5的高压互锁对电源短路";
CM_ SG_ 2550923349 P5_MainPosCntctrStkClsd "电池包5的主正继电器粘连故障";
CM_ SG_ 2550923349 P5_MainPosCntctrStkOpn "电池包5的主正继电器常开故障";
CM_ SG_ 2550923349 P5_MainNegCntctr1StkClsd "电池包5的主负继电器1粘连故障";
CM_ SG_ 2550923349 P5_MainNegCntctr1StkOpn "电池包5的主负继电器1常开故障";
CM_ SG_ 2550923349 P5_MainNegCntctr2StkClsd "电池包5的主负继电器2粘连故障";
CM_ SG_ 2550923349 P5_MainNegCntctr2StkOpn "电池包5的主负继电器2常开故障";
CM_ SG_ 2550923349 P5_PrechargTmOut "电池包5的预充超时故障";
CM_ SG_ 2550923349 P5_PrechrgCrntHi "电池包5的预充过流故障";
CM_ SG_ 2550923349 P5_ChrgCplrPosTempHi "电池包5的充电正极接口温度过高故障";
CM_ SG_ 2550923349 P5_ChrgCplrNegTempHi "电池包5的充电负极接口温度过高故障";
CM_ SG_ 2550923349 P5_BMSPwrSuplVlt1Hi "电池包5的BMS供电电压1过高";
CM_ SG_ 2550923349 P5_BMSPwrSuplVlt1Lo "电池包5的BMS供电电压1过低";
CM_ SG_ 2550923349 P5_BMSPwrSuplVlt2Hi "电池包5的BMS供电电压2过高";
CM_ SG_ 2550923349 P5_BMSPwrSuplVlt2Lo "电池包5的BMS供电电压2过低";
CM_ SG_ 2550923349 P5_CntctrCirPwrSuplVltLo "电池包5的继电器驱动供电电压过低";
CM_ SG_ 2550923349 P5_CntctrCirPwrSuplVltHi "电池包5的继电器驱动供电电压过高";
CM_ SG_ 2550923349 P5_CAN1BusOff "电池包5的CAN1通信Bus off";
CM_ SG_ 2550923349 P5_CAN1BusTmOut "电池包5的CAN1报文超时（Timeout）";
CM_ SG_ 2550923349 P5_CAN2BusOff "电池包5的CAN2通信Bus off";
CM_ SG_ 2550923349 P5_CAN2BusTmOut "电池包5的CAN2报文超时（Timeout）";
CM_ SG_ 2550923349 P5_CellBalCircTempHi "电池包5的均衡电路过温";
CM_ SG_ 2550923349 P5_ClntInTempHi "电池包5的入水口温度过高";
CM_ SG_ 2550923349 P5_ClntOutTempHi "电池包5的出水口温度过高";
CM_ SG_ 2550923349 P5_CellExtrmUdrVolt "电池包5的单体极限欠压";
CM_ SG_ 2550923349 P5_CellExtrmOvrVolt "电池包5的单体极限过压";
CM_ SG_ 2550923349 P5_Branch1DischrgCrntHi  "电池包5的支路1放电过流";
CM_ SG_ 2550923349 P5_Branch2DischrgCrntHi  "电池包5的支路2放电过流";
CM_ SG_ 2550923349 P5_Branch1ChrgCrntHi  "电池包5的支路1充电过流";
CM_ SG_ 2550923349 P5_Branch2ChrgCrntHi  "电池包5的支路2充电过流";
CM_ SG_ 2550923349 P5_InitFailed "电池包5的BMS初始化失败";
CM_ SG_ 2550923349 P5_PackErrCode "电池包5的故障代码";
CM_ SG_ 2550988885 P5_PackTotCellNum "电池包5的单体电池总数";
CM_ SG_ 2550988885 P5_PackTotCellTempSnsrNum "电池包5的单体温度传感器总数";
CM_ SG_ 2552299605 P5_BMSASWMajVerNum "电池包5的BMS应用层软件主版本号";
CM_ SG_ 2552299605 P5_BMSASWMinVerNum "电池包5的BMS应用层软件子版本号";
CM_ SG_ 2552299605 P5_BMSASWPatchVerNum "电池包5的BMS应用层软件修订版本号";
CM_ SG_ 2552299605 P5_BMSBSWMajVerNum "电池包5的BMS底层软件主版本号";
CM_ SG_ 2552299605 P5_BMSBSWMinVerNum "电池包5的BMS底层软件子版本号";
CM_ SG_ 2552299605 P5_BMSBSWPatchVerNum "电池包5的BMS底层软件修订版本号";
CM_ SG_ 2554396757 P5_CellVoltage1 "电池包5的单体电压1";
CM_ SG_ 2554396757 P5_CellVoltage2 "电池包5的单体电压2";
CM_ SG_ 2554396757 P5_CellVoltage3 "电池包5的单体电压3";
CM_ SG_ 2554396757 P5_CellVoltage4 "电池包5的单体电压4";
CM_ SG_ 2554396757 P5_BalSwCell1 "电池包5的电芯1均衡状态";
CM_ SG_ 2554396757 P5_BalSwCell2 "电池包5的电芯2均衡状态";
CM_ SG_ 2554396757 P5_BalSwCell3 "电池包5的电芯3均衡状态";
CM_ SG_ 2554396757 P5_BalSwCell4 "电池包5的电芯4均衡状态";
CM_ SG_ 2554462293 P5_CellVoltage5 "电池包5的单体电压5";
CM_ SG_ 2554462293 P5_CellVoltage6 "电池包5的单体电压6";
CM_ SG_ 2554462293 P5_CellVoltage7 "电池包5的单体电压7";
CM_ SG_ 2554462293 P5_CellVoltage8 "电池包5的单体电压8";
CM_ SG_ 2554462293 P5_BalSwCell5 "电池包5的电芯5均衡状态";
CM_ SG_ 2554462293 P5_BalSwCell6 "电池包5的电芯6均衡状态";
CM_ SG_ 2554462293 P5_BalSwCell7 "电池包5的电芯7均衡状态";
CM_ SG_ 2554462293 P5_BalSwCell8 "电池包5的电芯8均衡状态";
CM_ SG_ 2554527829 P5_CellVoltage9 "电池包5的单体电压9";
CM_ SG_ 2554527829 P5_CellVoltage10 "电池包5的单体电压10";
CM_ SG_ 2554527829 P5_CellVoltage11 "电池包5的单体电压11";
CM_ SG_ 2554527829 P5_CellVoltage12 "电池包5的单体电压12";
CM_ SG_ 2554527829 P5_BalSwCell9 "电池包5的电芯9均衡状态";
CM_ SG_ 2554527829 P5_BalSwCell10 "电池包5的电芯10均衡状态";
CM_ SG_ 2554527829 P5_BalSwCell11 "电池包5的电芯11均衡状态";
CM_ SG_ 2554527829 P5_BalSwCell12 "电池包5的电芯12均衡状态";
CM_ SG_ 2554593365 P5_CellVoltage13 "电池包5的单体电压13";
CM_ SG_ 2554593365 P5_CellVoltage14 "电池包5的单体电压14";
CM_ SG_ 2554593365 P5_CellVoltage15 "电池包5的单体电压15";
CM_ SG_ 2554593365 P5_CellVoltage16 "电池包5的单体电压16";
CM_ SG_ 2554593365 P5_BalSwCell13 "电池包5的电芯13均衡状态";
CM_ SG_ 2554593365 P5_BalSwCell14 "电池包5的电芯14均衡状态";
CM_ SG_ 2554593365 P5_BalSwCell15 "电池包5的电芯15均衡状态";
CM_ SG_ 2554593365 P5_BalSwCell16 "电池包5的电芯16均衡状态";
CM_ SG_ 2554658901 P5_CellVoltage17 "电池包5的单体电压17";
CM_ SG_ 2554658901 P5_CellVoltage18 "电池包5的单体电压18";
CM_ SG_ 2554658901 P5_CellVoltage19 "电池包5的单体电压19";
CM_ SG_ 2554658901 P5_CellVoltage20 "电池包5的单体电压20";
CM_ SG_ 2554658901 P5_BalSwCell17 "电池包5的电芯17均衡状态";
CM_ SG_ 2554658901 P5_BalSwCell18 "电池包5的电芯18均衡状态";
CM_ SG_ 2554658901 P5_BalSwCell19 "电池包5的电芯19均衡状态";
CM_ SG_ 2554658901 P5_BalSwCell20 "电池包5的电芯20均衡状态";
CM_ SG_ 2554724437 P5_CellVoltage21 "电池包5的单体电压21";
CM_ SG_ 2554724437 P5_CellVoltage22 "电池包5的单体电压22";
CM_ SG_ 2554724437 P5_CellVoltage23 "电池包5的单体电压23";
CM_ SG_ 2554724437 P5_CellVoltage24 "电池包5的单体电压24";
CM_ SG_ 2554724437 P5_BalSwCell21 "电池包5的电芯21均衡状态";
CM_ SG_ 2554724437 P5_BalSwCell22 "电池包5的电芯22均衡状态";
CM_ SG_ 2554724437 P5_BalSwCell23 "电池包5的电芯23均衡状态";
CM_ SG_ 2554724437 P5_BalSwCell24 "电池包5的电芯24均衡状态";
CM_ SG_ 2554789973 P5_CellVoltage25 "电池包5的单体电压25";
CM_ SG_ 2554789973 P5_CellVoltage26 "电池包5的单体电压26";
CM_ SG_ 2554789973 P5_CellVoltage27 "电池包5的单体电压27";
CM_ SG_ 2554789973 P5_CellVoltage28 "电池包5的单体电压28";
CM_ SG_ 2554789973 P5_BalSwCell25 "电池包5的电芯25均衡状态";
CM_ SG_ 2554789973 P5_BalSwCell26 "电池包5的电芯26均衡状态";
CM_ SG_ 2554789973 P5_BalSwCell27 "电池包5的电芯27均衡状态";
CM_ SG_ 2554789973 P5_BalSwCell28 "电池包5的电芯28均衡状态";
CM_ SG_ 2554855509 P5_CellVoltage29 "电池包5的单体电压29";
CM_ SG_ 2554855509 P5_CellVoltage30 "电池包5的单体电压30";
CM_ SG_ 2554855509 P5_CellVoltage31 "电池包5的单体电压31";
CM_ SG_ 2554855509 P5_CellVoltage32 "电池包5的单体电压32";
CM_ SG_ 2554855509 P5_BalSwCell29 "电池包5的电芯29均衡状态";
CM_ SG_ 2554855509 P5_BalSwCell30 "电池包5的电芯30均衡状态";
CM_ SG_ 2554855509 P5_BalSwCell31 "电池包5的电芯31均衡状态";
CM_ SG_ 2554855509 P5_BalSwCell32 "电池包5的电芯32均衡状态";
CM_ SG_ 2554921045 P5_CellVoltage33 "电池包5的单体电压33";
CM_ SG_ 2554921045 P5_CellVoltage34 "电池包5的单体电压34";
CM_ SG_ 2554921045 P5_CellVoltage35 "电池包5的单体电压35";
CM_ SG_ 2554921045 P5_CellVoltage36 "电池包5的单体电压36";
CM_ SG_ 2554921045 P5_BalSwCell33 "电池包5的电芯33均衡状态";
CM_ SG_ 2554921045 P5_BalSwCell34 "电池包5的电芯34均衡状态";
CM_ SG_ 2554921045 P5_BalSwCell35 "电池包5的电芯35均衡状态";
CM_ SG_ 2554921045 P5_BalSwCell36 "电池包5的电芯36均衡状态";
CM_ SG_ 2554986581 P5_CellVoltage37 "电池包5的单体电压37";
CM_ SG_ 2554986581 P5_CellVoltage38 "电池包5的单体电压38";
CM_ SG_ 2554986581 P5_CellVoltage39 "电池包5的单体电压39";
CM_ SG_ 2554986581 P5_CellVoltage40 "电池包5的单体电压40";
CM_ SG_ 2554986581 P5_BalSwCell37 "电池包5的电芯37均衡状态";
CM_ SG_ 2554986581 P5_BalSwCell38 "电池包5的电芯38均衡状态";
CM_ SG_ 2554986581 P5_BalSwCell39 "电池包5的电芯39均衡状态";
CM_ SG_ 2554986581 P5_BalSwCell40 "电池包5的电芯40均衡状态";
CM_ SG_ 2555052117 P5_CellVoltage41 "电池包5的单体电压41";
CM_ SG_ 2555052117 P5_CellVoltage42 "电池包5的单体电压42";
CM_ SG_ 2555052117 P5_CellVoltage43 "电池包5的单体电压43";
CM_ SG_ 2555052117 P5_CellVoltage44 "电池包5的单体电压44";
CM_ SG_ 2555052117 P5_BalSwCell41 "电池包5的电芯41均衡状态";
CM_ SG_ 2555052117 P5_BalSwCell42 "电池包5的电芯42均衡状态";
CM_ SG_ 2555052117 P5_BalSwCell43 "电池包5的电芯43均衡状态";
CM_ SG_ 2555052117 P5_BalSwCell44 "电池包5的电芯44均衡状态";
CM_ SG_ 2555117653 P5_CellVoltage45 "电池包5的单体电压45";
CM_ SG_ 2555117653 P5_CellVoltage46 "电池包5的单体电压46";
CM_ SG_ 2555117653 P5_CellVoltage47 "电池包5的单体电压47";
CM_ SG_ 2555117653 P5_CellVoltage48 "电池包5的单体电压48";
CM_ SG_ 2555117653 P5_BalSwCell45 "电池包5的电芯45均衡状态";
CM_ SG_ 2555117653 P5_BalSwCell46 "电池包5的电芯46均衡状态";
CM_ SG_ 2555117653 P5_BalSwCell47 "电池包5的电芯47均衡状态";
CM_ SG_ 2555117653 P5_BalSwCell48 "电池包5的电芯48均衡状态";
CM_ SG_ 2555183189 P5_CellVoltage49 "电池包5的单体电压49";
CM_ SG_ 2555183189 P5_CellVoltage50 "电池包5的单体电压50";
CM_ SG_ 2555183189 P5_CellVoltage51 "电池包5的单体电压51";
CM_ SG_ 2555183189 P5_CellVoltage52 "电池包5的单体电压52";
CM_ SG_ 2555183189 P5_BalSwCell49 "电池包5的电芯49均衡状态";
CM_ SG_ 2555183189 P5_BalSwCell50 "电池包5的电芯50均衡状态";
CM_ SG_ 2555183189 P5_BalSwCell51 "电池包5的电芯51均衡状态";
CM_ SG_ 2555183189 P5_BalSwCell52 "电池包5的电芯52均衡状态";
CM_ SG_ 2555248725 P5_CellVoltage53 "电池包5的单体电压53";
CM_ SG_ 2555248725 P5_CellVoltage54 "电池包5的单体电压54";
CM_ SG_ 2555248725 P5_CellVoltage55 "电池包5的单体电压55";
CM_ SG_ 2555248725 P5_CellVoltage56 "电池包5的单体电压56";
CM_ SG_ 2555248725 P5_BalSwCell53 "电池包5的电芯53均衡状态";
CM_ SG_ 2555248725 P5_BalSwCell54 "电池包5的电芯54均衡状态";
CM_ SG_ 2555248725 P5_BalSwCell55 "电池包5的电芯55均衡状态";
CM_ SG_ 2555248725 P5_BalSwCell56 "电池包5的电芯56均衡状态";
CM_ SG_ 2555314261 P5_CellVoltage57 "电池包5的单体电压57";
CM_ SG_ 2555314261 P5_CellVoltage58 "电池包5的单体电压58";
CM_ SG_ 2555314261 P5_CellVoltage59 "电池包5的单体电压59";
CM_ SG_ 2555314261 P5_CellVoltage60 "电池包5的单体电压60";
CM_ SG_ 2555314261 P5_BalSwCell57 "电池包5的电芯57均衡状态";
CM_ SG_ 2555314261 P5_BalSwCell58 "电池包5的电芯58均衡状态";
CM_ SG_ 2555314261 P5_BalSwCell59 "电池包5的电芯59均衡状态";
CM_ SG_ 2555314261 P5_BalSwCell60 "电池包5的电芯60均衡状态";
CM_ SG_ 2555379797 P5_CellVoltage61 "电池包5的单体电压61";
CM_ SG_ 2555379797 P5_CellVoltage62 "电池包5的单体电压62";
CM_ SG_ 2555379797 P5_CellVoltage63 "电池包5的单体电压63";
CM_ SG_ 2555379797 P5_CellVoltage64 "电池包5的单体电压64";
CM_ SG_ 2555379797 P5_BalSwCell61 "电池包5的电芯61均衡状态";
CM_ SG_ 2555379797 P5_BalSwCell62 "电池包5的电芯62均衡状态";
CM_ SG_ 2555379797 P5_BalSwCell63 "电池包5的电芯63均衡状态";
CM_ SG_ 2555379797 P5_BalSwCell64 "电池包5的电芯64均衡状态";
CM_ SG_ 2555445333 P5_CellVoltage65 "电池包5的单体电压65";
CM_ SG_ 2555445333 P5_CellVoltage66 "电池包5的单体电压66";
CM_ SG_ 2555445333 P5_CellVoltage67 "电池包5的单体电压67";
CM_ SG_ 2555445333 P5_CellVoltage68 "电池包5的单体电压68";
CM_ SG_ 2555445333 P5_BalSwCell65 "电池包5的电芯65均衡状态";
CM_ SG_ 2555445333 P5_BalSwCell66 "电池包5的电芯66均衡状态";
CM_ SG_ 2555445333 P5_BalSwCell67 "电池包5的电芯67均衡状态";
CM_ SG_ 2555445333 P5_BalSwCell68 "电池包5的电芯68均衡状态";
CM_ SG_ 2555510869 P5_CellVoltage69 "电池包5的单体电压69";
CM_ SG_ 2555510869 P5_CellVoltage70 "电池包5的单体电压70";
CM_ SG_ 2555510869 P5_CellVoltage71 "电池包5的单体电压71";
CM_ SG_ 2555510869 P5_CellVoltage72 "电池包5的单体电压72";
CM_ SG_ 2555510869 P5_BalSwCell69 "电池包5的电芯69均衡状态";
CM_ SG_ 2555510869 P5_BalSwCell70 "电池包5的电芯70均衡状态";
CM_ SG_ 2555510869 P5_BalSwCell71 "电池包5的电芯71均衡状态";
CM_ SG_ 2555510869 P5_BalSwCell72 "电池包5的电芯72均衡状态";
CM_ SG_ 2555576405 P5_CellVoltage73 "电池包5的单体电压73";
CM_ SG_ 2555576405 P5_CellVoltage74 "电池包5的单体电压74";
CM_ SG_ 2555576405 P5_CellVoltage75 "电池包5的单体电压75";
CM_ SG_ 2555576405 P5_CellVoltage76 "电池包5的单体电压76";
CM_ SG_ 2555576405 P5_BalSwCell73 "电池包5的电芯73均衡状态";
CM_ SG_ 2555576405 P5_BalSwCell74 "电池包5的电芯74均衡状态";
CM_ SG_ 2555576405 P5_BalSwCell75 "电池包5的电芯75均衡状态";
CM_ SG_ 2555576405 P5_BalSwCell76 "电池包5的电芯76均衡状态";
CM_ SG_ 2555641941 P5_CellVoltage77 "电池包5的单体电压77";
CM_ SG_ 2555641941 P5_CellVoltage78 "电池包5的单体电压78";
CM_ SG_ 2555641941 P5_CellVoltage79 "电池包5的单体电压79";
CM_ SG_ 2555641941 P5_CellVoltage80 "电池包5的单体电压80";
CM_ SG_ 2555641941 P5_BalSwCell77 "电池包5的电芯77均衡状态";
CM_ SG_ 2555641941 P5_BalSwCell78 "电池包5的电芯78均衡状态";
CM_ SG_ 2555641941 P5_BalSwCell79 "电池包5的电芯79均衡状态";
CM_ SG_ 2555641941 P5_BalSwCell80 "电池包5的电芯80均衡状态";
CM_ SG_ 2555707477 P5_CellVoltage81 "电池包5的单体电压81";
CM_ SG_ 2555707477 P5_CellVoltage82 "电池包5的单体电压82";
CM_ SG_ 2555707477 P5_CellVoltage83 "电池包5的单体电压83";
CM_ SG_ 2555707477 P5_CellVoltage84 "电池包5的单体电压84";
CM_ SG_ 2555707477 P5_BalSwCell81 "电池包5的电芯81均衡状态";
CM_ SG_ 2555707477 P5_BalSwCell82 "电池包5的电芯82均衡状态";
CM_ SG_ 2555707477 P5_BalSwCell83 "电池包5的电芯83均衡状态";
CM_ SG_ 2555707477 P5_BalSwCell84 "电池包5的电芯84均衡状态";
CM_ SG_ 2555773013 P5_CellVoltage85 "电池包5的单体电压85";
CM_ SG_ 2555773013 P5_CellVoltage86 "电池包5的单体电压86";
CM_ SG_ 2555773013 P5_CellVoltage87 "电池包5的单体电压87";
CM_ SG_ 2555773013 P5_CellVoltage88 "电池包5的单体电压88";
CM_ SG_ 2555773013 P5_BalSwCell85 "电池包5的电芯85均衡状态";
CM_ SG_ 2555773013 P5_BalSwCell86 "电池包5的电芯86均衡状态";
CM_ SG_ 2555773013 P5_BalSwCell87 "电池包5的电芯87均衡状态";
CM_ SG_ 2555773013 P5_BalSwCell88 "电池包5的电芯88均衡状态";
CM_ SG_ 2555838549 P5_CellVoltage89 "电池包5的单体电压89";
CM_ SG_ 2555838549 P5_CellVoltage90 "电池包5的单体电压90";
CM_ SG_ 2555838549 P5_CellVoltage91 "电池包5的单体电压91";
CM_ SG_ 2555838549 P5_CellVoltage92 "电池包5的单体电压92";
CM_ SG_ 2555838549 P5_BalSwCell89 "电池包5的电芯89均衡状态";
CM_ SG_ 2555838549 P5_BalSwCell90 "电池包5的电芯90均衡状态";
CM_ SG_ 2555838549 P5_BalSwCell91 "电池包5的电芯91均衡状态";
CM_ SG_ 2555838549 P5_BalSwCell92 "电池包5的电芯92均衡状态";
CM_ SG_ 2555904085 P5_CellVoltage93 "电池包5的单体电压93";
CM_ SG_ 2555904085 P5_CellVoltage94 "电池包5的单体电压94";
CM_ SG_ 2555904085 P5_CellVoltage95 "电池包5的单体电压95";
CM_ SG_ 2555904085 P5_CellVoltage96 "电池包5的单体电压96";
CM_ SG_ 2555904085 P5_BalSwCell93 "电池包5的电芯93均衡状态";
CM_ SG_ 2555904085 P5_BalSwCell94 "电池包5的电芯94均衡状态";
CM_ SG_ 2555904085 P5_BalSwCell95 "电池包5的电芯95均衡状态";
CM_ SG_ 2555904085 P5_BalSwCell96 "电池包5的电芯96均衡状态";
CM_ SG_ 2555969621 P5_CellVoltage97 "电池包5的单体电压97";
CM_ SG_ 2555969621 P5_CellVoltage98 "电池包5的单体电压98";
CM_ SG_ 2555969621 P5_CellVoltage99 "电池包5的单体电压99";
CM_ SG_ 2555969621 P5_CellVoltage100 "电池包5的单体电压100";
CM_ SG_ 2555969621 P5_BalSwCell97 "电池包5的电芯97均衡状态";
CM_ SG_ 2555969621 P5_BalSwCell98 "电池包5的电芯98均衡状态";
CM_ SG_ 2555969621 P5_BalSwCell99 "电池包5的电芯99均衡状态";
CM_ SG_ 2555969621 P5_BalSwCell100 "电池包5的电芯100均衡状态";
CM_ SG_ 2556035157 P5_CellVoltage101 "电池包5的单体电压101";
CM_ SG_ 2556035157 P5_CellVoltage102 "电池包5的单体电压102";
CM_ SG_ 2556035157 P5_CellVoltage103 "电池包5的单体电压103";
CM_ SG_ 2556035157 P5_CellVoltage104 "电池包5的单体电压104";
CM_ SG_ 2556035157 P5_BalSwCell101 "电池包5的电芯101均衡状态";
CM_ SG_ 2556035157 P5_BalSwCell102 "电池包5的电芯102均衡状态";
CM_ SG_ 2556035157 P5_BalSwCell103 "电池包5的电芯103均衡状态";
CM_ SG_ 2556035157 P5_BalSwCell104 "电池包5的电芯104均衡状态";
CM_ SG_ 2556100693 P5_CellVoltage105 "电池包5的单体电压105";
CM_ SG_ 2556100693 P5_CellVoltage106 "电池包5的单体电压106";
CM_ SG_ 2556100693 P5_CellVoltage107 "电池包5的单体电压107";
CM_ SG_ 2556100693 P5_CellVoltage108 "电池包5的单体电压108";
CM_ SG_ 2556100693 P5_BalSwCell105 "电池包5的电芯105均衡状态";
CM_ SG_ 2556100693 P5_BalSwCell106 "电池包5的电芯106均衡状态";
CM_ SG_ 2556100693 P5_BalSwCell107 "电池包5的电芯107均衡状态";
CM_ SG_ 2556100693 P5_BalSwCell108 "电池包5的电芯108均衡状态";
CM_ SG_ 2556166229 P5_CellVoltage109 "电池包5的单体电压109";
CM_ SG_ 2556166229 P5_CellVoltage110 "电池包5的单体电压110";
CM_ SG_ 2556166229 P5_CellVoltage111 "电池包5的单体电压111";
CM_ SG_ 2556166229 P5_CellVoltage112 "电池包5的单体电压112";
CM_ SG_ 2556166229 P5_BalSwCell109 "电池包5的电芯109均衡状态";
CM_ SG_ 2556166229 P5_BalSwCell110 "电池包5的电芯110均衡状态";
CM_ SG_ 2556166229 P5_BalSwCell111 "电池包5的电芯111均衡状态";
CM_ SG_ 2556166229 P5_BalSwCell112 "电池包5的电芯112均衡状态";
CM_ SG_ 2556231765 P5_CellVoltage113 "电池包5的单体电压113";
CM_ SG_ 2556231765 P5_CellVoltage114 "电池包5的单体电压114";
CM_ SG_ 2556231765 P5_CellVoltage115 "电池包5的单体电压115";
CM_ SG_ 2556231765 P5_CellVoltage116 "电池包5的单体电压116";
CM_ SG_ 2556231765 P5_BalSwCell113 "电池包5的电芯113均衡状态";
CM_ SG_ 2556231765 P5_BalSwCell114 "电池包5的电芯114均衡状态";
CM_ SG_ 2556231765 P5_BalSwCell115 "电池包5的电芯115均衡状态";
CM_ SG_ 2556231765 P5_BalSwCell116 "电池包5的电芯116均衡状态";
CM_ SG_ 2556297301 P5_CellVoltage117 "电池包5的单体电压117";
CM_ SG_ 2556297301 P5_CellVoltage118 "电池包5的单体电压118";
CM_ SG_ 2556297301 P5_CellVoltage119 "电池包5的单体电压119";
CM_ SG_ 2556297301 P5_CellVoltage120 "电池包5的单体电压120";
CM_ SG_ 2556297301 P5_BalSwCell117 "电池包5的电芯117均衡状态";
CM_ SG_ 2556297301 P5_BalSwCell118 "电池包5的电芯118均衡状态";
CM_ SG_ 2556297301 P5_BalSwCell119 "电池包5的电芯119均衡状态";
CM_ SG_ 2556297301 P5_BalSwCell120 "电池包5的电芯120均衡状态";
CM_ SG_ 2556362837 P5_CellVoltage121 "电池包5的单体电压121";
CM_ SG_ 2556362837 P5_CellVoltage122 "电池包5的单体电压122";
CM_ SG_ 2556362837 P5_CellVoltage123 "电池包5的单体电压123";
CM_ SG_ 2556362837 P5_CellVoltage124 "电池包5的单体电压124";
CM_ SG_ 2556362837 P5_BalSwCell121 "电池包5的电芯121均衡状态";
CM_ SG_ 2556362837 P5_BalSwCell122 "电池包5的电芯122均衡状态";
CM_ SG_ 2556362837 P5_BalSwCell123 "电池包5的电芯123均衡状态";
CM_ SG_ 2556362837 P5_BalSwCell124 "电池包5的电芯124均衡状态";
CM_ SG_ 2556428373 P5_CellVoltage125 "电池包5的单体电压125";
CM_ SG_ 2556428373 P5_CellVoltage126 "电池包5的单体电压126";
CM_ SG_ 2556428373 P5_CellVoltage127 "电池包5的单体电压127";
CM_ SG_ 2556428373 P5_CellVoltage128 "电池包5的单体电压128";
CM_ SG_ 2556428373 P5_BalSwCell125 "电池包5的电芯125均衡状态";
CM_ SG_ 2556428373 P5_BalSwCell126 "电池包5的电芯126均衡状态";
CM_ SG_ 2556428373 P5_BalSwCell127 "电池包5的电芯127均衡状态";
CM_ SG_ 2556428373 P5_BalSwCell128 "电池包5的电芯128均衡状态";
CM_ SG_ 2556493909 P5_CellVoltage129 "电池包5的单体电压129";
CM_ SG_ 2556493909 P5_CellVoltage130 "电池包5的单体电压130";
CM_ SG_ 2556493909 P5_CellVoltage131 "电池包5的单体电压131";
CM_ SG_ 2556493909 P5_CellVoltage132 "电池包5的单体电压132";
CM_ SG_ 2556493909 P5_BalSwCell129 "电池包5的电芯129均衡状态";
CM_ SG_ 2556493909 P5_BalSwCell130 "电池包5的电芯130均衡状态";
CM_ SG_ 2556493909 P5_BalSwCell131 "电池包5的电芯131均衡状态";
CM_ SG_ 2556493909 P5_BalSwCell132 "电池包5的电芯132均衡状态";
CM_ SG_ 2556559445 P5_CellVoltage133 "电池包5的单体电压133";
CM_ SG_ 2556559445 P5_CellVoltage134 "电池包5的单体电压134";
CM_ SG_ 2556559445 P5_CellVoltage135 "电池包5的单体电压135";
CM_ SG_ 2556559445 P5_CellVoltage136 "电池包5的单体电压136";
CM_ SG_ 2556559445 P5_BalSwCell133 "电池包5的电芯133均衡状态";
CM_ SG_ 2556559445 P5_BalSwCell134 "电池包5的电芯134均衡状态";
CM_ SG_ 2556559445 P5_BalSwCell135 "电池包5的电芯135均衡状态";
CM_ SG_ 2556559445 P5_BalSwCell136 "电池包5的电芯136均衡状态";
CM_ SG_ 2556624981 P5_CellVoltage137 "电池包5的单体电压137";
CM_ SG_ 2556624981 P5_CellVoltage138 "电池包5的单体电压138";
CM_ SG_ 2556624981 P5_CellVoltage139 "电池包5的单体电压139";
CM_ SG_ 2556624981 P5_CellVoltage140 "电池包5的单体电压140";
CM_ SG_ 2556624981 P5_BalSwCell137 "电池包5的电芯137均衡状态";
CM_ SG_ 2556624981 P5_BalSwCell138 "电池包5的电芯138均衡状态";
CM_ SG_ 2556624981 P5_BalSwCell139 "电池包5的电芯139均衡状态";
CM_ SG_ 2556624981 P5_BalSwCell140 "电池包5的电芯140均衡状态";
CM_ SG_ 2556690517 P5_CellVoltage141 "电池包5的单体电压141";
CM_ SG_ 2556690517 P5_CellVoltage142 "电池包5的单体电压142";
CM_ SG_ 2556690517 P5_CellVoltage143 "电池包5的单体电压143";
CM_ SG_ 2556690517 P5_CellVoltage144 "电池包5的单体电压144";
CM_ SG_ 2556690517 P5_BalSwCell141 "电池包5的电芯141均衡状态";
CM_ SG_ 2556690517 P5_BalSwCell142 "电池包5的电芯142均衡状态";
CM_ SG_ 2556690517 P5_BalSwCell143 "电池包5的电芯143均衡状态";
CM_ SG_ 2556690517 P5_BalSwCell144 "电池包5的电芯144均衡状态";
CM_ SG_ 2556756053 P5_CellVoltage145 "电池包5的单体电压145";
CM_ SG_ 2556756053 P5_CellVoltage146 "电池包5的单体电压146";
CM_ SG_ 2556756053 P5_CellVoltage147 "电池包5的单体电压147";
CM_ SG_ 2556756053 P5_CellVoltage148 "电池包5的单体电压148";
CM_ SG_ 2556756053 P5_BalSwCell145 "电池包5的电芯145均衡状态";
CM_ SG_ 2556756053 P5_BalSwCell146 "电池包5的电芯146均衡状态";
CM_ SG_ 2556756053 P5_BalSwCell147 "电池包5的电芯147均衡状态";
CM_ SG_ 2556756053 P5_BalSwCell148 "电池包5的电芯148均衡状态";
CM_ SG_ 2556821589 P5_CellVoltage149 "电池包5的单体电压149";
CM_ SG_ 2556821589 P5_CellVoltage150 "电池包5的单体电压150";
CM_ SG_ 2556821589 P5_CellVoltage151 "电池包5的单体电压151";
CM_ SG_ 2556821589 P5_CellVoltage152 "电池包5的单体电压152";
CM_ SG_ 2556821589 P5_BalSwCell149 "电池包5的电芯149均衡状态";
CM_ SG_ 2556821589 P5_BalSwCell150 "电池包5的电芯150均衡状态";
CM_ SG_ 2556821589 P5_BalSwCell151 "电池包5的电芯151均衡状态";
CM_ SG_ 2556821589 P5_BalSwCell152 "电池包5的电芯152均衡状态";
CM_ SG_ 2556887125 P5_CellVoltage153 "电池包5的单体电压153";
CM_ SG_ 2556887125 P5_CellVoltage154 "电池包5的单体电压154";
CM_ SG_ 2556887125 P5_CellVoltage155 "电池包5的单体电压155";
CM_ SG_ 2556887125 P5_CellVoltage156 "电池包5的单体电压156";
CM_ SG_ 2556887125 P5_BalSwCell153 "电池包5的电芯153均衡状态";
CM_ SG_ 2556887125 P5_BalSwCell154 "电池包5的电芯154均衡状态";
CM_ SG_ 2556887125 P5_BalSwCell155 "电池包5的电芯155均衡状态";
CM_ SG_ 2556887125 P5_BalSwCell156 "电池包5的电芯156均衡状态";
CM_ SG_ 2556952661 P5_CellVoltage157 "电池包5的单体电压157";
CM_ SG_ 2556952661 P5_CellVoltage158 "电池包5的单体电压158";
CM_ SG_ 2556952661 P5_CellVoltage159 "电池包5的单体电压159";
CM_ SG_ 2556952661 P5_CellVoltage160 "电池包5的单体电压160";
CM_ SG_ 2556952661 P5_BalSwCell157 "电池包5的电芯157均衡状态";
CM_ SG_ 2556952661 P5_BalSwCell158 "电池包5的电芯158均衡状态";
CM_ SG_ 2556952661 P5_BalSwCell159 "电池包5的电芯159均衡状态";
CM_ SG_ 2556952661 P5_BalSwCell160 "电池包5的电芯160均衡状态";
CM_ SG_ 2557018197 P5_CellVoltage161 "电池包5的单体电压161";
CM_ SG_ 2557018197 P5_CellVoltage162 "电池包5的单体电压162";
CM_ SG_ 2557018197 P5_CellVoltage163 "电池包5的单体电压163";
CM_ SG_ 2557018197 P5_CellVoltage164 "电池包5的单体电压164";
CM_ SG_ 2557018197 P5_BalSwCell161 "电池包5的电芯161均衡状态";
CM_ SG_ 2557018197 P5_BalSwCell162 "电池包5的电芯162均衡状态";
CM_ SG_ 2557018197 P5_BalSwCell163 "电池包5的电芯163均衡状态";
CM_ SG_ 2557018197 P5_BalSwCell164 "电池包5的电芯164均衡状态";
CM_ SG_ 2557083733 P5_CellVoltage165 "电池包5的单体电压165";
CM_ SG_ 2557083733 P5_CellVoltage166 "电池包5的单体电压166";
CM_ SG_ 2557083733 P5_CellVoltage167 "电池包5的单体电压167";
CM_ SG_ 2557083733 P5_CellVoltage168 "电池包5的单体电压168";
CM_ SG_ 2557083733 P5_BalSwCell165 "电池包5的电芯165均衡状态";
CM_ SG_ 2557083733 P5_BalSwCell166 "电池包5的电芯166均衡状态";
CM_ SG_ 2557083733 P5_BalSwCell167 "电池包5的电芯167均衡状态";
CM_ SG_ 2557083733 P5_BalSwCell168 "电池包5的电芯168均衡状态";
CM_ SG_ 2557149269 P5_CellVoltage169 "电池包5的单体电压169";
CM_ SG_ 2557149269 P5_CellVoltage170 "电池包5的单体电压170";
CM_ SG_ 2557149269 P5_CellVoltage171 "电池包5的单体电压171";
CM_ SG_ 2557149269 P5_CellVoltage172 "电池包5的单体电压172";
CM_ SG_ 2557149269 P5_BalSwCell169 "电池包5的电芯169均衡状态";
CM_ SG_ 2557149269 P5_BalSwCell170 "电池包5的电芯170均衡状态";
CM_ SG_ 2557149269 P5_BalSwCell171 "电池包5的电芯171均衡状态";
CM_ SG_ 2557149269 P5_BalSwCell172 "电池包5的电芯172均衡状态";
CM_ SG_ 2557214805 P5_CellVoltage173 "电池包5的单体电压173";
CM_ SG_ 2557214805 P5_CellVoltage174 "电池包5的单体电压174";
CM_ SG_ 2557214805 P5_CellVoltage175 "电池包5的单体电压175";
CM_ SG_ 2557214805 P5_CellVoltage176 "电池包5的单体电压176";
CM_ SG_ 2557214805 P5_BalSwCell173 "电池包5的电芯173均衡状态";
CM_ SG_ 2557214805 P5_BalSwCell174 "电池包5的电芯174均衡状态";
CM_ SG_ 2557214805 P5_BalSwCell175 "电池包5的电芯175均衡状态";
CM_ SG_ 2557214805 P5_BalSwCell176 "电池包5的电芯176均衡状态";
CM_ SG_ 2557280341 P5_CellVoltage177 "电池包5的单体电压177";
CM_ SG_ 2557280341 P5_CellVoltage178 "电池包5的单体电压178";
CM_ SG_ 2557280341 P5_CellVoltage179 "电池包5的单体电压179";
CM_ SG_ 2557280341 P5_CellVoltage180 "电池包5的单体电压180";
CM_ SG_ 2557280341 P5_BalSwCell177 "电池包5的电芯177均衡状态";
CM_ SG_ 2557280341 P5_BalSwCell178 "电池包5的电芯178均衡状态";
CM_ SG_ 2557280341 P5_BalSwCell179 "电池包5的电芯179均衡状态";
CM_ SG_ 2557280341 P5_BalSwCell180 "电池包5的电芯180均衡状态";
CM_ SG_ 2557345877 P5_CellVoltage181 "电池包5的单体电压181";
CM_ SG_ 2557345877 P5_CellVoltage182 "电池包5的单体电压182";
CM_ SG_ 2557345877 P5_CellVoltage183 "电池包5的单体电压183";
CM_ SG_ 2557345877 P5_CellVoltage184 "电池包5的单体电压184";
CM_ SG_ 2557345877 P5_BalSwCell181 "电池包5的电芯181均衡状态";
CM_ SG_ 2557345877 P5_BalSwCell182 "电池包5的电芯182均衡状态";
CM_ SG_ 2557345877 P5_BalSwCell183 "电池包5的电芯183均衡状态";
CM_ SG_ 2557345877 P5_BalSwCell184 "电池包5的电芯184均衡状态";
CM_ SG_ 2557411413 P5_CellVoltage185 "电池包5的单体电压185";
CM_ SG_ 2557411413 P5_CellVoltage186 "电池包5的单体电压186";
CM_ SG_ 2557411413 P5_CellVoltage187 "电池包5的单体电压187";
CM_ SG_ 2557411413 P5_CellVoltage188 "电池包5的单体电压188";
CM_ SG_ 2557411413 P5_BalSwCell185 "电池包5的电芯185均衡状态";
CM_ SG_ 2557411413 P5_BalSwCell186 "电池包5的电芯186均衡状态";
CM_ SG_ 2557411413 P5_BalSwCell187 "电池包5的电芯187均衡状态";
CM_ SG_ 2557411413 P5_BalSwCell188 "电池包5的电芯188均衡状态";
CM_ SG_ 2557476949 P5_CellVoltage189 "电池包5的单体电压189";
CM_ SG_ 2557476949 P5_CellVoltage190 "电池包5的单体电压190";
CM_ SG_ 2557476949 P5_CellVoltage191 "电池包5的单体电压191";
CM_ SG_ 2557476949 P5_CellVoltage192 "电池包5的单体电压192";
CM_ SG_ 2557476949 P5_BalSwCell189 "电池包5的电芯189均衡状态";
CM_ SG_ 2557476949 P5_BalSwCell190 "电池包5的电芯190均衡状态";
CM_ SG_ 2557476949 P5_BalSwCell191 "电池包5的电芯191均衡状态";
CM_ SG_ 2557476949 P5_BalSwCell192 "电池包5的电芯192均衡状态";
CM_ SG_ 2558525525 P5_CellTemp1 "电池包5的单体温度1";
CM_ SG_ 2558525525 P5_CellTemp2 "电池包5的单体温度2";
CM_ SG_ 2558525525 P5_CellTemp3 "电池包5的单体温度3";
CM_ SG_ 2558525525 P5_CellTemp4 "电池包5的单体温度4";
CM_ SG_ 2558525525 P5_CellTemp5 "电池包5的单体温度5";
CM_ SG_ 2558591061 P5_CellTemp6 "电池包5的单体温度6";
CM_ SG_ 2558591061 P5_CellTemp7 "电池包5的单体温度7";
CM_ SG_ 2558591061 P5_CellTemp8 "电池包5的单体温度8";
CM_ SG_ 2558591061 P5_CellTemp9 "电池包5的单体温度9";
CM_ SG_ 2558591061 P5_CellTemp10 "电池包5的单体温度10";
CM_ SG_ 2558656597 P5_CellTemp11 "电池包5的单体温度11";
CM_ SG_ 2558656597 P5_CellTemp12 "电池包5的单体温度12";
CM_ SG_ 2558656597 P5_CellTemp13 "电池包5的单体温度13";
CM_ SG_ 2558656597 P5_CellTemp14 "电池包5的单体温度14";
CM_ SG_ 2558656597 P5_CellTemp15 "电池包5的单体温度15";
CM_ SG_ 2558722133 P5_CellTemp16 "电池包5的单体温度16";
CM_ SG_ 2558722133 P5_CellTemp17 "电池包5的单体温度17";
CM_ SG_ 2558722133 P5_CellTemp18 "电池包5的单体温度18";
CM_ SG_ 2558722133 P5_CellTemp19 "电池包5的单体温度19";
CM_ SG_ 2558722133 P5_CellTemp20 "电池包5的单体温度20";
CM_ SG_ 2558787669 P5_CellTemp21 "电池包5的单体温度21";
CM_ SG_ 2558787669 P5_CellTemp22 "电池包5的单体温度22";
CM_ SG_ 2558787669 P5_CellTemp23 "电池包5的单体温度23";
CM_ SG_ 2558787669 P5_CellTemp24 "电池包5的单体温度24";
CM_ SG_ 2558787669 P5_CellTemp25 "电池包5的单体温度25";
CM_ SG_ 2558853205 P5_CellTemp26 "电池包5的单体温度26";
CM_ SG_ 2558853205 P5_CellTemp27 "电池包5的单体温度27";
CM_ SG_ 2558853205 P5_CellTemp28 "电池包5的单体温度28";
CM_ SG_ 2558853205 P5_CellTemp29 "电池包5的单体温度29";
CM_ SG_ 2558853205 P5_CellTemp30 "电池包5的单体温度30";
CM_ SG_ 2558918741 P5_CellTemp31 "电池包5的单体温度31";
CM_ SG_ 2558918741 P5_CellTemp32 "电池包5的单体温度32";
CM_ SG_ 2558918741 P5_CellTemp33 "电池包5的单体温度33";
CM_ SG_ 2558918741 P5_CellTemp34 "电池包5的单体温度34";
CM_ SG_ 2558918741 P5_CellTemp35 "电池包5的单体温度35";
CM_ SG_ 2558984277 P5_CellTemp36 "电池包5的单体温度36";
CM_ SG_ 2558984277 P5_CellTemp37 "电池包5的单体温度37";
CM_ SG_ 2558984277 P5_CellTemp38 "电池包5的单体温度38";
CM_ SG_ 2558984277 P5_CellTemp39 "电池包5的单体温度39";
CM_ SG_ 2558984277 P5_CellTemp40 "电池包5的单体温度40";
CM_ SG_ 2559049813 P5_CellTemp41 "电池包5的单体温度41";
CM_ SG_ 2559049813 P5_CellTemp42 "电池包5的单体温度42";
CM_ SG_ 2559049813 P5_CellTemp43 "电池包5的单体温度43";
CM_ SG_ 2559049813 P5_CellTemp44 "电池包5的单体温度44";
CM_ SG_ 2559049813 P5_CellTemp45 "电池包5的单体温度45";
CM_ SG_ 2559115349 P5_CellTemp46 "电池包5的单体温度46";
CM_ SG_ 2559115349 P5_CellTemp47 "电池包5的单体温度47";
CM_ SG_ 2559115349 P5_CellTemp48 "电池包5的单体温度48";
CM_ SG_ 2559115349 P5_CellTemp49 "电池包5的单体温度49";
CM_ SG_ 2559115349 P5_CellTemp50 "电池包5的单体温度50";
CM_ SG_ 2559180885 P5_CellTemp51 "电池包5的单体温度51";
CM_ SG_ 2559180885 P5_CellTemp52 "电池包5的单体温度52";
CM_ SG_ 2559180885 P5_CellTemp53 "电池包5的单体温度53";
CM_ SG_ 2559180885 P5_CellTemp54 "电池包5的单体温度54";
CM_ SG_ 2559180885 P5_CellTemp55 "电池包5的单体温度55";
CM_ SG_ 2559246421 P5_CellTemp56 "电池包5的单体温度56";
CM_ SG_ 2559246421 P5_CellTemp57 "电池包5的单体温度57";
CM_ SG_ 2559246421 P5_CellTemp58 "电池包5的单体温度58";
CM_ SG_ 2559246421 P5_CellTemp59 "电池包5的单体温度59";
CM_ SG_ 2559246421 P5_CellTemp60 "电池包5的单体温度60";
CM_ SG_ 2559311957 P5_CellTemp61 "电池包5的单体温度61";
CM_ SG_ 2559311957 P5_CellTemp62 "电池包5的单体温度62";
CM_ SG_ 2559311957 P5_CellTemp63 "电池包5的单体温度63";
CM_ SG_ 2559311957 P5_CellTemp64 "电池包5的单体温度64";
CM_ SG_ 2559311957 P5_CellTemp65 "电池包5的单体温度65";
CM_ SG_ 2559377493 P5_CellTemp66 "电池包5的单体温度66";
CM_ SG_ 2559377493 P5_CellTemp67 "电池包5的单体温度67";
CM_ SG_ 2559377493 P5_CellTemp68 "电池包5的单体温度68";
CM_ SG_ 2559377493 P5_CellTemp69 "电池包5的单体温度69";
CM_ SG_ 2559377493 P5_CellTemp70 "电池包5的单体温度70";
CM_ SG_ 2559443029 P5_CellTemp71 "电池包5的单体温度71";
CM_ SG_ 2559443029 P5_CellTemp72 "电池包5的单体温度72";
CM_ SG_ 2559443029 P5_CellTemp73 "电池包5的单体温度73";
CM_ SG_ 2559443029 P5_CellTemp74 "电池包5的单体温度74";
CM_ SG_ 2559443029 P5_CellTemp75 "电池包5的单体温度75";
CM_ SG_ 2559508565 P5_CellTemp76 "电池包5的单体温度76";
CM_ SG_ 2559508565 P5_CellTemp77 "电池包5的单体温度77";
CM_ SG_ 2559508565 P5_CellTemp78 "电池包5的单体温度78";
CM_ SG_ 2559508565 P5_CellTemp79 "电池包5的单体温度79";
CM_ SG_ 2559508565 P5_CellTemp80 "电池包5的单体温度80";
CM_ SG_ 2559574101 P5_CellTemp81 "电池包5的单体温度81";
CM_ SG_ 2559574101 P5_CellTemp82 "电池包5的单体温度82";
CM_ SG_ 2559574101 P5_CellTemp83 "电池包5的单体温度83";
CM_ SG_ 2559574101 P5_CellTemp84 "电池包5的单体温度84";
CM_ SG_ 2559574101 P5_CellTemp85 "电池包5的单体温度85";
CM_ SG_ 2559639637 P5_CellTemp86 "电池包5的单体温度86";
CM_ SG_ 2559639637 P5_CellTemp87 "电池包5的单体温度87";
CM_ SG_ 2559639637 P5_CellTemp88 "电池包5的单体温度88";
CM_ SG_ 2559639637 P5_CellTemp89 "电池包5的单体温度89";
CM_ SG_ 2559639637 P5_CellTemp90 "电池包5的单体温度90";
CM_ SG_ 2559705173 P5_CellTemp91 "电池包5的单体温度91";
CM_ SG_ 2559705173 P5_CellTemp92 "电池包5的单体温度92";
CM_ SG_ 2559705173 P5_CellTemp93 "电池包5的单体温度93";
CM_ SG_ 2559705173 P5_CellTemp94 "电池包5的单体温度94";
CM_ SG_ 2559705173 P5_CellTemp95 "电池包5的单体温度95";
CM_ SG_ 2559770709 P5_CellTemp96 "电池包5的单体温度96";
CM_ SG_ 2559770709 P5_CellTemp97 "电池包5的单体温度97";
CM_ SG_ 2559770709 P5_CellTemp98 "电池包5的单体温度98";
CM_ SG_ 2559770709 P5_CellTemp99 "电池包5的单体温度99";
CM_ SG_ 2559770709 P5_CellTemp100 "电池包5的单体温度100";
CM_ SG_ 2559836245 P5_CellTemp101 "电池包5的单体温度101";
CM_ SG_ 2559836245 P5_CellTemp102 "电池包5的单体温度102";
CM_ SG_ 2559836245 P5_CellTemp103 "电池包5的单体温度103";
CM_ SG_ 2559836245 P5_CellTemp104 "电池包5的单体温度104";
CM_ SG_ 2559836245 P5_CellTemp105 "电池包5的单体温度105";
CM_ SG_ 2559901781 P5_CellTemp106 "电池包5的单体温度106";
CM_ SG_ 2559901781 P5_CellTemp107 "电池包5的单体温度107";
CM_ SG_ 2559901781 P5_CellTemp108 "电池包5的单体温度108";
CM_ SG_ 2559901781 P5_CellTemp109 "电池包5的单体温度109";
CM_ SG_ 2559901781 P5_CellTemp110 "电池包5的单体温度110";
CM_ SG_ 2559967317 P5_CellTemp111 "电池包5的单体温度111";
CM_ SG_ 2559967317 P5_CellTemp112 "电池包5的单体温度112";
CM_ SG_ 2559967317 P5_CellTemp113 "电池包5的单体温度113";
CM_ SG_ 2559967317 P5_CellTemp114 "电池包5的单体温度114";
CM_ SG_ 2559967317 P5_CellTemp115 "电池包5的单体温度115";
CM_ SG_ 2560032853 P5_CellTemp116 "电池包5的单体温度116";
CM_ SG_ 2560032853 P5_CellTemp117 "电池包5的单体温度117";
CM_ SG_ 2560032853 P5_CellTemp118 "电池包5的单体温度118";
CM_ SG_ 2560032853 P5_CellTemp119 "电池包5的单体温度119";
CM_ SG_ 2560032853 P5_CellTemp120 "电池包5的单体温度120";
CM_ SG_ 2560098389 P5_CellTemp121 "电池包5的单体温度121";
CM_ SG_ 2560098389 P5_CellTemp122 "电池包5的单体温度122";
CM_ SG_ 2560098389 P5_CellTemp123 "电池包5的单体温度123";
CM_ SG_ 2560098389 P5_CellTemp124 "电池包5的单体温度124";
CM_ SG_ 2560098389 P5_CellTemp125 "电池包5的单体温度125";
CM_ SG_ 2560163925 P5_CellTemp126 "电池包5的单体温度126";
CM_ SG_ 2560163925 P5_CellTemp127 "电池包5的单体温度127";
CM_ SG_ 2560163925 P5_CellTemp128 "电池包5的单体温度128";
CM_ SG_ 2560163925 P5_CellTemp129 "电池包5的单体温度129";
CM_ SG_ 2560163925 P5_CellTemp130 "电池包5的单体温度130";
CM_ SG_ 2560229461 P5_CellTemp131 "电池包5的单体温度131";
CM_ SG_ 2560229461 P5_CellTemp132 "电池包5的单体温度132";
CM_ SG_ 2560229461 P5_CellTemp133 "电池包5的单体温度133";
CM_ SG_ 2560229461 P5_CellTemp134 "电池包5的单体温度134";
CM_ SG_ 2560229461 P5_CellTemp135 "电池包5的单体温度135";
CM_ SG_ 2560294997 P5_CellTemp136 "电池包5的单体温度136";
CM_ SG_ 2560294997 P5_CellTemp137 "电池包5的单体温度137";
CM_ SG_ 2560294997 P5_CellTemp138 "电池包5的单体温度138";
CM_ SG_ 2560294997 P5_CellTemp139 "电池包5的单体温度139";
CM_ SG_ 2560294997 P5_CellTemp140 "电池包5的单体温度140";
CM_ SG_ 2560360533 P5_CellTemp141 "电池包5的单体温度141";
CM_ SG_ 2560360533 P5_CellTemp142 "电池包5的单体温度142";
CM_ SG_ 2560360533 P5_CellTemp143 "电池包5的单体温度143";
CM_ SG_ 2560360533 P5_CellTemp144 "电池包5的单体温度144";
CM_ SG_ 2560360533 P5_CellTemp145 "电池包5的单体温度145";
CM_ SG_ 2560426069 P5_CellTemp146 "电池包5的单体温度146";
CM_ SG_ 2560426069 P5_CellTemp147 "电池包5的单体温度147";
CM_ SG_ 2560426069 P5_CellTemp148 "电池包5的单体温度148";
CM_ SG_ 2560426069 P5_CellTemp149 "电池包5的单体温度149";
CM_ SG_ 2560426069 P5_CellTemp150 "电池包5的单体温度150";
CM_ SG_ 2560491605 P5_CellTemp151 "电池包5的单体温度151";
CM_ SG_ 2560491605 P5_CellTemp152 "电池包5的单体温度152";
CM_ SG_ 2560491605 P5_CellTemp153 "电池包5的单体温度153";
CM_ SG_ 2560491605 P5_CellTemp154 "电池包5的单体温度154";
CM_ SG_ 2560491605 P5_CellTemp155 "电池包5的单体温度155";
CM_ SG_ 2560557141 P5_CellTemp156 "电池包5的单体温度156";
CM_ SG_ 2560557141 P5_CellTemp157 "电池包5的单体温度157";
CM_ SG_ 2560557141 P5_CellTemp158 "电池包5的单体温度158";
CM_ SG_ 2560557141 P5_CellTemp159 "电池包5的单体温度159";
CM_ SG_ 2560557141 P5_CellTemp160 "电池包5的单体温度160";
CM_ SG_ 2560622677 P5_CellTemp161 "电池包5的单体温度161";
CM_ SG_ 2560622677 P5_CellTemp162 "电池包5的单体温度162";
CM_ SG_ 2560622677 P5_CellTemp163 "电池包5的单体温度163";
CM_ SG_ 2560622677 P5_CellTemp164 "电池包5的单体温度164";
CM_ SG_ 2560622677 P5_CellTemp165 "电池包5的单体温度165";
CM_ SG_ 2560688213 P5_CellTemp166 "电池包5的单体温度166";
CM_ SG_ 2560688213 P5_CellTemp167 "电池包5的单体温度167";
CM_ SG_ 2560688213 P5_CellTemp168 "电池包5的单体温度168";
CM_ SG_ 2560688213 P5_CellTemp169 "电池包5的单体温度169";
CM_ SG_ 2560688213 P5_CellTemp170 "电池包5的单体温度170";
CM_ SG_ 2560753749 P5_CellTemp171 "电池包5的单体温度171";
CM_ SG_ 2560753749 P5_CellTemp172 "电池包5的单体温度172";
CM_ SG_ 2560753749 P5_CellTemp173 "电池包5的单体温度173";
CM_ SG_ 2560753749 P5_CellTemp174 "电池包5的单体温度174";
CM_ SG_ 2560753749 P5_CellTemp175 "电池包5的单体温度175";
CM_ SG_ 2560819285 P5_CellTemp176 "电池包5的单体温度176";
CM_ SG_ 2560819285 P5_CellTemp177 "电池包5的单体温度177";
CM_ SG_ 2560819285 P5_CellTemp178 "电池包5的单体温度178";
CM_ SG_ 2560819285 P5_CellTemp179 "电池包5的单体温度179";
CM_ SG_ 2560819285 P5_CellTemp180 "电池包5的单体温度180";
CM_ SG_ 2560884821 P5_CellTemp181 "电池包5的单体温度181";
CM_ SG_ 2560884821 P5_CellTemp182 "电池包5的单体温度182";
CM_ SG_ 2560884821 P5_CellTemp183 "电池包5的单体温度183";
CM_ SG_ 2560884821 P5_CellTemp184 "电池包5的单体温度184";
CM_ SG_ 2560884821 P5_CellTemp185 "电池包5的单体温度185";
CM_ SG_ 2560950357 P5_CellTemp186 "电池包5的单体温度186";
CM_ SG_ 2560950357 P5_CellTemp187 "电池包5的单体温度187";
CM_ SG_ 2560950357 P5_CellTemp188 "电池包5的单体温度188";
CM_ SG_ 2560950357 P5_CellTemp189 "电池包5的单体温度189";
CM_ SG_ 2560950357 P5_CellTemp190 "电池包5的单体温度190";
CM_ SG_ 2561015893 P5_CellTemp191 "电池包5的单体温度191";
CM_ SG_ 2561015893 P5_CellTemp192 "电池包5的单体温度192";
CM_ SG_ 2561015893 P5_DatLen16DbgInfo1 "长度为16的调试信息1";
CM_ SG_ 2561015893 P5_DatLen16DbgInfo2 "长度为16的调试信息2";
CM_ SG_ 2561015893 P5_DatLen16DbgInfo3 "长度为16的调试信息3";
CM_ SG_ 2561015893 P5_DatLen16DbgInfo4 "长度为16的调试信息4";
CM_ SG_ 2550399078 P6_BMSPwrSuplVlt1 "电池包6的BMS供电电源电压1";
CM_ SG_ 2550399078 P6_BMSPwrSuplVlt2 "电池包6的BMS供电电源电压2";
CM_ SG_ 2550399078 P6_ChrgStationAuxPwrSuplVlt "电池包6的快充桩A+电压";
CM_ SG_ 2550399078 P6_BMSKL15ON "电池包6的BMS唤醒信号";
CM_ SG_ 2550399078 P6_DCStepState "电池包6的充电状态机";
CM_ SG_ 2550399078 P6_ExtLvWakeup_28VOnly "电池包6的外部唤醒";
CM_ SG_ 2550464614 P6_PackVltUprLmt "电池包6的电压使用上限";
CM_ SG_ 2550464614 P6_PackVltLoLmt "电池包6的电压使用下限";
CM_ SG_ 2550464614 P6_PackMaxDschrgCrnt "电池包6的最大允许放电电流";
CM_ SG_ 2550464614 P6_PackMaxChrgCrnt "电池包6的最大允许充电电流";
CM_ SG_ 2550530150 P6_PackDschrgPwrLmt "电池包6的放电功率限值";
CM_ SG_ 2550530150 P6_PackDschrgPwrStat "电池包6的放电功率状态";
CM_ SG_ 2550530150 P6_PackChrgPwrLmt "电池包6的充电功率限值";
CM_ SG_ 2550530150 P6_PackChrgPwrStat "电池包6的充电功率状态";
CM_ SG_ 2550595686 P6_ChrgrCplrStat "电池包6的充电枪连接状态";
CM_ SG_ 2550595686 P6_HVBattChrgSysStatus "电池包6的充电系统状态";
CM_ SG_ 2550595686 P6_DCChrgCrntCmd "电池包6的直流充电请求电流";
CM_ SG_ 2550595686 P6_CC2Vlt "电池包6的CC2电压值";
CM_ SG_ 2550595686 P6_DCRcptPosTemp "电池包6的快充充电插座正极温度";
CM_ SG_ 2550595686 P6_DCRcptNegTemp "电池包6的快充充电插座负极温度";
CM_ SG_ 2550595686 P6_Tm2FullChrg "电池包6满充剩余时间";
CM_ SG_ 2550661222 P6_Inlet1ClntTemp "进水口1冷却液温度";
CM_ SG_ 2550661222 P6_Inlet2ClntTemp "进水口2冷却液温度";
CM_ SG_ 2550661222 P6_Outlet1ClntTemp "出水口1冷却液温度";
CM_ SG_ 2550661222 P6_Outlet2ClntTemp "出水口2冷却液温度";
CM_ SG_ 2550661222 P6_TrgtClntTemp "冷却水目标温度";
CM_ SG_ 2550661222 P6_TrgtClntFlowRate "冷却水目标流量";
CM_ SG_ 2550726758 P6_MaxCellVlt "电池包6的最大单体电压";
CM_ SG_ 2550726758 P6_MaxCellVltNum "电池包6的最大单体电压编号";
CM_ SG_ 2550726758 P6_MinCellVlt "电池包6的最小单体电压";
CM_ SG_ 2550726758 P6_MinCellVltNum "电池包6的最小单体电压编号";
CM_ SG_ 2550726758 P6_AvgCellVlt "电池包6的平均单体电压";
CM_ SG_ 2550792294 P6_MaxCellTemp "电池包6的最高单体温度";
CM_ SG_ 2550792294 P6_MaxCellTempNum "电池包6的最高单体温度编号";
CM_ SG_ 2550792294 P6_MinCellTemp "电池包6的最低单体温度";
CM_ SG_ 2550792294 P6_MinCellTempNum "电池包6的最低单体温度编号";
CM_ SG_ 2550792294 P6_AvgCellTemp "电池包6的单体平均温度";
CM_ SG_ 2550857830 P6_PackTotFltNum "电池包6的电池故障总数";
CM_ SG_ 2550857830 P6_CellOverVoltage "电池包6的单体过压";
CM_ SG_ 2550857830 P6_CellUnderVoltage "电池包6的单体欠压";
CM_ SG_ 2550857830 P6_CellVoltageDiffHi "电池包6的单体压差过大";
CM_ SG_ 2550857830 P6_PackOverVoltage "电池包6的电压过高";
CM_ SG_ 2550857830 P6_PackUnderVoltage "电池包6的电压过低";
CM_ SG_ 2550857830 P6_CellOverTemp "电池包6的单体过温";
CM_ SG_ 2550857830 P6_CellTempLow "电池包6的单体温度过低";
CM_ SG_ 2550857830 P6_CellTempDiffHi "电池包6的单体温度差异过大";
CM_ SG_ 2550857830 P6_PackDschrgCrntHi "电池包6的放电电流过流";
CM_ SG_ 2550857830 P6_PackChrgCrntHi "电池包6的充电电流过流";
CM_ SG_ 2550857830 P6_PackCrnSnsr1OffsetHi "电池包6的电流传感器1零漂过大";
CM_ SG_ 2550857830 P6_HVIsolFlt "电池包6的高压绝缘故障";
CM_ SG_ 2550857830 P6_HVILFlt "电池包6的高压互锁故障";
CM_ SG_ 2550857830 P6_ThrmlRunaway "电池包6的热失控故障";
CM_ SG_ 2550857830 P6_CellVoltInvalid "电池包6的单体电压采样失效";
CM_ SG_ 2550857830 P6_CellTempInvalid "电池包6的电芯温度采样失效";
CM_ SG_ 2550857830 P6_DaisyChainComFlt "电池包6的菊花链通信故障";
CM_ SG_ 2550857830 P6_PackVoltRatFlt "电池包6的总电压与单体电压总和偏差过大";
CM_ SG_ 2550857830 P6_CrntSnsr1Invalid "电池包6的电流传感器1电流采样失效";
CM_ SG_ 2550857830 P6_CrntSnsr1OOR "电池包6的电流传感器1电流超出采样范围";
CM_ SG_ 2550857830 P6_CrntSnsr2Invalid "电池包6的电流传感器2电流采样失效";
CM_ SG_ 2550857830 P6_CrntSnsr2OOR "电池包6的电流传感器2电流超出采样范围";
CM_ SG_ 2550857830 P6_PackCrnSnsr2OffsetHi "电池包6的电流传感器2零漂过大";
CM_ SG_ 2550857830 P6_OutofEnergy "电池包6的电池剩余电量低";
CM_ SG_ 2550857830 P6_IsolDetCircErr "电池包6的绝缘检测电路失效";
CM_ SG_ 2550857830 P6_HVILCircShortToGND "电池包6的高压互锁对地短路";
CM_ SG_ 2550857830 P6_HVILCircShortToPwr "电池包6的高压互锁对电源短路";
CM_ SG_ 2550923366 P6_MainPosCntctrStkClsd "电池包6的主正继电器粘连故障";
CM_ SG_ 2550923366 P6_MainPosCntctrStkOpn "电池包6的主正继电器常开故障";
CM_ SG_ 2550923366 P6_MainNegCntctr1StkClsd "电池包6的主负继电器1粘连故障";
CM_ SG_ 2550923366 P6_MainNegCntctr1StkOpn "电池包6的主负继电器1常开故障";
CM_ SG_ 2550923366 P6_MainNegCntctr2StkClsd "电池包6的主负继电器2粘连故障";
CM_ SG_ 2550923366 P6_MainNegCntctr2StkOpn "电池包6的主负继电器2常开故障";
CM_ SG_ 2550923366 P6_PrechargTmOut "电池包6的预充超时故障";
CM_ SG_ 2550923366 P6_PrechrgCrntHi "电池包6的预充过流故障";
CM_ SG_ 2550923366 P6_ChrgCplrPosTempHi "电池包6的充电正极接口温度过高故障";
CM_ SG_ 2550923366 P6_ChrgCplrNegTempHi "电池包6的充电负极接口温度过高故障";
CM_ SG_ 2550923366 P6_BMSPwrSuplVlt1Hi "电池包6的BMS供电电压1过高";
CM_ SG_ 2550923366 P6_BMSPwrSuplVlt1Lo "电池包6的BMS供电电压1过低";
CM_ SG_ 2550923366 P6_BMSPwrSuplVlt2Hi "电池包6的BMS供电电压2过高";
CM_ SG_ 2550923366 P6_BMSPwrSuplVlt2Lo "电池包6的BMS供电电压2过低";
CM_ SG_ 2550923366 P6_CntctrCirPwrSuplVltLo "电池包6的继电器驱动供电电压过低";
CM_ SG_ 2550923366 P6_CntctrCirPwrSuplVltHi "电池包6的继电器驱动供电电压过高";
CM_ SG_ 2550923366 P6_CAN1BusOff "电池包6的CAN1通信Bus off";
CM_ SG_ 2550923366 P6_CAN1BusTmOut "电池包6的CAN1报文超时（Timeout）";
CM_ SG_ 2550923366 P6_CAN2BusOff "电池包6的CAN2通信Bus off";
CM_ SG_ 2550923366 P6_CAN2BusTmOut "电池包6的CAN2报文超时（Timeout）";
CM_ SG_ 2550923366 P6_CellBalCircTempHi "电池包6的均衡电路过温";
CM_ SG_ 2550923366 P6_ClntInTempHi "电池包6的入水口温度过高";
CM_ SG_ 2550923366 P6_ClntOutTempHi "电池包6的出水口温度过高";
CM_ SG_ 2550923366 P6_CellExtrmUdrVolt "电池包6的单体极限欠压";
CM_ SG_ 2550923366 P6_CellExtrmOvrVolt "电池包6的单体极限过压";
CM_ SG_ 2550923366 P6_Branch1DischrgCrntHi  "电池包6的支路1放电过流";
CM_ SG_ 2550923366 P6_Branch2DischrgCrntHi  "电池包6的支路2放电过流";
CM_ SG_ 2550923366 P6_Branch1ChrgCrntHi  "电池包6的支路1充电过流";
CM_ SG_ 2550923366 P6_Branch2ChrgCrntHi  "电池包6的支路2充电过流";
CM_ SG_ 2550923366 P6_InitFailed "电池包6的BMS初始化失败";
CM_ SG_ 2550923366 P6_PackErrCode "电池包6的故障代码";
CM_ SG_ 2550988902 P6_PackTotCellNum "电池包6的单体电池总数";
CM_ SG_ 2550988902 P6_PackTotCellTempSnsrNum "电池包6的单体温度传感器总数";
CM_ SG_ 2552299622 P6_BMSASWMajVerNum "电池包6的BMS应用层软件主版本号";
CM_ SG_ 2552299622 P6_BMSASWMinVerNum "电池包6的BMS应用层软件子版本号";
CM_ SG_ 2552299622 P6_BMSASWPatchVerNum "电池包6的BMS应用层软件修订版本号";
CM_ SG_ 2552299622 P6_BMSBSWMajVerNum "电池包6的BMS底层软件主版本号";
CM_ SG_ 2552299622 P6_BMSBSWMinVerNum "电池包6的BMS底层软件子版本号";
CM_ SG_ 2552299622 P6_BMSBSWPatchVerNum "电池包6的BMS底层软件修订版本号";
CM_ SG_ 2554396774 P6_CellVoltage1 "电池包6的单体电压1";
CM_ SG_ 2554396774 P6_CellVoltage2 "电池包6的单体电压2";
CM_ SG_ 2554396774 P6_CellVoltage3 "电池包6的单体电压3";
CM_ SG_ 2554396774 P6_CellVoltage4 "电池包6的单体电压4";
CM_ SG_ 2554396774 P6_BalSwCell1 "电池包6的电芯1均衡状态";
CM_ SG_ 2554396774 P6_BalSwCell2 "电池包6的电芯2均衡状态";
CM_ SG_ 2554396774 P6_BalSwCell3 "电池包6的电芯3均衡状态";
CM_ SG_ 2554396774 P6_BalSwCell4 "电池包6的电芯4均衡状态";
CM_ SG_ 2554462310 P6_CellVoltage5 "电池包6的单体电压5";
CM_ SG_ 2554462310 P6_CellVoltage6 "电池包6的单体电压6";
CM_ SG_ 2554462310 P6_CellVoltage7 "电池包6的单体电压7";
CM_ SG_ 2554462310 P6_CellVoltage8 "电池包6的单体电压8";
CM_ SG_ 2554462310 P6_BalSwCell5 "电池包6的电芯5均衡状态";
CM_ SG_ 2554462310 P6_BalSwCell6 "电池包6的电芯6均衡状态";
CM_ SG_ 2554462310 P6_BalSwCell7 "电池包6的电芯7均衡状态";
CM_ SG_ 2554462310 P6_BalSwCell8 "电池包6的电芯8均衡状态";
CM_ SG_ 2554527846 P6_CellVoltage9 "电池包6的单体电压9";
CM_ SG_ 2554527846 P6_CellVoltage10 "电池包6的单体电压10";
CM_ SG_ 2554527846 P6_CellVoltage11 "电池包6的单体电压11";
CM_ SG_ 2554527846 P6_CellVoltage12 "电池包6的单体电压12";
CM_ SG_ 2554527846 P6_BalSwCell9 "电池包6的电芯9均衡状态";
CM_ SG_ 2554527846 P6_BalSwCell10 "电池包6的电芯10均衡状态";
CM_ SG_ 2554527846 P6_BalSwCell11 "电池包6的电芯11均衡状态";
CM_ SG_ 2554527846 P6_BalSwCell12 "电池包6的电芯12均衡状态";
CM_ SG_ 2554593382 P6_CellVoltage13 "电池包6的单体电压13";
CM_ SG_ 2554593382 P6_CellVoltage14 "电池包6的单体电压14";
CM_ SG_ 2554593382 P6_CellVoltage15 "电池包6的单体电压15";
CM_ SG_ 2554593382 P6_CellVoltage16 "电池包6的单体电压16";
CM_ SG_ 2554593382 P6_BalSwCell13 "电池包6的电芯13均衡状态";
CM_ SG_ 2554593382 P6_BalSwCell14 "电池包6的电芯14均衡状态";
CM_ SG_ 2554593382 P6_BalSwCell15 "电池包6的电芯15均衡状态";
CM_ SG_ 2554593382 P6_BalSwCell16 "电池包6的电芯16均衡状态";
CM_ SG_ 2554658918 P6_CellVoltage17 "电池包6的单体电压17";
CM_ SG_ 2554658918 P6_CellVoltage18 "电池包6的单体电压18";
CM_ SG_ 2554658918 P6_CellVoltage19 "电池包6的单体电压19";
CM_ SG_ 2554658918 P6_CellVoltage20 "电池包6的单体电压20";
CM_ SG_ 2554658918 P6_BalSwCell17 "电池包6的电芯17均衡状态";
CM_ SG_ 2554658918 P6_BalSwCell18 "电池包6的电芯18均衡状态";
CM_ SG_ 2554658918 P6_BalSwCell19 "电池包6的电芯19均衡状态";
CM_ SG_ 2554658918 P6_BalSwCell20 "电池包6的电芯20均衡状态";
CM_ SG_ 2554724454 P6_CellVoltage21 "电池包6的单体电压21";
CM_ SG_ 2554724454 P6_CellVoltage22 "电池包6的单体电压22";
CM_ SG_ 2554724454 P6_CellVoltage23 "电池包6的单体电压23";
CM_ SG_ 2554724454 P6_CellVoltage24 "电池包6的单体电压24";
CM_ SG_ 2554724454 P6_BalSwCell21 "电池包6的电芯21均衡状态";
CM_ SG_ 2554724454 P6_BalSwCell22 "电池包6的电芯22均衡状态";
CM_ SG_ 2554724454 P6_BalSwCell23 "电池包6的电芯23均衡状态";
CM_ SG_ 2554724454 P6_BalSwCell24 "电池包6的电芯24均衡状态";
CM_ SG_ 2554789990 P6_CellVoltage25 "电池包6的单体电压25";
CM_ SG_ 2554789990 P6_CellVoltage26 "电池包6的单体电压26";
CM_ SG_ 2554789990 P6_CellVoltage27 "电池包6的单体电压27";
CM_ SG_ 2554789990 P6_CellVoltage28 "电池包6的单体电压28";
CM_ SG_ 2554789990 P6_BalSwCell25 "电池包6的电芯25均衡状态";
CM_ SG_ 2554789990 P6_BalSwCell26 "电池包6的电芯26均衡状态";
CM_ SG_ 2554789990 P6_BalSwCell27 "电池包6的电芯27均衡状态";
CM_ SG_ 2554789990 P6_BalSwCell28 "电池包6的电芯28均衡状态";
CM_ SG_ 2554855526 P6_CellVoltage29 "电池包6的单体电压29";
CM_ SG_ 2554855526 P6_CellVoltage30 "电池包6的单体电压30";
CM_ SG_ 2554855526 P6_CellVoltage31 "电池包6的单体电压31";
CM_ SG_ 2554855526 P6_CellVoltage32 "电池包6的单体电压32";
CM_ SG_ 2554855526 P6_BalSwCell29 "电池包6的电芯29均衡状态";
CM_ SG_ 2554855526 P6_BalSwCell30 "电池包6的电芯30均衡状态";
CM_ SG_ 2554855526 P6_BalSwCell31 "电池包6的电芯31均衡状态";
CM_ SG_ 2554855526 P6_BalSwCell32 "电池包6的电芯32均衡状态";
CM_ SG_ 2554921062 P6_CellVoltage33 "电池包6的单体电压33";
CM_ SG_ 2554921062 P6_CellVoltage34 "电池包6的单体电压34";
CM_ SG_ 2554921062 P6_CellVoltage35 "电池包6的单体电压35";
CM_ SG_ 2554921062 P6_CellVoltage36 "电池包6的单体电压36";
CM_ SG_ 2554921062 P6_BalSwCell33 "电池包6的电芯33均衡状态";
CM_ SG_ 2554921062 P6_BalSwCell34 "电池包6的电芯34均衡状态";
CM_ SG_ 2554921062 P6_BalSwCell35 "电池包6的电芯35均衡状态";
CM_ SG_ 2554921062 P6_BalSwCell36 "电池包6的电芯36均衡状态";
CM_ SG_ 2554986598 P6_CellVoltage37 "电池包6的单体电压37";
CM_ SG_ 2554986598 P6_CellVoltage38 "电池包6的单体电压38";
CM_ SG_ 2554986598 P6_CellVoltage39 "电池包6的单体电压39";
CM_ SG_ 2554986598 P6_CellVoltage40 "电池包6的单体电压40";
CM_ SG_ 2554986598 P6_BalSwCell37 "电池包6的电芯37均衡状态";
CM_ SG_ 2554986598 P6_BalSwCell38 "电池包6的电芯38均衡状态";
CM_ SG_ 2554986598 P6_BalSwCell39 "电池包6的电芯39均衡状态";
CM_ SG_ 2554986598 P6_BalSwCell40 "电池包6的电芯40均衡状态";
CM_ SG_ 2555052134 P6_CellVoltage41 "电池包6的单体电压41";
CM_ SG_ 2555052134 P6_CellVoltage42 "电池包6的单体电压42";
CM_ SG_ 2555052134 P6_CellVoltage43 "电池包6的单体电压43";
CM_ SG_ 2555052134 P6_CellVoltage44 "电池包6的单体电压44";
CM_ SG_ 2555052134 P6_BalSwCell41 "电池包6的电芯41均衡状态";
CM_ SG_ 2555052134 P6_BalSwCell42 "电池包6的电芯42均衡状态";
CM_ SG_ 2555052134 P6_BalSwCell43 "电池包6的电芯43均衡状态";
CM_ SG_ 2555052134 P6_BalSwCell44 "电池包6的电芯44均衡状态";
CM_ SG_ 2555117670 P6_CellVoltage45 "电池包6的单体电压45";
CM_ SG_ 2555117670 P6_CellVoltage46 "电池包6的单体电压46";
CM_ SG_ 2555117670 P6_CellVoltage47 "电池包6的单体电压47";
CM_ SG_ 2555117670 P6_CellVoltage48 "电池包6的单体电压48";
CM_ SG_ 2555117670 P6_BalSwCell45 "电池包6的电芯45均衡状态";
CM_ SG_ 2555117670 P6_BalSwCell46 "电池包6的电芯46均衡状态";
CM_ SG_ 2555117670 P6_BalSwCell47 "电池包6的电芯47均衡状态";
CM_ SG_ 2555117670 P6_BalSwCell48 "电池包6的电芯48均衡状态";
CM_ SG_ 2555183206 P6_CellVoltage49 "电池包6的单体电压49";
CM_ SG_ 2555183206 P6_CellVoltage50 "电池包6的单体电压50";
CM_ SG_ 2555183206 P6_CellVoltage51 "电池包6的单体电压51";
CM_ SG_ 2555183206 P6_CellVoltage52 "电池包6的单体电压52";
CM_ SG_ 2555183206 P6_BalSwCell49 "电池包6的电芯49均衡状态";
CM_ SG_ 2555183206 P6_BalSwCell50 "电池包6的电芯50均衡状态";
CM_ SG_ 2555183206 P6_BalSwCell51 "电池包6的电芯51均衡状态";
CM_ SG_ 2555183206 P6_BalSwCell52 "电池包6的电芯52均衡状态";
CM_ SG_ 2555248742 P6_CellVoltage53 "电池包6的单体电压53";
CM_ SG_ 2555248742 P6_CellVoltage54 "电池包6的单体电压54";
CM_ SG_ 2555248742 P6_CellVoltage55 "电池包6的单体电压55";
CM_ SG_ 2555248742 P6_CellVoltage56 "电池包6的单体电压56";
CM_ SG_ 2555248742 P6_BalSwCell53 "电池包6的电芯53均衡状态";
CM_ SG_ 2555248742 P6_BalSwCell54 "电池包6的电芯54均衡状态";
CM_ SG_ 2555248742 P6_BalSwCell55 "电池包6的电芯55均衡状态";
CM_ SG_ 2555248742 P6_BalSwCell56 "电池包6的电芯56均衡状态";
CM_ SG_ 2555314278 P6_CellVoltage57 "电池包6的单体电压57";
CM_ SG_ 2555314278 P6_CellVoltage58 "电池包6的单体电压58";
CM_ SG_ 2555314278 P6_CellVoltage59 "电池包6的单体电压59";
CM_ SG_ 2555314278 P6_CellVoltage60 "电池包6的单体电压60";
CM_ SG_ 2555314278 P6_BalSwCell57 "电池包6的电芯57均衡状态";
CM_ SG_ 2555314278 P6_BalSwCell58 "电池包6的电芯58均衡状态";
CM_ SG_ 2555314278 P6_BalSwCell59 "电池包6的电芯59均衡状态";
CM_ SG_ 2555314278 P6_BalSwCell60 "电池包6的电芯60均衡状态";
CM_ SG_ 2555379814 P6_CellVoltage61 "电池包6的单体电压61";
CM_ SG_ 2555379814 P6_CellVoltage62 "电池包6的单体电压62";
CM_ SG_ 2555379814 P6_CellVoltage63 "电池包6的单体电压63";
CM_ SG_ 2555379814 P6_CellVoltage64 "电池包6的单体电压64";
CM_ SG_ 2555379814 P6_BalSwCell61 "电池包6的电芯61均衡状态";
CM_ SG_ 2555379814 P6_BalSwCell62 "电池包6的电芯62均衡状态";
CM_ SG_ 2555379814 P6_BalSwCell63 "电池包6的电芯63均衡状态";
CM_ SG_ 2555379814 P6_BalSwCell64 "电池包6的电芯64均衡状态";
CM_ SG_ 2555445350 P6_CellVoltage65 "电池包6的单体电压65";
CM_ SG_ 2555445350 P6_CellVoltage66 "电池包6的单体电压66";
CM_ SG_ 2555445350 P6_CellVoltage67 "电池包6的单体电压67";
CM_ SG_ 2555445350 P6_CellVoltage68 "电池包6的单体电压68";
CM_ SG_ 2555445350 P6_BalSwCell65 "电池包6的电芯65均衡状态";
CM_ SG_ 2555445350 P6_BalSwCell66 "电池包6的电芯66均衡状态";
CM_ SG_ 2555445350 P6_BalSwCell67 "电池包6的电芯67均衡状态";
CM_ SG_ 2555445350 P6_BalSwCell68 "电池包6的电芯68均衡状态";
CM_ SG_ 2555510886 P6_CellVoltage69 "电池包6的单体电压69";
CM_ SG_ 2555510886 P6_CellVoltage70 "电池包6的单体电压70";
CM_ SG_ 2555510886 P6_CellVoltage71 "电池包6的单体电压71";
CM_ SG_ 2555510886 P6_CellVoltage72 "电池包6的单体电压72";
CM_ SG_ 2555510886 P6_BalSwCell69 "电池包6的电芯69均衡状态";
CM_ SG_ 2555510886 P6_BalSwCell70 "电池包6的电芯70均衡状态";
CM_ SG_ 2555510886 P6_BalSwCell71 "电池包6的电芯71均衡状态";
CM_ SG_ 2555510886 P6_BalSwCell72 "电池包6的电芯72均衡状态";
CM_ SG_ 2555576422 P6_CellVoltage73 "电池包6的单体电压73";
CM_ SG_ 2555576422 P6_CellVoltage74 "电池包6的单体电压74";
CM_ SG_ 2555576422 P6_CellVoltage75 "电池包6的单体电压75";
CM_ SG_ 2555576422 P6_CellVoltage76 "电池包6的单体电压76";
CM_ SG_ 2555576422 P6_BalSwCell73 "电池包6的电芯73均衡状态";
CM_ SG_ 2555576422 P6_BalSwCell74 "电池包6的电芯74均衡状态";
CM_ SG_ 2555576422 P6_BalSwCell75 "电池包6的电芯75均衡状态";
CM_ SG_ 2555576422 P6_BalSwCell76 "电池包6的电芯76均衡状态";
CM_ SG_ 2555641958 P6_CellVoltage77 "电池包6的单体电压77";
CM_ SG_ 2555641958 P6_CellVoltage78 "电池包6的单体电压78";
CM_ SG_ 2555641958 P6_CellVoltage79 "电池包6的单体电压79";
CM_ SG_ 2555641958 P6_CellVoltage80 "电池包6的单体电压80";
CM_ SG_ 2555641958 P6_BalSwCell77 "电池包6的电芯77均衡状态";
CM_ SG_ 2555641958 P6_BalSwCell78 "电池包6的电芯78均衡状态";
CM_ SG_ 2555641958 P6_BalSwCell79 "电池包6的电芯79均衡状态";
CM_ SG_ 2555641958 P6_BalSwCell80 "电池包6的电芯80均衡状态";
CM_ SG_ 2555707494 P6_CellVoltage81 "电池包6的单体电压81";
CM_ SG_ 2555707494 P6_CellVoltage82 "电池包6的单体电压82";
CM_ SG_ 2555707494 P6_CellVoltage83 "电池包6的单体电压83";
CM_ SG_ 2555707494 P6_CellVoltage84 "电池包6的单体电压84";
CM_ SG_ 2555707494 P6_BalSwCell81 "电池包6的电芯81均衡状态";
CM_ SG_ 2555707494 P6_BalSwCell82 "电池包6的电芯82均衡状态";
CM_ SG_ 2555707494 P6_BalSwCell83 "电池包6的电芯83均衡状态";
CM_ SG_ 2555707494 P6_BalSwCell84 "电池包6的电芯84均衡状态";
CM_ SG_ 2555773030 P6_CellVoltage85 "电池包6的单体电压85";
CM_ SG_ 2555773030 P6_CellVoltage86 "电池包6的单体电压86";
CM_ SG_ 2555773030 P6_CellVoltage87 "电池包6的单体电压87";
CM_ SG_ 2555773030 P6_CellVoltage88 "电池包6的单体电压88";
CM_ SG_ 2555773030 P6_BalSwCell85 "电池包6的电芯85均衡状态";
CM_ SG_ 2555773030 P6_BalSwCell86 "电池包6的电芯86均衡状态";
CM_ SG_ 2555773030 P6_BalSwCell87 "电池包6的电芯87均衡状态";
CM_ SG_ 2555773030 P6_BalSwCell88 "电池包6的电芯88均衡状态";
CM_ SG_ 2555838566 P6_CellVoltage89 "电池包6的单体电压89";
CM_ SG_ 2555838566 P6_CellVoltage90 "电池包6的单体电压90";
CM_ SG_ 2555838566 P6_CellVoltage91 "电池包6的单体电压91";
CM_ SG_ 2555838566 P6_CellVoltage92 "电池包6的单体电压92";
CM_ SG_ 2555838566 P6_BalSwCell89 "电池包6的电芯89均衡状态";
CM_ SG_ 2555838566 P6_BalSwCell90 "电池包6的电芯90均衡状态";
CM_ SG_ 2555838566 P6_BalSwCell91 "电池包6的电芯91均衡状态";
CM_ SG_ 2555838566 P6_BalSwCell92 "电池包6的电芯92均衡状态";
CM_ SG_ 2555904102 P6_CellVoltage93 "电池包6的单体电压93";
CM_ SG_ 2555904102 P6_CellVoltage94 "电池包6的单体电压94";
CM_ SG_ 2555904102 P6_CellVoltage95 "电池包6的单体电压95";
CM_ SG_ 2555904102 P6_CellVoltage96 "电池包6的单体电压96";
CM_ SG_ 2555904102 P6_BalSwCell93 "电池包6的电芯93均衡状态";
CM_ SG_ 2555904102 P6_BalSwCell94 "电池包6的电芯94均衡状态";
CM_ SG_ 2555904102 P6_BalSwCell95 "电池包6的电芯95均衡状态";
CM_ SG_ 2555904102 P6_BalSwCell96 "电池包6的电芯96均衡状态";
CM_ SG_ 2555969638 P6_CellVoltage97 "电池包6的单体电压97";
CM_ SG_ 2555969638 P6_CellVoltage98 "电池包6的单体电压98";
CM_ SG_ 2555969638 P6_CellVoltage99 "电池包6的单体电压99";
CM_ SG_ 2555969638 P6_CellVoltage100 "电池包6的单体电压100";
CM_ SG_ 2555969638 P6_BalSwCell97 "电池包6的电芯97均衡状态";
CM_ SG_ 2555969638 P6_BalSwCell98 "电池包6的电芯98均衡状态";
CM_ SG_ 2555969638 P6_BalSwCell99 "电池包6的电芯99均衡状态";
CM_ SG_ 2555969638 P6_BalSwCell100 "电池包6的电芯100均衡状态";
CM_ SG_ 2556035174 P6_CellVoltage101 "电池包6的单体电压101";
CM_ SG_ 2556035174 P6_CellVoltage102 "电池包6的单体电压102";
CM_ SG_ 2556035174 P6_CellVoltage103 "电池包6的单体电压103";
CM_ SG_ 2556035174 P6_CellVoltage104 "电池包6的单体电压104";
CM_ SG_ 2556035174 P6_BalSwCell101 "电池包6的电芯101均衡状态";
CM_ SG_ 2556035174 P6_BalSwCell102 "电池包6的电芯102均衡状态";
CM_ SG_ 2556035174 P6_BalSwCell103 "电池包6的电芯103均衡状态";
CM_ SG_ 2556035174 P6_BalSwCell104 "电池包6的电芯104均衡状态";
CM_ SG_ 2556100710 P6_CellVoltage105 "电池包6的单体电压105";
CM_ SG_ 2556100710 P6_CellVoltage106 "电池包6的单体电压106";
CM_ SG_ 2556100710 P6_CellVoltage107 "电池包6的单体电压107";
CM_ SG_ 2556100710 P6_CellVoltage108 "电池包6的单体电压108";
CM_ SG_ 2556100710 P6_BalSwCell105 "电池包6的电芯105均衡状态";
CM_ SG_ 2556100710 P6_BalSwCell106 "电池包6的电芯106均衡状态";
CM_ SG_ 2556100710 P6_BalSwCell107 "电池包6的电芯107均衡状态";
CM_ SG_ 2556100710 P6_BalSwCell108 "电池包6的电芯108均衡状态";
CM_ SG_ 2556166246 P6_CellVoltage109 "电池包6的单体电压109";
CM_ SG_ 2556166246 P6_CellVoltage110 "电池包6的单体电压110";
CM_ SG_ 2556166246 P6_CellVoltage111 "电池包6的单体电压111";
CM_ SG_ 2556166246 P6_CellVoltage112 "电池包6的单体电压112";
CM_ SG_ 2556166246 P6_BalSwCell109 "电池包6的电芯109均衡状态";
CM_ SG_ 2556166246 P6_BalSwCell110 "电池包6的电芯110均衡状态";
CM_ SG_ 2556166246 P6_BalSwCell111 "电池包6的电芯111均衡状态";
CM_ SG_ 2556166246 P6_BalSwCell112 "电池包6的电芯112均衡状态";
CM_ SG_ 2556231782 P6_CellVoltage113 "电池包6的单体电压113";
CM_ SG_ 2556231782 P6_CellVoltage114 "电池包6的单体电压114";
CM_ SG_ 2556231782 P6_CellVoltage115 "电池包6的单体电压115";
CM_ SG_ 2556231782 P6_CellVoltage116 "电池包6的单体电压116";
CM_ SG_ 2556231782 P6_BalSwCell113 "电池包6的电芯113均衡状态";
CM_ SG_ 2556231782 P6_BalSwCell114 "电池包6的电芯114均衡状态";
CM_ SG_ 2556231782 P6_BalSwCell115 "电池包6的电芯115均衡状态";
CM_ SG_ 2556231782 P6_BalSwCell116 "电池包6的电芯116均衡状态";
CM_ SG_ 2556297318 P6_CellVoltage117 "电池包6的单体电压117";
CM_ SG_ 2556297318 P6_CellVoltage118 "电池包6的单体电压118";
CM_ SG_ 2556297318 P6_CellVoltage119 "电池包6的单体电压119";
CM_ SG_ 2556297318 P6_CellVoltage120 "电池包6的单体电压120";
CM_ SG_ 2556297318 P6_BalSwCell117 "电池包6的电芯117均衡状态";
CM_ SG_ 2556297318 P6_BalSwCell118 "电池包6的电芯118均衡状态";
CM_ SG_ 2556297318 P6_BalSwCell119 "电池包6的电芯119均衡状态";
CM_ SG_ 2556297318 P6_BalSwCell120 "电池包6的电芯120均衡状态";
CM_ SG_ 2556362854 P6_CellVoltage121 "电池包6的单体电压121";
CM_ SG_ 2556362854 P6_CellVoltage122 "电池包6的单体电压122";
CM_ SG_ 2556362854 P6_CellVoltage123 "电池包6的单体电压123";
CM_ SG_ 2556362854 P6_CellVoltage124 "电池包6的单体电压124";
CM_ SG_ 2556362854 P6_BalSwCell121 "电池包6的电芯121均衡状态";
CM_ SG_ 2556362854 P6_BalSwCell122 "电池包6的电芯122均衡状态";
CM_ SG_ 2556362854 P6_BalSwCell123 "电池包6的电芯123均衡状态";
CM_ SG_ 2556362854 P6_BalSwCell124 "电池包6的电芯124均衡状态";
CM_ SG_ 2556428390 P6_CellVoltage125 "电池包6的单体电压125";
CM_ SG_ 2556428390 P6_CellVoltage126 "电池包6的单体电压126";
CM_ SG_ 2556428390 P6_CellVoltage127 "电池包6的单体电压127";
CM_ SG_ 2556428390 P6_CellVoltage128 "电池包6的单体电压128";
CM_ SG_ 2556428390 P6_BalSwCell125 "电池包6的电芯125均衡状态";
CM_ SG_ 2556428390 P6_BalSwCell126 "电池包6的电芯126均衡状态";
CM_ SG_ 2556428390 P6_BalSwCell127 "电池包6的电芯127均衡状态";
CM_ SG_ 2556428390 P6_BalSwCell128 "电池包6的电芯128均衡状态";
CM_ SG_ 2556493926 P6_CellVoltage129 "电池包6的单体电压129";
CM_ SG_ 2556493926 P6_CellVoltage130 "电池包6的单体电压130";
CM_ SG_ 2556493926 P6_CellVoltage131 "电池包6的单体电压131";
CM_ SG_ 2556493926 P6_CellVoltage132 "电池包6的单体电压132";
CM_ SG_ 2556493926 P6_BalSwCell129 "电池包6的电芯129均衡状态";
CM_ SG_ 2556493926 P6_BalSwCell130 "电池包6的电芯130均衡状态";
CM_ SG_ 2556493926 P6_BalSwCell131 "电池包6的电芯131均衡状态";
CM_ SG_ 2556493926 P6_BalSwCell132 "电池包6的电芯132均衡状态";
CM_ SG_ 2556559462 P6_CellVoltage133 "电池包6的单体电压133";
CM_ SG_ 2556559462 P6_CellVoltage134 "电池包6的单体电压134";
CM_ SG_ 2556559462 P6_CellVoltage135 "电池包6的单体电压135";
CM_ SG_ 2556559462 P6_CellVoltage136 "电池包6的单体电压136";
CM_ SG_ 2556559462 P6_BalSwCell133 "电池包6的电芯133均衡状态";
CM_ SG_ 2556559462 P6_BalSwCell134 "电池包6的电芯134均衡状态";
CM_ SG_ 2556559462 P6_BalSwCell135 "电池包6的电芯135均衡状态";
CM_ SG_ 2556559462 P6_BalSwCell136 "电池包6的电芯136均衡状态";
CM_ SG_ 2556624998 P6_CellVoltage137 "电池包6的单体电压137";
CM_ SG_ 2556624998 P6_CellVoltage138 "电池包6的单体电压138";
CM_ SG_ 2556624998 P6_CellVoltage139 "电池包6的单体电压139";
CM_ SG_ 2556624998 P6_CellVoltage140 "电池包6的单体电压140";
CM_ SG_ 2556624998 P6_BalSwCell137 "电池包6的电芯137均衡状态";
CM_ SG_ 2556624998 P6_BalSwCell138 "电池包6的电芯138均衡状态";
CM_ SG_ 2556624998 P6_BalSwCell139 "电池包6的电芯139均衡状态";
CM_ SG_ 2556624998 P6_BalSwCell140 "电池包6的电芯140均衡状态";
CM_ SG_ 2556690534 P6_CellVoltage141 "电池包6的单体电压141";
CM_ SG_ 2556690534 P6_CellVoltage142 "电池包6的单体电压142";
CM_ SG_ 2556690534 P6_CellVoltage143 "电池包6的单体电压143";
CM_ SG_ 2556690534 P6_CellVoltage144 "电池包6的单体电压144";
CM_ SG_ 2556690534 P6_BalSwCell141 "电池包6的电芯141均衡状态";
CM_ SG_ 2556690534 P6_BalSwCell142 "电池包6的电芯142均衡状态";
CM_ SG_ 2556690534 P6_BalSwCell143 "电池包6的电芯143均衡状态";
CM_ SG_ 2556690534 P6_BalSwCell144 "电池包6的电芯144均衡状态";
CM_ SG_ 2556756070 P6_CellVoltage145 "电池包6的单体电压145";
CM_ SG_ 2556756070 P6_CellVoltage146 "电池包6的单体电压146";
CM_ SG_ 2556756070 P6_CellVoltage147 "电池包6的单体电压147";
CM_ SG_ 2556756070 P6_CellVoltage148 "电池包6的单体电压148";
CM_ SG_ 2556756070 P6_BalSwCell145 "电池包6的电芯145均衡状态";
CM_ SG_ 2556756070 P6_BalSwCell146 "电池包6的电芯146均衡状态";
CM_ SG_ 2556756070 P6_BalSwCell147 "电池包6的电芯147均衡状态";
CM_ SG_ 2556756070 P6_BalSwCell148 "电池包6的电芯148均衡状态";
CM_ SG_ 2556821606 P6_CellVoltage149 "电池包6的单体电压149";
CM_ SG_ 2556821606 P6_CellVoltage150 "电池包6的单体电压150";
CM_ SG_ 2556821606 P6_CellVoltage151 "电池包6的单体电压151";
CM_ SG_ 2556821606 P6_CellVoltage152 "电池包6的单体电压152";
CM_ SG_ 2556821606 P6_BalSwCell149 "电池包6的电芯149均衡状态";
CM_ SG_ 2556821606 P6_BalSwCell150 "电池包6的电芯150均衡状态";
CM_ SG_ 2556821606 P6_BalSwCell151 "电池包6的电芯151均衡状态";
CM_ SG_ 2556821606 P6_BalSwCell152 "电池包6的电芯152均衡状态";
CM_ SG_ 2556887142 P6_CellVoltage153 "电池包6的单体电压153";
CM_ SG_ 2556887142 P6_CellVoltage154 "电池包6的单体电压154";
CM_ SG_ 2556887142 P6_CellVoltage155 "电池包6的单体电压155";
CM_ SG_ 2556887142 P6_CellVoltage156 "电池包6的单体电压156";
CM_ SG_ 2556887142 P6_BalSwCell153 "电池包6的电芯153均衡状态";
CM_ SG_ 2556887142 P6_BalSwCell154 "电池包6的电芯154均衡状态";
CM_ SG_ 2556887142 P6_BalSwCell155 "电池包6的电芯155均衡状态";
CM_ SG_ 2556887142 P6_BalSwCell156 "电池包6的电芯156均衡状态";
CM_ SG_ 2556952678 P6_CellVoltage157 "电池包6的单体电压157";
CM_ SG_ 2556952678 P6_CellVoltage158 "电池包6的单体电压158";
CM_ SG_ 2556952678 P6_CellVoltage159 "电池包6的单体电压159";
CM_ SG_ 2556952678 P6_CellVoltage160 "电池包6的单体电压160";
CM_ SG_ 2556952678 P6_BalSwCell157 "电池包6的电芯157均衡状态";
CM_ SG_ 2556952678 P6_BalSwCell158 "电池包6的电芯158均衡状态";
CM_ SG_ 2556952678 P6_BalSwCell159 "电池包6的电芯159均衡状态";
CM_ SG_ 2556952678 P6_BalSwCell160 "电池包6的电芯160均衡状态";
CM_ SG_ 2557018214 P6_CellVoltage161 "电池包6的单体电压161";
CM_ SG_ 2557018214 P6_CellVoltage162 "电池包6的单体电压162";
CM_ SG_ 2557018214 P6_CellVoltage163 "电池包6的单体电压163";
CM_ SG_ 2557018214 P6_CellVoltage164 "电池包6的单体电压164";
CM_ SG_ 2557018214 P6_BalSwCell161 "电池包6的电芯161均衡状态";
CM_ SG_ 2557018214 P6_BalSwCell162 "电池包6的电芯162均衡状态";
CM_ SG_ 2557018214 P6_BalSwCell163 "电池包6的电芯163均衡状态";
CM_ SG_ 2557018214 P6_BalSwCell164 "电池包6的电芯164均衡状态";
CM_ SG_ 2557083750 P6_CellVoltage165 "电池包6的单体电压165";
CM_ SG_ 2557083750 P6_CellVoltage166 "电池包6的单体电压166";
CM_ SG_ 2557083750 P6_CellVoltage167 "电池包6的单体电压167";
CM_ SG_ 2557083750 P6_CellVoltage168 "电池包6的单体电压168";
CM_ SG_ 2557083750 P6_BalSwCell165 "电池包6的电芯165均衡状态";
CM_ SG_ 2557083750 P6_BalSwCell166 "电池包6的电芯166均衡状态";
CM_ SG_ 2557083750 P6_BalSwCell167 "电池包6的电芯167均衡状态";
CM_ SG_ 2557083750 P6_BalSwCell168 "电池包6的电芯168均衡状态";
CM_ SG_ 2557149286 P6_CellVoltage169 "电池包6的单体电压169";
CM_ SG_ 2557149286 P6_CellVoltage170 "电池包6的单体电压170";
CM_ SG_ 2557149286 P6_CellVoltage171 "电池包6的单体电压171";
CM_ SG_ 2557149286 P6_CellVoltage172 "电池包6的单体电压172";
CM_ SG_ 2557149286 P6_BalSwCell169 "电池包6的电芯169均衡状态";
CM_ SG_ 2557149286 P6_BalSwCell170 "电池包6的电芯170均衡状态";
CM_ SG_ 2557149286 P6_BalSwCell171 "电池包6的电芯171均衡状态";
CM_ SG_ 2557149286 P6_BalSwCell172 "电池包6的电芯172均衡状态";
CM_ SG_ 2557214822 P6_CellVoltage173 "电池包6的单体电压173";
CM_ SG_ 2557214822 P6_CellVoltage174 "电池包6的单体电压174";
CM_ SG_ 2557214822 P6_CellVoltage175 "电池包6的单体电压175";
CM_ SG_ 2557214822 P6_CellVoltage176 "电池包6的单体电压176";
CM_ SG_ 2557214822 P6_BalSwCell173 "电池包6的电芯173均衡状态";
CM_ SG_ 2557214822 P6_BalSwCell174 "电池包6的电芯174均衡状态";
CM_ SG_ 2557214822 P6_BalSwCell175 "电池包6的电芯175均衡状态";
CM_ SG_ 2557214822 P6_BalSwCell176 "电池包6的电芯176均衡状态";
CM_ SG_ 2557280358 P6_CellVoltage177 "电池包6的单体电压177";
CM_ SG_ 2557280358 P6_CellVoltage178 "电池包6的单体电压178";
CM_ SG_ 2557280358 P6_CellVoltage179 "电池包6的单体电压179";
CM_ SG_ 2557280358 P6_CellVoltage180 "电池包6的单体电压180";
CM_ SG_ 2557280358 P6_BalSwCell177 "电池包6的电芯177均衡状态";
CM_ SG_ 2557280358 P6_BalSwCell178 "电池包6的电芯178均衡状态";
CM_ SG_ 2557280358 P6_BalSwCell179 "电池包6的电芯179均衡状态";
CM_ SG_ 2557280358 P6_BalSwCell180 "电池包6的电芯180均衡状态";
CM_ SG_ 2557345894 P6_CellVoltage181 "电池包6的单体电压181";
CM_ SG_ 2557345894 P6_CellVoltage182 "电池包6的单体电压182";
CM_ SG_ 2557345894 P6_CellVoltage183 "电池包6的单体电压183";
CM_ SG_ 2557345894 P6_CellVoltage184 "电池包6的单体电压184";
CM_ SG_ 2557345894 P6_BalSwCell181 "电池包6的电芯181均衡状态";
CM_ SG_ 2557345894 P6_BalSwCell182 "电池包6的电芯182均衡状态";
CM_ SG_ 2557345894 P6_BalSwCell183 "电池包6的电芯183均衡状态";
CM_ SG_ 2557345894 P6_BalSwCell184 "电池包6的电芯184均衡状态";
CM_ SG_ 2557411430 P6_CellVoltage185 "电池包6的单体电压185";
CM_ SG_ 2557411430 P6_CellVoltage186 "电池包6的单体电压186";
CM_ SG_ 2557411430 P6_CellVoltage187 "电池包6的单体电压187";
CM_ SG_ 2557411430 P6_CellVoltage188 "电池包6的单体电压188";
CM_ SG_ 2557411430 P6_BalSwCell185 "电池包6的电芯185均衡状态";
CM_ SG_ 2557411430 P6_BalSwCell186 "电池包6的电芯186均衡状态";
CM_ SG_ 2557411430 P6_BalSwCell187 "电池包6的电芯187均衡状态";
CM_ SG_ 2557411430 P6_BalSwCell188 "电池包6的电芯188均衡状态";
CM_ SG_ 2557476966 P6_CellVoltage189 "电池包6的单体电压189";
CM_ SG_ 2557476966 P6_CellVoltage190 "电池包6的单体电压190";
CM_ SG_ 2557476966 P6_CellVoltage191 "电池包6的单体电压191";
CM_ SG_ 2557476966 P6_CellVoltage192 "电池包6的单体电压192";
CM_ SG_ 2557476966 P6_BalSwCell189 "电池包6的电芯189均衡状态";
CM_ SG_ 2557476966 P6_BalSwCell190 "电池包6的电芯190均衡状态";
CM_ SG_ 2557476966 P6_BalSwCell191 "电池包6的电芯191均衡状态";
CM_ SG_ 2557476966 P6_BalSwCell192 "电池包6的电芯192均衡状态";
CM_ SG_ 2558525542 P6_CellTemp1 "电池包6的单体温度1";
CM_ SG_ 2558525542 P6_CellTemp2 "电池包6的单体温度2";
CM_ SG_ 2558525542 P6_CellTemp3 "电池包6的单体温度3";
CM_ SG_ 2558525542 P6_CellTemp4 "电池包6的单体温度4";
CM_ SG_ 2558525542 P6_CellTemp5 "电池包6的单体温度5";
CM_ SG_ 2558591078 P6_CellTemp6 "电池包6的单体温度6";
CM_ SG_ 2558591078 P6_CellTemp7 "电池包6的单体温度7";
CM_ SG_ 2558591078 P6_CellTemp8 "电池包6的单体温度8";
CM_ SG_ 2558591078 P6_CellTemp9 "电池包6的单体温度9";
CM_ SG_ 2558591078 P6_CellTemp10 "电池包6的单体温度10";
CM_ SG_ 2558656614 P6_CellTemp11 "电池包6的单体温度11";
CM_ SG_ 2558656614 P6_CellTemp12 "电池包6的单体温度12";
CM_ SG_ 2558656614 P6_CellTemp13 "电池包6的单体温度13";
CM_ SG_ 2558656614 P6_CellTemp14 "电池包6的单体温度14";
CM_ SG_ 2558656614 P6_CellTemp15 "电池包6的单体温度15";
CM_ SG_ 2558722150 P6_CellTemp16 "电池包6的单体温度16";
CM_ SG_ 2558722150 P6_CellTemp17 "电池包6的单体温度17";
CM_ SG_ 2558722150 P6_CellTemp18 "电池包6的单体温度18";
CM_ SG_ 2558722150 P6_CellTemp19 "电池包6的单体温度19";
CM_ SG_ 2558722150 P6_CellTemp20 "电池包6的单体温度20";
CM_ SG_ 2558787686 P6_CellTemp21 "电池包6的单体温度21";
CM_ SG_ 2558787686 P6_CellTemp22 "电池包6的单体温度22";
CM_ SG_ 2558787686 P6_CellTemp23 "电池包6的单体温度23";
CM_ SG_ 2558787686 P6_CellTemp24 "电池包6的单体温度24";
CM_ SG_ 2558787686 P6_CellTemp25 "电池包6的单体温度25";
CM_ SG_ 2558853222 P6_CellTemp26 "电池包6的单体温度26";
CM_ SG_ 2558853222 P6_CellTemp27 "电池包6的单体温度27";
CM_ SG_ 2558853222 P6_CellTemp28 "电池包6的单体温度28";
CM_ SG_ 2558853222 P6_CellTemp29 "电池包6的单体温度29";
CM_ SG_ 2558853222 P6_CellTemp30 "电池包6的单体温度30";
CM_ SG_ 2558918758 P6_CellTemp31 "电池包6的单体温度31";
CM_ SG_ 2558918758 P6_CellTemp32 "电池包6的单体温度32";
CM_ SG_ 2558918758 P6_CellTemp33 "电池包6的单体温度33";
CM_ SG_ 2558918758 P6_CellTemp34 "电池包6的单体温度34";
CM_ SG_ 2558918758 P6_CellTemp35 "电池包6的单体温度35";
CM_ SG_ 2558984294 P6_CellTemp36 "电池包6的单体温度36";
CM_ SG_ 2558984294 P6_CellTemp37 "电池包6的单体温度37";
CM_ SG_ 2558984294 P6_CellTemp38 "电池包6的单体温度38";
CM_ SG_ 2558984294 P6_CellTemp39 "电池包6的单体温度39";
CM_ SG_ 2558984294 P6_CellTemp40 "电池包6的单体温度40";
CM_ SG_ 2559049830 P6_CellTemp41 "电池包6的单体温度41";
CM_ SG_ 2559049830 P6_CellTemp42 "电池包6的单体温度42";
CM_ SG_ 2559049830 P6_CellTemp43 "电池包6的单体温度43";
CM_ SG_ 2559049830 P6_CellTemp44 "电池包6的单体温度44";
CM_ SG_ 2559049830 P6_CellTemp45 "电池包6的单体温度45";
CM_ SG_ 2559115366 P6_CellTemp46 "电池包6的单体温度46";
CM_ SG_ 2559115366 P6_CellTemp47 "电池包6的单体温度47";
CM_ SG_ 2559115366 P6_CellTemp48 "电池包6的单体温度48";
CM_ SG_ 2559115366 P6_CellTemp49 "电池包6的单体温度49";
CM_ SG_ 2559115366 P6_CellTemp50 "电池包6的单体温度50";
CM_ SG_ 2559180902 P6_CellTemp51 "电池包6的单体温度51";
CM_ SG_ 2559180902 P6_CellTemp52 "电池包6的单体温度52";
CM_ SG_ 2559180902 P6_CellTemp53 "电池包6的单体温度53";
CM_ SG_ 2559180902 P6_CellTemp54 "电池包6的单体温度54";
CM_ SG_ 2559180902 P6_CellTemp55 "电池包6的单体温度55";
CM_ SG_ 2559246438 P6_CellTemp56 "电池包6的单体温度56";
CM_ SG_ 2559246438 P6_CellTemp57 "电池包6的单体温度57";
CM_ SG_ 2559246438 P6_CellTemp58 "电池包6的单体温度58";
CM_ SG_ 2559246438 P6_CellTemp59 "电池包6的单体温度59";
CM_ SG_ 2559246438 P6_CellTemp60 "电池包6的单体温度60";
CM_ SG_ 2559311974 P6_CellTemp61 "电池包6的单体温度61";
CM_ SG_ 2559311974 P6_CellTemp62 "电池包6的单体温度62";
CM_ SG_ 2559311974 P6_CellTemp63 "电池包6的单体温度63";
CM_ SG_ 2559311974 P6_CellTemp64 "电池包6的单体温度64";
CM_ SG_ 2559311974 P6_CellTemp65 "电池包6的单体温度65";
CM_ SG_ 2559377510 P6_CellTemp66 "电池包6的单体温度66";
CM_ SG_ 2559377510 P6_CellTemp67 "电池包6的单体温度67";
CM_ SG_ 2559377510 P6_CellTemp68 "电池包6的单体温度68";
CM_ SG_ 2559377510 P6_CellTemp69 "电池包6的单体温度69";
CM_ SG_ 2559377510 P6_CellTemp70 "电池包6的单体温度70";
CM_ SG_ 2559443046 P6_CellTemp71 "电池包6的单体温度71";
CM_ SG_ 2559443046 P6_CellTemp72 "电池包6的单体温度72";
CM_ SG_ 2559443046 P6_CellTemp73 "电池包6的单体温度73";
CM_ SG_ 2559443046 P6_CellTemp74 "电池包6的单体温度74";
CM_ SG_ 2559443046 P6_CellTemp75 "电池包6的单体温度75";
CM_ SG_ 2559508582 P6_CellTemp76 "电池包6的单体温度76";
CM_ SG_ 2559508582 P6_CellTemp77 "电池包6的单体温度77";
CM_ SG_ 2559508582 P6_CellTemp78 "电池包6的单体温度78";
CM_ SG_ 2559508582 P6_CellTemp79 "电池包6的单体温度79";
CM_ SG_ 2559508582 P6_CellTemp80 "电池包6的单体温度80";
CM_ SG_ 2559574118 P6_CellTemp81 "电池包6的单体温度81";
CM_ SG_ 2559574118 P6_CellTemp82 "电池包6的单体温度82";
CM_ SG_ 2559574118 P6_CellTemp83 "电池包6的单体温度83";
CM_ SG_ 2559574118 P6_CellTemp84 "电池包6的单体温度84";
CM_ SG_ 2559574118 P6_CellTemp85 "电池包6的单体温度85";
CM_ SG_ 2559639654 P6_CellTemp86 "电池包6的单体温度86";
CM_ SG_ 2559639654 P6_CellTemp87 "电池包6的单体温度87";
CM_ SG_ 2559639654 P6_CellTemp88 "电池包6的单体温度88";
CM_ SG_ 2559639654 P6_CellTemp89 "电池包6的单体温度89";
CM_ SG_ 2559639654 P6_CellTemp90 "电池包6的单体温度90";
CM_ SG_ 2559705190 P6_CellTemp91 "电池包6的单体温度91";
CM_ SG_ 2559705190 P6_CellTemp92 "电池包6的单体温度92";
CM_ SG_ 2559705190 P6_CellTemp93 "电池包6的单体温度93";
CM_ SG_ 2559705190 P6_CellTemp94 "电池包6的单体温度94";
CM_ SG_ 2559705190 P6_CellTemp95 "电池包6的单体温度95";
CM_ SG_ 2559770726 P6_CellTemp96 "电池包6的单体温度96";
CM_ SG_ 2559770726 P6_CellTemp97 "电池包6的单体温度97";
CM_ SG_ 2559770726 P6_CellTemp98 "电池包6的单体温度98";
CM_ SG_ 2559770726 P6_CellTemp99 "电池包6的单体温度99";
CM_ SG_ 2559770726 P6_CellTemp100 "电池包6的单体温度100";
CM_ SG_ 2559836262 P6_CellTemp101 "电池包6的单体温度101";
CM_ SG_ 2559836262 P6_CellTemp102 "电池包6的单体温度102";
CM_ SG_ 2559836262 P6_CellTemp103 "电池包6的单体温度103";
CM_ SG_ 2559836262 P6_CellTemp104 "电池包6的单体温度104";
CM_ SG_ 2559836262 P6_CellTemp105 "电池包6的单体温度105";
CM_ SG_ 2559901798 P6_CellTemp106 "电池包6的单体温度106";
CM_ SG_ 2559901798 P6_CellTemp107 "电池包6的单体温度107";
CM_ SG_ 2559901798 P6_CellTemp108 "电池包6的单体温度108";
CM_ SG_ 2559901798 P6_CellTemp109 "电池包6的单体温度109";
CM_ SG_ 2559901798 P6_CellTemp110 "电池包6的单体温度110";
CM_ SG_ 2559967334 P6_CellTemp111 "电池包6的单体温度111";
CM_ SG_ 2559967334 P6_CellTemp112 "电池包6的单体温度112";
CM_ SG_ 2559967334 P6_CellTemp113 "电池包6的单体温度113";
CM_ SG_ 2559967334 P6_CellTemp114 "电池包6的单体温度114";
CM_ SG_ 2559967334 P6_CellTemp115 "电池包6的单体温度115";
CM_ SG_ 2560032870 P6_CellTemp116 "电池包6的单体温度116";
CM_ SG_ 2560032870 P6_CellTemp117 "电池包6的单体温度117";
CM_ SG_ 2560032870 P6_CellTemp118 "电池包6的单体温度118";
CM_ SG_ 2560032870 P6_CellTemp119 "电池包6的单体温度119";
CM_ SG_ 2560032870 P6_CellTemp120 "电池包6的单体温度120";
CM_ SG_ 2560098406 P6_CellTemp121 "电池包6的单体温度121";
CM_ SG_ 2560098406 P6_CellTemp122 "电池包6的单体温度122";
CM_ SG_ 2560098406 P6_CellTemp123 "电池包6的单体温度123";
CM_ SG_ 2560098406 P6_CellTemp124 "电池包6的单体温度124";
CM_ SG_ 2560098406 P6_CellTemp125 "电池包6的单体温度125";
CM_ SG_ 2560163942 P6_CellTemp126 "电池包6的单体温度126";
CM_ SG_ 2560163942 P6_CellTemp127 "电池包6的单体温度127";
CM_ SG_ 2560163942 P6_CellTemp128 "电池包6的单体温度128";
CM_ SG_ 2560163942 P6_CellTemp129 "电池包6的单体温度129";
CM_ SG_ 2560163942 P6_CellTemp130 "电池包6的单体温度130";
CM_ SG_ 2560229478 P6_CellTemp131 "电池包6的单体温度131";
CM_ SG_ 2560229478 P6_CellTemp132 "电池包6的单体温度132";
CM_ SG_ 2560229478 P6_CellTemp133 "电池包6的单体温度133";
CM_ SG_ 2560229478 P6_CellTemp134 "电池包6的单体温度134";
CM_ SG_ 2560229478 P6_CellTemp135 "电池包6的单体温度135";
CM_ SG_ 2560295014 P6_CellTemp136 "电池包6的单体温度136";
CM_ SG_ 2560295014 P6_CellTemp137 "电池包6的单体温度137";
CM_ SG_ 2560295014 P6_CellTemp138 "电池包6的单体温度138";
CM_ SG_ 2560295014 P6_CellTemp139 "电池包6的单体温度139";
CM_ SG_ 2560295014 P6_CellTemp140 "电池包6的单体温度140";
CM_ SG_ 2560360550 P6_CellTemp141 "电池包6的单体温度141";
CM_ SG_ 2560360550 P6_CellTemp142 "电池包6的单体温度142";
CM_ SG_ 2560360550 P6_CellTemp143 "电池包6的单体温度143";
CM_ SG_ 2560360550 P6_CellTemp144 "电池包6的单体温度144";
CM_ SG_ 2560360550 P6_CellTemp145 "电池包6的单体温度145";
CM_ SG_ 2560426086 P6_CellTemp146 "电池包6的单体温度146";
CM_ SG_ 2560426086 P6_CellTemp147 "电池包6的单体温度147";
CM_ SG_ 2560426086 P6_CellTemp148 "电池包6的单体温度148";
CM_ SG_ 2560426086 P6_CellTemp149 "电池包6的单体温度149";
CM_ SG_ 2560426086 P6_CellTemp150 "电池包6的单体温度150";
CM_ SG_ 2560491622 P6_CellTemp151 "电池包6的单体温度151";
CM_ SG_ 2560491622 P6_CellTemp152 "电池包6的单体温度152";
CM_ SG_ 2560491622 P6_CellTemp153 "电池包6的单体温度153";
CM_ SG_ 2560491622 P6_CellTemp154 "电池包6的单体温度154";
CM_ SG_ 2560491622 P6_CellTemp155 "电池包6的单体温度155";
CM_ SG_ 2560557158 P6_CellTemp156 "电池包6的单体温度156";
CM_ SG_ 2560557158 P6_CellTemp157 "电池包6的单体温度157";
CM_ SG_ 2560557158 P6_CellTemp158 "电池包6的单体温度158";
CM_ SG_ 2560557158 P6_CellTemp159 "电池包6的单体温度159";
CM_ SG_ 2560557158 P6_CellTemp160 "电池包6的单体温度160";
CM_ SG_ 2560622694 P6_CellTemp161 "电池包6的单体温度161";
CM_ SG_ 2560622694 P6_CellTemp162 "电池包6的单体温度162";
CM_ SG_ 2560622694 P6_CellTemp163 "电池包6的单体温度163";
CM_ SG_ 2560622694 P6_CellTemp164 "电池包6的单体温度164";
CM_ SG_ 2560622694 P6_CellTemp165 "电池包6的单体温度165";
CM_ SG_ 2560688230 P6_CellTemp166 "电池包6的单体温度166";
CM_ SG_ 2560688230 P6_CellTemp167 "电池包6的单体温度167";
CM_ SG_ 2560688230 P6_CellTemp168 "电池包6的单体温度168";
CM_ SG_ 2560688230 P6_CellTemp169 "电池包6的单体温度169";
CM_ SG_ 2560688230 P6_CellTemp170 "电池包6的单体温度170";
CM_ SG_ 2560753766 P6_CellTemp171 "电池包6的单体温度171";
CM_ SG_ 2560753766 P6_CellTemp172 "电池包6的单体温度172";
CM_ SG_ 2560753766 P6_CellTemp173 "电池包6的单体温度173";
CM_ SG_ 2560753766 P6_CellTemp174 "电池包6的单体温度174";
CM_ SG_ 2560753766 P6_CellTemp175 "电池包6的单体温度175";
CM_ SG_ 2560819302 P6_CellTemp176 "电池包6的单体温度176";
CM_ SG_ 2560819302 P6_CellTemp177 "电池包6的单体温度177";
CM_ SG_ 2560819302 P6_CellTemp178 "电池包6的单体温度178";
CM_ SG_ 2560819302 P6_CellTemp179 "电池包6的单体温度179";
CM_ SG_ 2560819302 P6_CellTemp180 "电池包6的单体温度180";
CM_ SG_ 2560884838 P6_CellTemp181 "电池包6的单体温度181";
CM_ SG_ 2560884838 P6_CellTemp182 "电池包6的单体温度182";
CM_ SG_ 2560884838 P6_CellTemp183 "电池包6的单体温度183";
CM_ SG_ 2560884838 P6_CellTemp184 "电池包6的单体温度184";
CM_ SG_ 2560884838 P6_CellTemp185 "电池包6的单体温度185";
CM_ SG_ 2560950374 P6_CellTemp186 "电池包6的单体温度186";
CM_ SG_ 2560950374 P6_CellTemp187 "电池包6的单体温度187";
CM_ SG_ 2560950374 P6_CellTemp188 "电池包6的单体温度188";
CM_ SG_ 2560950374 P6_CellTemp189 "电池包6的单体温度189";
CM_ SG_ 2560950374 P6_CellTemp190 "电池包6的单体温度190";
CM_ SG_ 2561015910 P6_CellTemp191 "电池包6的单体温度191";
CM_ SG_ 2561015910 P6_CellTemp192 "电池包6的单体温度192";
CM_ SG_ 2561015910 P6_DatLen16DbgInfo1 "长度为16的调试信息1";
CM_ SG_ 2561015910 P6_DatLen16DbgInfo2 "长度为16的调试信息2";
CM_ SG_ 2561015910 P6_DatLen16DbgInfo3 "长度为16的调试信息3";
CM_ SG_ 2561015910 P6_DatLen16DbgInfo4 "长度为16的调试信息4";
CM_ SG_ 2550399095 P7_BMSPwrSuplVlt1 "电池包7的BMS供电电源电压1";
CM_ SG_ 2550399095 P7_BMSPwrSuplVlt2 "电池包7的BMS供电电源电压2";
CM_ SG_ 2550399095 P7_ChrgStationAuxPwrSuplVlt "电池包7的快充桩A+电压";
CM_ SG_ 2550399095 P7_BMSKL15ON "电池包7的BMS唤醒信号";
CM_ SG_ 2550399095 P7_DCStepState "电池包7的充电状态机";
CM_ SG_ 2550399095 P7_ExtLvWakeup_28VOnly "电池包7的外部唤醒";
CM_ SG_ 2550464631 P7_PackVltUprLmt "电池包7的电压使用上限";
CM_ SG_ 2550464631 P7_PackVltLoLmt "电池包7的电压使用下限";
CM_ SG_ 2550464631 P7_PackMaxDschrgCrnt "电池包7的最大允许放电电流";
CM_ SG_ 2550464631 P7_PackMaxChrgCrnt "电池包7的最大允许充电电流";
CM_ SG_ 2550530167 P7_PackDschrgPwrLmt "电池包7的放电功率限值";
CM_ SG_ 2550530167 P7_PackDschrgPwrStat "电池包7的放电功率状态";
CM_ SG_ 2550530167 P7_PackChrgPwrLmt "电池包7的充电功率限值";
CM_ SG_ 2550530167 P7_PackChrgPwrStat "电池包7的充电功率状态";
BA_DEF_ BO_  "GenMsgSendType" ENUM  "Cyclic","IfActive","Event";
BA_DEF_ BO_  "GenMsgCycleTime" INT 0 5000;
BA_DEF_ BO_  "VFrameFormat" ENUM  "StandardCAN","ExtendedCAN","reserved","reserved","reserved","reserved","reserved","reserved","reserved","reserved","reserved","reserved","reserved","reserved","StandardCAN_FD","ExtendedCAN_FD";
BA_DEF_ SG_  "GenSigSendType" ENUM  "Cyclic","OnWrite","OnChange","NoSigSendType";
BA_DEF_DEF_  "GenMsgSendType" "Cyclic";
BA_DEF_DEF_  "GenMsgCycleTime" 0;
BA_DEF_DEF_  "GenSigSendType" "Cyclic";
BA_DEF_DEF_  "VFrameFormat" "ExtendedCAN";
BA_ "GenMsgCycleTime" BO_ 2550530133 500;
BA_ "GenMsgCycleTime" BO_ 2550595669 500;
BA_ "GenMsgCycleTime" BO_ 2550661205 500;
BA_ "GenMsgCycleTime" BO_ 2550726741 500;
BA_ "GenMsgCycleTime" BO_ 2550792277 500;
BA_ "GenMsgCycleTime" BO_ 2550857813 500;
BA_ "GenMsgCycleTime" BO_ 2550923349 500;
BA_ "GenMsgCycleTime" BO_ 2550988885 1000;
BA_ "GenMsgCycleTime" BO_ 2552299605 1000;
BA_ "GenMsgCycleTime" BO_ 2554396757 1000;
BA_ "GenMsgCycleTime" BO_ 2554462293 1000;
BA_ "GenMsgCycleTime" BO_ 2554527829 1000;
BA_ "GenMsgCycleTime" BO_ 2554593365 1000;
BA_ "GenMsgCycleTime" BO_ 2554658901 1000;
BA_ "GenMsgCycleTime" BO_ 2554724437 1000;
BA_ "GenMsgCycleTime" BO_ 2554789973 1000;
BA_ "GenMsgCycleTime" BO_ 2554855509 1000;
BA_ "GenMsgCycleTime" BO_ 2554921045 1000;
BA_ "GenMsgCycleTime" BO_ 2554986581 1000;
BA_ "GenMsgCycleTime" BO_ 2555052117 1000;
BA_ "GenMsgCycleTime" BO_ 2555117653 1000;
BA_ "GenMsgCycleTime" BO_ 2555183189 1000;
BA_ "GenMsgCycleTime" BO_ 2555248725 1000;
BA_ "GenMsgCycleTime" BO_ 2555314261 1000;
BA_ "GenMsgCycleTime" BO_ 2555379797 1000;
BA_ "GenMsgCycleTime" BO_ 2555445333 1000;
BA_ "GenMsgCycleTime" BO_ 2555510869 1000;
BA_ "GenMsgCycleTime" BO_ 2555576405 1000;
BA_ "GenMsgCycleTime" BO_ 2555641941 1000;
BA_ "GenMsgCycleTime" BO_ 2555707477 1000;
BA_ "GenMsgCycleTime" BO_ 2555773013 1000;
BA_ "GenMsgCycleTime" BO_ 2555838549 1000;
BA_ "GenMsgCycleTime" BO_ 2555904085 1000;
BA_ "GenMsgCycleTime" BO_ 2555969621 1000;
BA_ "GenMsgCycleTime" BO_ 2556035157 1000;
BA_ "GenMsgCycleTime" BO_ 2556100693 1000;
BA_ "GenMsgCycleTime" BO_ 2556166229 1000;
BA_ "GenMsgCycleTime" BO_ 2556231765 1000;
BA_ "GenMsgCycleTime" BO_ 2556297301 1000;
BA_ "GenMsgCycleTime" BO_ 2556362837 1000;
BA_ "GenMsgCycleTime" BO_ 2556428373 1000;
BA_ "GenMsgCycleTime" BO_ 2556493909 1000;
BA_ "GenMsgCycleTime" BO_ 2556559445 1000;
BA_ "GenMsgCycleTime" BO_ 2556624981 1000;
BA_ "GenMsgCycleTime" BO_ 2556690517 1000;
BA_ "GenMsgCycleTime" BO_ 2556756053 1000;
BA_ "GenMsgCycleTime" BO_ 2556821589 1000;
BA_ "GenMsgCycleTime" BO_ 2556887125 1000;
BA_ "GenMsgCycleTime" BO_ 2556952661 1000;
BA_ "GenMsgCycleTime" BO_ 2557018197 1000;
BA_ "GenMsgCycleTime" BO_ 2557083733 1000;
BA_ "GenMsgCycleTime" BO_ 2557149269 1000;
BA_ "GenMsgCycleTime" BO_ 2557214805 1000;
BA_ "GenMsgCycleTime" BO_ 2557280341 1000;
BA_ "GenMsgCycleTime" BO_ 2557345877 1000;
BA_ "GenMsgCycleTime" BO_ 2557411413 1000;
BA_ "GenMsgCycleTime" BO_ 2557476949 1000;
BA_ "GenMsgCycleTime" BO_ 2558525525 1000;
BA_ "GenMsgCycleTime" BO_ 2558591061 1000;
BA_ "GenMsgCycleTime" BO_ 2558656597 1000;
BA_ "GenMsgCycleTime" BO_ 2558722133 1000;
BA_ "GenMsgCycleTime" BO_ 2558787669 1000;
BA_ "GenMsgCycleTime" BO_ 2558853205 1000;
BA_ "GenMsgCycleTime" BO_ 2558918741 1000;
BA_ "GenMsgCycleTime" BO_ 2558984277 1000;
BA_ "GenMsgCycleTime" BO_ 2559049813 1000;
BA_ "GenMsgCycleTime" BO_ 2559115349 1000;
BA_ "GenMsgCycleTime" BO_ 2559180885 1000;
BA_ "GenMsgCycleTime" BO_ 2559246421 1000;
BA_ "GenMsgCycleTime" BO_ 2559311957 1000;
BA_ "GenMsgCycleTime" BO_ 2559377493 1000;
BA_ "GenMsgCycleTime" BO_ 2559443029 1000;
BA_ "GenMsgCycleTime" BO_ 2559508565 1000;
BA_ "GenMsgCycleTime" BO_ 2559574101 1000;
BA_ "GenMsgCycleTime" BO_ 2559639637 1000;
BA_ "GenMsgCycleTime" BO_ 2559705173 1000;
BA_ "GenMsgCycleTime" BO_ 2559770709 1000;
BA_ "GenMsgCycleTime" BO_ 2559836245 1000;
BA_ "GenMsgCycleTime" BO_ 2559901781 1000;
BA_ "GenMsgCycleTime" BO_ 2559967317 1000;
BA_ "GenMsgCycleTime" BO_ 2560032853 1000;
BA_ "GenMsgCycleTime" BO_ 2560098389 1000;
BA_ "GenMsgCycleTime" BO_ 2560163925 1000;
BA_ "GenMsgCycleTime" BO_ 2560229461 1000;
BA_ "GenMsgCycleTime" BO_ 2560294997 1000;
BA_ "GenMsgCycleTime" BO_ 2560360533 1000;
BA_ "GenMsgCycleTime" BO_ 2560426069 1000;
BA_ "GenMsgCycleTime" BO_ 2560491605 1000;
BA_ "GenMsgCycleTime" BO_ 2560557141 1000;
BA_ "GenMsgCycleTime" BO_ 2560622677 1000;
BA_ "GenMsgCycleTime" BO_ 2560688213 1000;
BA_ "GenMsgCycleTime" BO_ 2560753749 1000;
BA_ "GenMsgCycleTime" BO_ 2560819285 1000;
BA_ "GenMsgCycleTime" BO_ 2560884821 1000;
BA_ "GenMsgCycleTime" BO_ 2560950357 1000;
BA_ "GenMsgCycleTime" BO_ 2561015893 1000;
BA_ "GenMsgCycleTime" BO_ 2550399078 500;
BA_ "GenMsgCycleTime" BO_ 2550464614 500;
BA_ "GenMsgCycleTime" BO_ 2550530150 500;
BA_ "GenMsgCycleTime" BO_ 2550595686 500;
BA_ "GenMsgCycleTime" BO_ 2550661222 500;
BA_ "GenMsgCycleTime" BO_ 2550726758 500;
BA_ "GenMsgCycleTime" BO_ 2550792294 500;
BA_ "GenMsgCycleTime" BO_ 2550857830 500;
BA_ "GenMsgCycleTime" BO_ 2550923366 500;
BA_ "GenMsgCycleTime" BO_ 2550988902 1000;
BA_ "GenMsgCycleTime" BO_ 2552299622 1000;
BA_ "GenMsgCycleTime" BO_ 2554396774 1000;
BA_ "GenMsgCycleTime" BO_ 2554462310 1000;
BA_ "GenMsgCycleTime" BO_ 2554527846 1000;
BA_ "GenMsgCycleTime" BO_ 2554593382 1000;
BA_ "GenMsgCycleTime" BO_ 2554658918 1000;
BA_ "GenMsgCycleTime" BO_ 2554724454 1000;
BA_ "GenMsgCycleTime" BO_ 2554789990 1000;
BA_ "GenMsgCycleTime" BO_ 2554855526 1000;
BA_ "GenMsgCycleTime" BO_ 2554921062 1000;
BA_ "GenMsgCycleTime" BO_ 2554986598 1000;
BA_ "GenMsgCycleTime" BO_ 2555052134 1000;
BA_ "GenMsgCycleTime" BO_ 2555117670 1000;
BA_ "GenMsgCycleTime" BO_ 2555183206 1000;
BA_ "GenMsgCycleTime" BO_ 2555248742 1000;
BA_ "GenMsgCycleTime" BO_ 2555314278 1000;
BA_ "GenMsgCycleTime" BO_ 2555379814 1000;
BA_ "GenMsgCycleTime" BO_ 2555445350 1000;
BA_ "GenMsgCycleTime" BO_ 2555510886 1000;
BA_ "GenMsgCycleTime" BO_ 2555576422 1000;
BA_ "GenMsgCycleTime" BO_ 2555641958 1000;
BA_ "GenMsgCycleTime" BO_ 2555707494 1000;
BA_ "GenMsgCycleTime" BO_ 2555773030 1000;
BA_ "GenMsgCycleTime" BO_ 2555838566 1000;
BA_ "GenMsgCycleTime" BO_ 2555904102 1000;
BA_ "GenMsgCycleTime" BO_ 2555969638 1000;
BA_ "GenMsgCycleTime" BO_ 2556035174 1000;
BA_ "GenMsgCycleTime" BO_ 2556100710 1000;
BA_ "GenMsgCycleTime" BO_ 2556166246 1000;
BA_ "GenMsgCycleTime" BO_ 2556231782 1000;
BA_ "GenMsgCycleTime" BO_ 2556297318 1000;
BA_ "GenMsgCycleTime" BO_ 2556362854 1000;
BA_ "GenMsgCycleTime" BO_ 2556428390 1000;
BA_ "GenMsgCycleTime" BO_ 2556493926 1000;
BA_ "GenMsgCycleTime" BO_ 2556559462 1000;
BA_ "GenMsgCycleTime" BO_ 2556624998 1000;
BA_ "GenMsgCycleTime" BO_ 2556690534 1000;
BA_ "GenMsgCycleTime" BO_ 2556756070 1000;
BA_ "GenMsgCycleTime" BO_ 2556821606 1000;
BA_ "GenMsgCycleTime" BO_ 2556887142 1000;
BA_ "GenMsgCycleTime" BO_ 2556952678 1000;
BA_ "GenMsgCycleTime" BO_ 2557018214 1000;
BA_ "GenMsgCycleTime" BO_ 2557083750 1000;
BA_ "GenMsgCycleTime" BO_ 2557149286 1000;
BA_ "GenMsgCycleTime" BO_ 2557214822 1000;
BA_ "GenMsgCycleTime" BO_ 2557280358 1000;
BA_ "GenMsgCycleTime" BO_ 2557345894 1000;
BA_ "GenMsgCycleTime" BO_ 2557411430 1000;
BA_ "GenMsgCycleTime" BO_ 2557476966 1000;
BA_ "GenMsgCycleTime" BO_ 2558525542 1000;
BA_ "GenMsgCycleTime" BO_ 2558591078 1000;
BA_ "GenMsgCycleTime" BO_ 2558656614 1000;
BA_ "GenMsgCycleTime" BO_ 2558722150 1000;
BA_ "GenMsgCycleTime" BO_ 2558787686 1000;
BA_ "GenMsgCycleTime" BO_ 2558853222 1000;
BA_ "GenMsgCycleTime" BO_ 2558918758 1000;
BA_ "GenMsgCycleTime" BO_ 2558984294 1000;
BA_ "GenMsgCycleTime" BO_ 2559049830 1000;
BA_ "GenMsgCycleTime" BO_ 2559115366 1000;
BA_ "GenMsgCycleTime" BO_ 2559180902 1000;
BA_ "GenMsgCycleTime" BO_ 2559246438 1000;
BA_ "GenMsgCycleTime" BO_ 2559311974 1000;
BA_ "GenMsgCycleTime" BO_ 2559377510 1000;
BA_ "GenMsgCycleTime" BO_ 2559443046 1000;
BA_ "GenMsgCycleTime" BO_ 2559508582 1000;
BA_ "GenMsgCycleTime" BO_ 2559574118 1000;
BA_ "GenMsgCycleTime" BO_ 2559639654 1000;
BA_ "GenMsgCycleTime" BO_ 2559705190 1000;
BA_ "GenMsgCycleTime" BO_ 2559770726 1000;
BA_ "GenMsgCycleTime" BO_ 2559836262 1000;
BA_ "GenMsgCycleTime" BO_ 2559901798 1000;
BA_ "GenMsgCycleTime" BO_ 2559967334 1000;
BA_ "GenMsgCycleTime" BO_ 2560032870 1000;
BA_ "GenMsgCycleTime" BO_ 2560098406 1000;
BA_ "GenMsgCycleTime" BO_ 2560163942 1000;
BA_ "GenMsgCycleTime" BO_ 2560229478 1000;
BA_ "GenMsgCycleTime" BO_ 2560295014 1000;
BA_ "GenMsgCycleTime" BO_ 2560360550 1000;
BA_ "GenMsgCycleTime" BO_ 2560426086 1000;
BA_ "GenMsgCycleTime" BO_ 2560491622 1000;
BA_ "GenMsgCycleTime" BO_ 2560557158 1000;
BA_ "GenMsgCycleTime" BO_ 2560622694 1000;
BA_ "GenMsgCycleTime" BO_ 2560688230 1000;
BA_ "GenMsgCycleTime" BO_ 2560753766 1000;
BA_ "GenMsgCycleTime" BO_ 2560819302 1000;
BA_ "GenMsgCycleTime" BO_ 2560884838 1000;
BA_ "GenMsgCycleTime" BO_ 2560950374 1000;
BA_ "GenMsgCycleTime" BO_ 2561015910 1000;
BA_ "GenMsgCycleTime" BO_ 2550399095 500;
BA_ "GenMsgCycleTime" BO_ 2550464631 500;
BA_ "GenMsgCycleTime" BO_ 2550530167 500;
VAL_ 2550530133 P5_PackDschrgPwrStat 02 "鎸佺画鏀剧數鍔熺巼" 01 "30s鏀剧數鍔熺巼" 00 "10s鏀剧數鍔熺巼" ;
VAL_ 2550530133 P5_PackChrgPwrStat 02 "鎸佺画鍏呯數鍔熺巼" 01 "30s鍏呯數鍔熺巼" 00 "10s鍏呯數鍔熺巼" ;
VAL_ 2550595669 P5_ChrgrCplrStat 01 "Connected" 00 "Disconnected" ;
VAL_ 2550595669 P5_HVBattChrgSysStatus 04 "Aborted" 03 "Complete" 02 "Active" 01 "Initialization" 00 "Default" ;
VAL_ 2550857813 P5_CellOverVoltage 03 "Level 3" 02 "Level 2" 01 "Level 1" 00 "No Fault" ;
VAL_ 2550857813 P5_CellUnderVoltage 03 "Level 3" 02 "Level 2" 01 "Level 1" 00 "No Fault" ;
VAL_ 2550857813 P5_CellVoltageDiffHi 01 "Fault" 00 "No Fault" ;
VAL_ 2550857813 P5_PackOverVoltage 03 "Level 3" 02 "Level 2" 01 "Level 1" 00 "No Fault" ;
VAL_ 2550857813 P5_PackUnderVoltage 03 "Level 3" 02 "Level 2" 01 "Level 1" 00 "No Fault" ;
VAL_ 2550857813 P5_CellOverTemp 03 "Level 3" 02 "Level 2" 01 "Level 1" 00 "No Fault" ;
VAL_ 2550857813 P5_CellTempLow 01 "Fault" 00 "No Fault" ;
VAL_ 2550857813 P5_CellTempDiffHi 01 "Fault" 00 "No Fault" ;
VAL_ 2550857813 P5_PackDschrgCrntHi 03 "Level 3" 02 "Level 2" 01 "Level 1" 00 "No Fault" ;
VAL_ 2550857813 P5_PackChrgCrntHi 03 "Level 3" 02 "Level 2" 01 "Level 1" 00 "No Fault" ;
VAL_ 2550857813 P5_PackCrnSnsr1OffsetHi 01 "Fault" 00 "No Fault" ;
VAL_ 2550857813 P5_HVIsolFlt 03 "Level 3" 02 "Level 2" 01 "Level 1" 00 "No Fault" ;
VAL_ 2550857813 P5_HVILFlt 01 "Fault" 00 "No Fault" ;
VAL_ 2550857813 P5_ThrmlRunaway 01 "Fault" 00 "No Fault" ;
VAL_ 2550857813 P5_CellVoltInvalid 01 "Fault" 00 "No Fault" ;
VAL_ 2550857813 P5_CellTempInvalid 01 "Fault" 00 "No Fault" ;
VAL_ 2550857813 P5_DaisyChainComFlt 01 "Fault" 00 "No Fault" ;
VAL_ 2550857813 P5_PackVoltRatFlt 01 "Fault" 00 "No Fault" ;
VAL_ 2550857813 P5_CrntSnsr1Invalid 01 "Fault" 00 "No Fault" ;
VAL_ 2550857813 P5_CrntSnsr1OOR 01 "Fault" 00 "No Fault" ;
VAL_ 2550857813 P5_CrntSnsr2Invalid 01 "Fault" 00 "No Fault" ;
VAL_ 2550857813 P5_CrntSnsr2OOR 01 "Fault" 00 "No Fault" ;
VAL_ 2550857813 P5_PackCrnSnsr2OffsetHi 01 "Fault" 00 "No Fault" ;
VAL_ 2550857813 P5_OutofEnergy 01 "Fault" 00 "No Fault" ;
VAL_ 2550857813 P5_IsolDetCircErr 01 "Fault" 00 "No Fault" ;
VAL_ 2550857813 P5_HVILCircShortToGND 01 "Fault" 00 "No Fault" ;
VAL_ 2550857813 P5_HVILCircShortToPwr 01 "Fault" 00 "No Fault" ;
VAL_ 2550923349 P5_MainPosCntctrStkClsd 01 "Fault" 00 "No Fault" ;
VAL_ 2550923349 P5_MainPosCntctrStkOpn 01 "Fault" 00 "No Fault" ;
VAL_ 2550923349 P5_MainNegCntctr1StkClsd 01 "Fault" 00 "No Fault" ;
VAL_ 2550923349 P5_MainNegCntctr1StkOpn 01 "Fault" 00 "No Fault" ;
VAL_ 2550923349 P5_MainNegCntctr2StkClsd 01 "Fault" 00 "No Fault" ;
VAL_ 2550923349 P5_MainNegCntctr2StkOpn 01 "Fault" 00 "No Fault" ;
VAL_ 2550923349 P5_PrechargTmOut 01 "Fault" 00 "No Fault" ;
VAL_ 2550923349 P5_PrechrgCrntHi 01 "Fault" 00 "No Fault" ;
VAL_ 2550923349 P5_ChrgCplrPosTempHi 01 "Fault" 00 "No Fault" ;
VAL_ 2550923349 P5_ChrgCplrNegTempHi 01 "Fault" 00 "No Fault" ;
VAL_ 2550923349 P5_BMSPwrSuplVlt1Hi 01 "Fault" 00 "No Fault" ;
VAL_ 2550923349 P5_BMSPwrSuplVlt1Lo 01 "Fault" 00 "No Fault" ;
VAL_ 2550923349 P5_BMSPwrSuplVlt2Hi 01 "Fault" 00 "No Fault" ;
VAL_ 2550923349 P5_BMSPwrSuplVlt2Lo 01 "Fault" 00 "No Fault" ;
VAL_ 2550923349 P5_CntctrCirPwrSuplVltLo 01 "Fault" 00 "No Fault" ;
VAL_ 2550923349 P5_CntctrCirPwrSuplVltHi 01 "Fault" 00 "No Fault" ;
VAL_ 2550923349 P5_CAN1BusOff 01 "Fault" 00 "No Fault" ;
VAL_ 2550923349 P5_CAN1BusTmOut 01 "Fault" 00 "No Fault" ;
VAL_ 2550923349 P5_CAN2BusOff 01 "Fault" 00 "No Fault" ;
VAL_ 2550923349 P5_CAN2BusTmOut 01 "Fault" 00 "No Fault" ;
VAL_ 2550923349 P5_CellBalCircTempHi 01 "Fault" 00 "No Fault" ;
VAL_ 2550923349 P5_ClntInTempHi 01 "Fault" 00 "No Fault" ;
VAL_ 2550923349 P5_ClntOutTempHi 01 "Fault" 00 "No Fault" ;
VAL_ 2550923349 P5_CellExtrmUdrVolt 01 "Fault" 00 "No Fault" ;
VAL_ 2550923349 P5_CellExtrmOvrVolt 01 "Fault" 00 "No Fault" ;
VAL_ 2550923349 P5_Branch1DischrgCrntHi  01 "Fault" 00 "No Fault" ;
VAL_ 2550923349 P5_Branch2DischrgCrntHi  01 "Fault" 00 "No Fault" ;
VAL_ 2550923349 P5_Branch1ChrgCrntHi  01 "Fault" 00 "No Fault" ;
VAL_ 2550923349 P5_Branch2ChrgCrntHi  01 "Fault" 00 "No Fault" ;
VAL_ 2550923349 P5_InitFailed 01 "Fault" 00 "No Fault" ;
VAL_ 2554396757 P5_BalSwCell1 01 "Active" 00 "Inactive" ;
VAL_ 2554396757 P5_BalSwCell2 01 "Active" 00 "Inactive" ;
VAL_ 2554396757 P5_BalSwCell3 01 "Active" 00 "Inactive" ;
VAL_ 2554396757 P5_BalSwCell4 01 "Active" 00 "Inactive" ;
VAL_ 2554462293 P5_BalSwCell5 01 "Active" 00 "Inactive" ;
VAL_ 2554462293 P5_BalSwCell6 01 "Active" 00 "Inactive" ;
VAL_ 2554462293 P5_BalSwCell7 01 "Active" 00 "Inactive" ;
VAL_ 2554462293 P5_BalSwCell8 01 "Active" 00 "Inactive" ;
VAL_ 2554527829 P5_BalSwCell9 01 "Active" 00 "Inactive" ;
VAL_ 2554527829 P5_BalSwCell10 01 "Active" 00 "Inactive" ;
VAL_ 2554527829 P5_BalSwCell11 01 "Active" 00 "Inactive" ;
VAL_ 2554527829 P5_BalSwCell12 01 "Active" 00 "Inactive" ;
VAL_ 2554593365 P5_BalSwCell13 01 "Active" 00 "Inactive" ;
VAL_ 2554593365 P5_BalSwCell14 01 "Active" 00 "Inactive" ;
VAL_ 2554593365 P5_BalSwCell15 01 "Active" 00 "Inactive" ;
VAL_ 2554593365 P5_BalSwCell16 01 "Active" 00 "Inactive" ;
VAL_ 2554658901 P5_BalSwCell17 01 "Active" 00 "Inactive" ;
VAL_ 2554658901 P5_BalSwCell18 01 "Active" 00 "Inactive" ;
VAL_ 2554658901 P5_BalSwCell19 01 "Active" 00 "Inactive" ;
VAL_ 2554658901 P5_BalSwCell20 01 "Active" 00 "Inactive" ;
VAL_ 2554724437 P5_BalSwCell21 01 "Active" 00 "Inactive" ;
VAL_ 2554724437 P5_BalSwCell22 01 "Active" 00 "Inactive" ;
VAL_ 2554724437 P5_BalSwCell23 01 "Active" 00 "Inactive" ;
VAL_ 2554724437 P5_BalSwCell24 01 "Active" 00 "Inactive" ;
VAL_ 2554789973 P5_BalSwCell25 01 "Active" 00 "Inactive" ;
VAL_ 2554789973 P5_BalSwCell26 01 "Active" 00 "Inactive" ;
VAL_ 2554789973 P5_BalSwCell27 01 "Active" 00 "Inactive" ;
VAL_ 2554789973 P5_BalSwCell28 01 "Active" 00 "Inactive" ;
VAL_ 2554855509 P5_BalSwCell29 01 "Active" 00 "Inactive" ;
VAL_ 2554855509 P5_BalSwCell30 01 "Active" 00 "Inactive" ;
VAL_ 2554855509 P5_BalSwCell31 01 "Active" 00 "Inactive" ;
VAL_ 2554855509 P5_BalSwCell32 01 "Active" 00 "Inactive" ;
VAL_ 2554921045 P5_BalSwCell33 01 "Active" 00 "Inactive" ;
VAL_ 2554921045 P5_BalSwCell34 01 "Active" 00 "Inactive" ;
VAL_ 2554921045 P5_BalSwCell35 01 "Active" 00 "Inactive" ;
VAL_ 2554921045 P5_BalSwCell36 01 "Active" 00 "Inactive" ;
VAL_ 2554986581 P5_BalSwCell37 01 "Active" 00 "Inactive" ;
VAL_ 2554986581 P5_BalSwCell38 01 "Active" 00 "Inactive" ;
VAL_ 2554986581 P5_BalSwCell39 01 "Active" 00 "Inactive" ;
VAL_ 2554986581 P5_BalSwCell40 01 "Active" 00 "Inactive" ;
VAL_ 2555052117 P5_BalSwCell41 01 "Active" 00 "Inactive" ;
VAL_ 2555052117 P5_BalSwCell42 01 "Active" 00 "Inactive" ;
VAL_ 2555052117 P5_BalSwCell43 01 "Active" 00 "Inactive" ;
VAL_ 2555052117 P5_BalSwCell44 01 "Active" 00 "Inactive" ;
VAL_ 2555117653 P5_BalSwCell45 01 "Active" 00 "Inactive" ;
VAL_ 2555117653 P5_BalSwCell46 01 "Active" 00 "Inactive" ;
VAL_ 2555117653 P5_BalSwCell47 01 "Active" 00 "Inactive" ;
VAL_ 2555117653 P5_BalSwCell48 01 "Active" 00 "Inactive" ;
VAL_ 2555183189 P5_BalSwCell49 01 "Active" 00 "Inactive" ;
VAL_ 2555183189 P5_BalSwCell50 01 "Active" 00 "Inactive" ;
VAL_ 2555183189 P5_BalSwCell51 01 "Active" 00 "Inactive" ;
VAL_ 2555183189 P5_BalSwCell52 01 "Active" 00 "Inactive" ;
VAL_ 2555248725 P5_BalSwCell53 01 "Active" 00 "Inactive" ;
VAL_ 2555248725 P5_BalSwCell54 01 "Active" 00 "Inactive" ;
VAL_ 2555248725 P5_BalSwCell55 01 "Active" 00 "Inactive" ;
VAL_ 2555248725 P5_BalSwCell56 01 "Active" 00 "Inactive" ;
VAL_ 2555314261 P5_BalSwCell57 01 "Active" 00 "Inactive" ;
VAL_ 2555314261 P5_BalSwCell58 01 "Active" 00 "Inactive" ;
VAL_ 2555314261 P5_BalSwCell59 01 "Active" 00 "Inactive" ;
VAL_ 2555314261 P5_BalSwCell60 01 "Active" 00 "Inactive" ;
VAL_ 2555379797 P5_BalSwCell61 01 "Active" 00 "Inactive" ;
VAL_ 2555379797 P5_BalSwCell62 01 "Active" 00 "Inactive" ;
VAL_ 2555379797 P5_BalSwCell63 01 "Active" 00 "Inactive" ;
VAL_ 2555379797 P5_BalSwCell64 01 "Active" 00 "Inactive" ;
VAL_ 2555445333 P5_BalSwCell65 01 "Active" 00 "Inactive" ;
VAL_ 2555445333 P5_BalSwCell66 01 "Active" 00 "Inactive" ;
VAL_ 2555445333 P5_BalSwCell67 01 "Active" 00 "Inactive" ;
VAL_ 2555445333 P5_BalSwCell68 01 "Active" 00 "Inactive" ;
VAL_ 2555510869 P5_BalSwCell69 01 "Active" 00 "Inactive" ;
VAL_ 2555510869 P5_BalSwCell70 01 "Active" 00 "Inactive" ;
VAL_ 2555510869 P5_BalSwCell71 01 "Active" 00 "Inactive" ;
VAL_ 2555510869 P5_BalSwCell72 01 "Active" 00 "Inactive" ;
VAL_ 2555576405 P5_BalSwCell73 01 "Active" 00 "Inactive" ;
VAL_ 2555576405 P5_BalSwCell74 01 "Active" 00 "Inactive" ;
VAL_ 2555576405 P5_BalSwCell75 01 "Active" 00 "Inactive" ;
VAL_ 2555576405 P5_BalSwCell76 01 "Active" 00 "Inactive" ;
VAL_ 2555641941 P5_BalSwCell77 01 "Active" 00 "Inactive" ;
VAL_ 2555641941 P5_BalSwCell78 01 "Active" 00 "Inactive" ;
VAL_ 2555641941 P5_BalSwCell79 01 "Active" 00 "Inactive" ;
VAL_ 2555641941 P5_BalSwCell80 01 "Active" 00 "Inactive" ;
VAL_ 2555707477 P5_BalSwCell81 01 "Active" 00 "Inactive" ;
VAL_ 2555707477 P5_BalSwCell82 01 "Active" 00 "Inactive" ;
VAL_ 2555707477 P5_BalSwCell83 01 "Active" 00 "Inactive" ;
VAL_ 2555707477 P5_BalSwCell84 01 "Active" 00 "Inactive" ;
VAL_ 2555773013 P5_BalSwCell85 01 "Active" 00 "Inactive" ;
VAL_ 2555773013 P5_BalSwCell86 01 "Active" 00 "Inactive" ;
VAL_ 2555773013 P5_BalSwCell87 01 "Active" 00 "Inactive" ;
VAL_ 2555773013 P5_BalSwCell88 01 "Active" 00 "Inactive" ;
VAL_ 2555838549 P5_BalSwCell89 01 "Active" 00 "Inactive" ;
VAL_ 2555838549 P5_BalSwCell90 01 "Active" 00 "Inactive" ;
VAL_ 2555838549 P5_BalSwCell91 01 "Active" 00 "Inactive" ;
VAL_ 2555838549 P5_BalSwCell92 01 "Active" 00 "Inactive" ;
VAL_ 2555904085 P5_BalSwCell93 01 "Active" 00 "Inactive" ;
VAL_ 2555904085 P5_BalSwCell94 01 "Active" 00 "Inactive" ;
VAL_ 2555904085 P5_BalSwCell95 01 "Active" 00 "Inactive" ;
VAL_ 2555904085 P5_BalSwCell96 01 "Active" 00 "Inactive" ;
VAL_ 2555969621 P5_BalSwCell97 01 "Active" 00 "Inactive" ;
VAL_ 2555969621 P5_BalSwCell98 01 "Active" 00 "Inactive" ;
VAL_ 2555969621 P5_BalSwCell99 01 "Active" 00 "Inactive" ;
VAL_ 2555969621 P5_BalSwCell100 01 "Active" 00 "Inactive" ;
VAL_ 2556035157 P5_BalSwCell101 01 "Active" 00 "Inactive" ;
VAL_ 2556035157 P5_BalSwCell102 01 "Active" 00 "Inactive" ;
VAL_ 2556035157 P5_BalSwCell103 01 "Active" 00 "Inactive" ;
VAL_ 2556035157 P5_BalSwCell104 01 "Active" 00 "Inactive" ;
VAL_ 2556100693 P5_BalSwCell105 01 "Active" 00 "Inactive" ;
VAL_ 2556100693 P5_BalSwCell106 01 "Active" 00 "Inactive" ;
VAL_ 2556100693 P5_BalSwCell107 01 "Active" 00 "Inactive" ;
VAL_ 2556100693 P5_BalSwCell108 01 "Active" 00 "Inactive" ;
VAL_ 2556166229 P5_BalSwCell109 01 "Active" 00 "Inactive" ;
VAL_ 2556166229 P5_BalSwCell110 01 "Active" 00 "Inactive" ;
VAL_ 2556166229 P5_BalSwCell111 01 "Active" 00 "Inactive" ;
VAL_ 2556166229 P5_BalSwCell112 01 "Active" 00 "Inactive" ;
VAL_ 2556231765 P5_BalSwCell113 01 "Active" 00 "Inactive" ;
VAL_ 2556231765 P5_BalSwCell114 01 "Active" 00 "Inactive" ;
VAL_ 2556231765 P5_BalSwCell115 01 "Active" 00 "Inactive" ;
VAL_ 2556231765 P5_BalSwCell116 01 "Active" 00 "Inactive" ;
VAL_ 2556297301 P5_BalSwCell117 01 "Active" 00 "Inactive" ;
VAL_ 2556297301 P5_BalSwCell118 01 "Active" 00 "Inactive" ;
VAL_ 2556297301 P5_BalSwCell119 01 "Active" 00 "Inactive" ;
VAL_ 2556297301 P5_BalSwCell120 01 "Active" 00 "Inactive" ;
VAL_ 2556362837 P5_BalSwCell121 01 "Active" 00 "Inactive" ;
VAL_ 2556362837 P5_BalSwCell122 01 "Active" 00 "Inactive" ;
VAL_ 2556362837 P5_BalSwCell123 01 "Active" 00 "Inactive" ;
VAL_ 2556362837 P5_BalSwCell124 01 "Active" 00 "Inactive" ;
VAL_ 2556428373 P5_BalSwCell125 01 "Active" 00 "Inactive" ;
VAL_ 2556428373 P5_BalSwCell126 01 "Active" 00 "Inactive" ;
VAL_ 2556428373 P5_BalSwCell127 01 "Active" 00 "Inactive" ;
VAL_ 2556428373 P5_BalSwCell128 01 "Active" 00 "Inactive" ;
VAL_ 2556493909 P5_BalSwCell129 01 "Active" 00 "Inactive" ;
VAL_ 2556493909 P5_BalSwCell130 01 "Active" 00 "Inactive" ;
VAL_ 2556493909 P5_BalSwCell131 01 "Active" 00 "Inactive" ;
VAL_ 2556493909 P5_BalSwCell132 01 "Active" 00 "Inactive" ;
VAL_ 2556559445 P5_BalSwCell133 01 "Active" 00 "Inactive" ;
VAL_ 2556559445 P5_BalSwCell134 01 "Active" 00 "Inactive" ;
VAL_ 2556559445 P5_BalSwCell135 01 "Active" 00 "Inactive" ;
VAL_ 2556559445 P5_BalSwCell136 01 "Active" 00 "Inactive" ;
VAL_ 2556624981 P5_BalSwCell137 01 "Active" 00 "Inactive" ;
VAL_ 2556624981 P5_BalSwCell138 01 "Active" 00 "Inactive" ;
VAL_ 2556624981 P5_BalSwCell139 01 "Active" 00 "Inactive" ;
VAL_ 2556624981 P5_BalSwCell140 01 "Active" 00 "Inactive" ;
VAL_ 2556690517 P5_BalSwCell141 01 "Active" 00 "Inactive" ;
VAL_ 2556690517 P5_BalSwCell142 01 "Active" 00 "Inactive" ;
VAL_ 2556690517 P5_BalSwCell143 01 "Active" 00 "Inactive" ;
VAL_ 2556690517 P5_BalSwCell144 01 "Active" 00 "Inactive" ;
VAL_ 2556756053 P5_BalSwCell145 01 "Active" 00 "Inactive" ;
VAL_ 2556756053 P5_BalSwCell146 01 "Active" 00 "Inactive" ;
VAL_ 2556756053 P5_BalSwCell147 01 "Active" 00 "Inactive" ;
VAL_ 2556756053 P5_BalSwCell148 01 "Active" 00 "Inactive" ;
VAL_ 2556821589 P5_BalSwCell149 01 "Active" 00 "Inactive" ;
VAL_ 2556821589 P5_BalSwCell150 01 "Active" 00 "Inactive" ;
VAL_ 2556821589 P5_BalSwCell151 01 "Active" 00 "Inactive" ;
VAL_ 2556821589 P5_BalSwCell152 01 "Active" 00 "Inactive" ;
VAL_ 2556887125 P5_BalSwCell153 01 "Active" 00 "Inactive" ;
VAL_ 2556887125 P5_BalSwCell154 01 "Active" 00 "Inactive" ;
VAL_ 2556887125 P5_BalSwCell155 01 "Active" 00 "Inactive" ;
VAL_ 2556887125 P5_BalSwCell156 01 "Active" 00 "Inactive" ;
VAL_ 2556952661 P5_BalSwCell157 01 "Active" 00 "Inactive" ;
VAL_ 2556952661 P5_BalSwCell158 01 "Active" 00 "Inactive" ;
VAL_ 2556952661 P5_BalSwCell159 01 "Active" 00 "Inactive" ;
VAL_ 2556952661 P5_BalSwCell160 01 "Active" 00 "Inactive" ;
VAL_ 2557018197 P5_BalSwCell161 01 "Active" 00 "Inactive" ;
VAL_ 2557018197 P5_BalSwCell162 01 "Active" 00 "Inactive" ;
VAL_ 2557018197 P5_BalSwCell163 01 "Active" 00 "Inactive" ;
VAL_ 2557018197 P5_BalSwCell164 01 "Active" 00 "Inactive" ;
VAL_ 2557083733 P5_BalSwCell165 01 "Active" 00 "Inactive" ;
VAL_ 2557083733 P5_BalSwCell166 01 "Active" 00 "Inactive" ;
VAL_ 2557083733 P5_BalSwCell167 01 "Active" 00 "Inactive" ;
VAL_ 2557083733 P5_BalSwCell168 01 "Active" 00 "Inactive" ;
VAL_ 2557149269 P5_BalSwCell169 01 "Active" 00 "Inactive" ;
VAL_ 2557149269 P5_BalSwCell170 01 "Active" 00 "Inactive" ;
VAL_ 2557149269 P5_BalSwCell171 01 "Active" 00 "Inactive" ;
VAL_ 2557149269 P5_BalSwCell172 01 "Active" 00 "Inactive" ;
VAL_ 2557214805 P5_BalSwCell173 01 "Active" 00 "Inactive" ;
VAL_ 2557214805 P5_BalSwCell174 01 "Active" 00 "Inactive" ;
VAL_ 2557214805 P5_BalSwCell175 01 "Active" 00 "Inactive" ;
VAL_ 2557214805 P5_BalSwCell176 01 "Active" 00 "Inactive" ;
VAL_ 2557280341 P5_BalSwCell177 01 "Active" 00 "Inactive" ;
VAL_ 2557280341 P5_BalSwCell178 01 "Active" 00 "Inactive" ;
VAL_ 2557280341 P5_BalSwCell179 01 "Active" 00 "Inactive" ;
VAL_ 2557280341 P5_BalSwCell180 01 "Active" 00 "Inactive" ;
VAL_ 2557345877 P5_BalSwCell181 01 "Active" 00 "Inactive" ;
VAL_ 2557345877 P5_BalSwCell182 01 "Active" 00 "Inactive" ;
VAL_ 2557345877 P5_BalSwCell183 01 "Active" 00 "Inactive" ;
VAL_ 2557345877 P5_BalSwCell184 01 "Active" 00 "Inactive" ;
VAL_ 2557411413 P5_BalSwCell185 01 "Active" 00 "Inactive" ;
VAL_ 2557411413 P5_BalSwCell186 01 "Active" 00 "Inactive" ;
VAL_ 2557411413 P5_BalSwCell187 01 "Active" 00 "Inactive" ;
VAL_ 2557411413 P5_BalSwCell188 01 "Active" 00 "Inactive" ;
VAL_ 2557476949 P5_BalSwCell189 01 "Active" 00 "Inactive" ;
VAL_ 2557476949 P5_BalSwCell190 01 "Active" 00 "Inactive" ;
VAL_ 2557476949 P5_BalSwCell191 01 "Active" 00 "Inactive" ;
VAL_ 2557476949 P5_BalSwCell192 01 "Active" 00 "Inactive" ;
VAL_ 2550399078 P6_BMSKL15ON 01 "On" 00 "Off" ;
VAL_ 2550530150 P6_PackDschrgPwrStat 02 "鎸佺画鏀剧數鍔熺巼" 01 "30s鏀剧數鍔熺巼" 00 "10s鏀剧數鍔熺巼" ;
VAL_ 2550530150 P6_PackChrgPwrStat 02 "鎸佺画鍏呯數鍔熺巼" 01 "30s鍏呯數鍔熺巼" 00 "10s鍏呯數鍔熺巼" ;
VAL_ 2550595686 P6_ChrgrCplrStat 01 "Connected" 00 "Disconnected" ;
VAL_ 2550595686 P6_HVBattChrgSysStatus 04 "Aborted" 03 "Complete" 02 "Active" 01 "Initialization" 00 "Default" ;
VAL_ 2550857830 P6_CellOverVoltage 03 "Level 3" 02 "Level 2" 01 "Level 1" 00 "No Fault" ;
VAL_ 2550857830 P6_CellUnderVoltage 03 "Level 3" 02 "Level 2" 01 "Level 1" 00 "No Fault" ;
VAL_ 2550857830 P6_CellVoltageDiffHi 01 "Fault" 00 "No Fault" ;
VAL_ 2550857830 P6_PackOverVoltage 03 "Level 3" 02 "Level 2" 01 "Level 1" 00 "No Fault" ;
VAL_ 2550857830 P6_PackUnderVoltage 03 "Level 3" 02 "Level 2" 01 "Level 1" 00 "No Fault" ;
VAL_ 2550857830 P6_CellOverTemp 03 "Level 3" 02 "Level 2" 01 "Level 1" 00 "No Fault" ;
VAL_ 2550857830 P6_CellTempLow 01 "Fault" 00 "No Fault" ;
VAL_ 2550857830 P6_CellTempDiffHi 01 "Fault" 00 "No Fault" ;
VAL_ 2550857830 P6_PackDschrgCrntHi 03 "Level 3" 02 "Level 2" 01 "Level 1" 00 "No Fault" ;
VAL_ 2550857830 P6_PackChrgCrntHi 03 "Level 3" 02 "Level 2" 01 "Level 1" 00 "No Fault" ;
VAL_ 2550857830 P6_PackCrnSnsr1OffsetHi 01 "Fault" 00 "No Fault" ;
VAL_ 2550857830 P6_HVIsolFlt 03 "Level 3" 02 "Level 2" 01 "Level 1" 00 "No Fault" ;
VAL_ 2550857830 P6_HVILFlt 01 "Fault" 00 "No Fault" ;
VAL_ 2550857830 P6_ThrmlRunaway 01 "Fault" 00 "No Fault" ;
VAL_ 2550857830 P6_CellVoltInvalid 01 "Fault" 00 "No Fault" ;
VAL_ 2550857830 P6_CellTempInvalid 01 "Fault" 00 "No Fault" ;
VAL_ 2550857830 P6_DaisyChainComFlt 01 "Fault" 00 "No Fault" ;
VAL_ 2550857830 P6_PackVoltRatFlt 01 "Fault" 00 "No Fault" ;
VAL_ 2550857830 P6_CrntSnsr1Invalid 01 "Fault" 00 "No Fault" ;
VAL_ 2550857830 P6_CrntSnsr1OOR 01 "Fault" 00 "No Fault" ;
VAL_ 2550857830 P6_CrntSnsr2Invalid 01 "Fault" 00 "No Fault" ;
VAL_ 2550857830 P6_CrntSnsr2OOR 01 "Fault" 00 "No Fault" ;
VAL_ 2550857830 P6_PackCrnSnsr2OffsetHi 01 "Fault" 00 "No Fault" ;
VAL_ 2550857830 P6_OutofEnergy 01 "Fault" 00 "No Fault" ;
VAL_ 2550857830 P6_IsolDetCircErr 01 "Fault" 00 "No Fault" ;
VAL_ 2550857830 P6_HVILCircShortToGND 01 "Fault" 00 "No Fault" ;
VAL_ 2550857830 P6_HVILCircShortToPwr 01 "Fault" 00 "No Fault" ;
VAL_ 2550923366 P6_MainPosCntctrStkClsd 01 "Fault" 00 "No Fault" ;
VAL_ 2550923366 P6_MainPosCntctrStkOpn 01 "Fault" 00 "No Fault" ;
VAL_ 2550923366 P6_MainNegCntctr1StkClsd 01 "Fault" 00 "No Fault" ;
VAL_ 2550923366 P6_MainNegCntctr1StkOpn 01 "Fault" 00 "No Fault" ;
VAL_ 2550923366 P6_MainNegCntctr2StkClsd 01 "Fault" 00 "No Fault" ;
VAL_ 2550923366 P6_MainNegCntctr2StkOpn 01 "Fault" 00 "No Fault" ;
VAL_ 2550923366 P6_PrechargTmOut 01 "Fault" 00 "No Fault" ;
VAL_ 2550923366 P6_PrechrgCrntHi 01 "Fault" 00 "No Fault" ;
VAL_ 2550923366 P6_ChrgCplrPosTempHi 01 "Fault" 00 "No Fault" ;
VAL_ 2550923366 P6_ChrgCplrNegTempHi 01 "Fault" 00 "No Fault" ;
VAL_ 2550923366 P6_BMSPwrSuplVlt1Hi 01 "Fault" 00 "No Fault" ;
VAL_ 2550923366 P6_BMSPwrSuplVlt1Lo 01 "Fault" 00 "No Fault" ;
VAL_ 2550923366 P6_BMSPwrSuplVlt2Hi 01 "Fault" 00 "No Fault" ;
VAL_ 2550923366 P6_BMSPwrSuplVlt2Lo 01 "Fault" 00 "No Fault" ;
VAL_ 2550923366 P6_CntctrCirPwrSuplVltLo 01 "Fault" 00 "No Fault" ;
VAL_ 2550923366 P6_CntctrCirPwrSuplVltHi 01 "Fault" 00 "No Fault" ;
VAL_ 2550923366 P6_CAN1BusOff 01 "Fault" 00 "No Fault" ;
VAL_ 2550923366 P6_CAN1BusTmOut 01 "Fault" 00 "No Fault" ;
VAL_ 2550923366 P6_CAN2BusOff 01 "Fault" 00 "No Fault" ;
VAL_ 2550923366 P6_CAN2BusTmOut 01 "Fault" 00 "No Fault" ;
VAL_ 2550923366 P6_CellBalCircTempHi 01 "Fault" 00 "No Fault" ;
VAL_ 2550923366 P6_ClntInTempHi 01 "Fault" 00 "No Fault" ;
VAL_ 2550923366 P6_ClntOutTempHi 01 "Fault" 00 "No Fault" ;
VAL_ 2550923366 P6_CellExtrmUdrVolt 01 "Fault" 00 "No Fault" ;
VAL_ 2550923366 P6_CellExtrmOvrVolt 01 "Fault" 00 "No Fault" ;
VAL_ 2550923366 P6_Branch1DischrgCrntHi  01 "Fault" 00 "No Fault" ;
VAL_ 2550923366 P6_Branch2DischrgCrntHi  01 "Fault" 00 "No Fault" ;
VAL_ 2550923366 P6_Branch1ChrgCrntHi  01 "Fault" 00 "No Fault" ;
VAL_ 2550923366 P6_Branch2ChrgCrntHi  01 "Fault" 00 "No Fault" ;
VAL_ 2550923366 P6_InitFailed 01 "Fault" 00 "No Fault" ;
VAL_ 2554396774 P6_BalSwCell1 01 "Active" 00 "Inactive" ;
VAL_ 2554396774 P6_BalSwCell2 01 "Active" 00 "Inactive" ;
VAL_ 2554396774 P6_BalSwCell3 01 "Active" 00 "Inactive" ;
VAL_ 2554396774 P6_BalSwCell4 01 "Active" 00 "Inactive" ;
VAL_ 2554462310 P6_BalSwCell5 01 "Active" 00 "Inactive" ;
VAL_ 2554462310 P6_BalSwCell6 01 "Active" 00 "Inactive" ;
VAL_ 2554462310 P6_BalSwCell7 01 "Active" 00 "Inactive" ;
VAL_ 2554462310 P6_BalSwCell8 01 "Active" 00 "Inactive" ;
VAL_ 2554527846 P6_BalSwCell9 01 "Active" 00 "Inactive" ;
VAL_ 2554527846 P6_BalSwCell10 01 "Active" 00 "Inactive" ;
VAL_ 2554527846 P6_BalSwCell11 01 "Active" 00 "Inactive" ;
VAL_ 2554527846 P6_BalSwCell12 01 "Active" 00 "Inactive" ;
VAL_ 2554593382 P6_BalSwCell13 01 "Active" 00 "Inactive" ;
VAL_ 2554593382 P6_BalSwCell14 01 "Active" 00 "Inactive" ;
VAL_ 2554593382 P6_BalSwCell15 01 "Active" 00 "Inactive" ;
VAL_ 2554593382 P6_BalSwCell16 01 "Active" 00 "Inactive" ;
VAL_ 2554658918 P6_BalSwCell17 01 "Active" 00 "Inactive" ;
VAL_ 2554658918 P6_BalSwCell18 01 "Active" 00 "Inactive" ;
VAL_ 2554658918 P6_BalSwCell19 01 "Active" 00 "Inactive" ;
VAL_ 2554658918 P6_BalSwCell20 01 "Active" 00 "Inactive" ;
VAL_ 2554724454 P6_BalSwCell21 01 "Active" 00 "Inactive" ;
VAL_ 2554724454 P6_BalSwCell22 01 "Active" 00 "Inactive" ;
VAL_ 2554724454 P6_BalSwCell23 01 "Active" 00 "Inactive" ;
VAL_ 2554724454 P6_BalSwCell24 01 "Active" 00 "Inactive" ;
VAL_ 2554789990 P6_BalSwCell25 01 "Active" 00 "Inactive" ;
VAL_ 2554789990 P6_BalSwCell26 01 "Active" 00 "Inactive" ;
VAL_ 2554789990 P6_BalSwCell27 01 "Active" 00 "Inactive" ;
VAL_ 2554789990 P6_BalSwCell28 01 "Active" 00 "Inactive" ;
VAL_ 2554855526 P6_BalSwCell29 01 "Active" 00 "Inactive" ;
VAL_ 2554855526 P6_BalSwCell30 01 "Active" 00 "Inactive" ;
VAL_ 2554855526 P6_BalSwCell31 01 "Active" 00 "Inactive" ;
VAL_ 2554855526 P6_BalSwCell32 01 "Active" 00 "Inactive" ;
VAL_ 2554921062 P6_BalSwCell33 01 "Active" 00 "Inactive" ;
VAL_ 2554921062 P6_BalSwCell34 01 "Active" 00 "Inactive" ;
VAL_ 2554921062 P6_BalSwCell35 01 "Active" 00 "Inactive" ;
VAL_ 2554921062 P6_BalSwCell36 01 "Active" 00 "Inactive" ;
VAL_ 2554986598 P6_BalSwCell37 01 "Active" 00 "Inactive" ;
VAL_ 2554986598 P6_BalSwCell38 01 "Active" 00 "Inactive" ;
VAL_ 2554986598 P6_BalSwCell39 01 "Active" 00 "Inactive" ;
VAL_ 2554986598 P6_BalSwCell40 01 "Active" 00 "Inactive" ;
VAL_ 2555052134 P6_BalSwCell41 01 "Active" 00 "Inactive" ;
VAL_ 2555052134 P6_BalSwCell42 01 "Active" 00 "Inactive" ;
VAL_ 2555052134 P6_BalSwCell43 01 "Active" 00 "Inactive" ;
VAL_ 2555052134 P6_BalSwCell44 01 "Active" 00 "Inactive" ;
VAL_ 2555117670 P6_BalSwCell45 01 "Active" 00 "Inactive" ;
VAL_ 2555117670 P6_BalSwCell46 01 "Active" 00 "Inactive" ;
VAL_ 2555117670 P6_BalSwCell47 01 "Active" 00 "Inactive" ;
VAL_ 2555117670 P6_BalSwCell48 01 "Active" 00 "Inactive" ;
VAL_ 2555183206 P6_BalSwCell49 01 "Active" 00 "Inactive" ;
VAL_ 2555183206 P6_BalSwCell50 01 "Active" 00 "Inactive" ;
VAL_ 2555183206 P6_BalSwCell51 01 "Active" 00 "Inactive" ;
VAL_ 2555183206 P6_BalSwCell52 01 "Active" 00 "Inactive" ;
VAL_ 2555248742 P6_BalSwCell53 01 "Active" 00 "Inactive" ;
VAL_ 2555248742 P6_BalSwCell54 01 "Active" 00 "Inactive" ;
VAL_ 2555248742 P6_BalSwCell55 01 "Active" 00 "Inactive" ;
VAL_ 2555248742 P6_BalSwCell56 01 "Active" 00 "Inactive" ;
VAL_ 2555314278 P6_BalSwCell57 01 "Active" 00 "Inactive" ;
VAL_ 2555314278 P6_BalSwCell58 01 "Active" 00 "Inactive" ;
VAL_ 2555314278 P6_BalSwCell59 01 "Active" 00 "Inactive" ;
VAL_ 2555314278 P6_BalSwCell60 01 "Active" 00 "Inactive" ;
VAL_ 2555379814 P6_BalSwCell61 01 "Active" 00 "Inactive" ;
VAL_ 2555379814 P6_BalSwCell62 01 "Active" 00 "Inactive" ;
VAL_ 2555379814 P6_BalSwCell63 01 "Active" 00 "Inactive" ;
VAL_ 2555379814 P6_BalSwCell64 01 "Active" 00 "Inactive" ;
VAL_ 2555445350 P6_BalSwCell65 01 "Active" 00 "Inactive" ;
VAL_ 2555445350 P6_BalSwCell66 01 "Active" 00 "Inactive" ;
VAL_ 2555445350 P6_BalSwCell67 01 "Active" 00 "Inactive" ;
VAL_ 2555445350 P6_BalSwCell68 01 "Active" 00 "Inactive" ;
VAL_ 2555510886 P6_BalSwCell69 01 "Active" 00 "Inactive" ;
VAL_ 2555510886 P6_BalSwCell70 01 "Active" 00 "Inactive" ;
VAL_ 2555510886 P6_BalSwCell71 01 "Active" 00 "Inactive" ;
VAL_ 2555510886 P6_BalSwCell72 01 "Active" 00 "Inactive" ;
VAL_ 2555576422 P6_BalSwCell73 01 "Active" 00 "Inactive" ;
VAL_ 2555576422 P6_BalSwCell74 01 "Active" 00 "Inactive" ;
VAL_ 2555576422 P6_BalSwCell75 01 "Active" 00 "Inactive" ;
VAL_ 2555576422 P6_BalSwCell76 01 "Active" 00 "Inactive" ;
VAL_ 2555641958 P6_BalSwCell77 01 "Active" 00 "Inactive" ;
VAL_ 2555641958 P6_BalSwCell78 01 "Active" 00 "Inactive" ;
VAL_ 2555641958 P6_BalSwCell79 01 "Active" 00 "Inactive" ;
VAL_ 2555641958 P6_BalSwCell80 01 "Active" 00 "Inactive" ;
VAL_ 2555707494 P6_BalSwCell81 01 "Active" 00 "Inactive" ;
VAL_ 2555707494 P6_BalSwCell82 01 "Active" 00 "Inactive" ;
VAL_ 2555707494 P6_BalSwCell83 01 "Active" 00 "Inactive" ;
VAL_ 2555707494 P6_BalSwCell84 01 "Active" 00 "Inactive" ;
VAL_ 2555773030 P6_BalSwCell85 01 "Active" 00 "Inactive" ;
VAL_ 2555773030 P6_BalSwCell86 01 "Active" 00 "Inactive" ;
VAL_ 2555773030 P6_BalSwCell87 01 "Active" 00 "Inactive" ;
VAL_ 2555773030 P6_BalSwCell88 01 "Active" 00 "Inactive" ;
VAL_ 2555838566 P6_BalSwCell89 01 "Active" 00 "Inactive" ;
VAL_ 2555838566 P6_BalSwCell90 01 "Active" 00 "Inactive" ;
VAL_ 2555838566 P6_BalSwCell91 01 "Active" 00 "Inactive" ;
VAL_ 2555838566 P6_BalSwCell92 01 "Active" 00 "Inactive" ;
VAL_ 2555904102 P6_BalSwCell93 01 "Active" 00 "Inactive" ;
VAL_ 2555904102 P6_BalSwCell94 01 "Active" 00 "Inactive" ;
VAL_ 2555904102 P6_BalSwCell95 01 "Active" 00 "Inactive" ;
VAL_ 2555904102 P6_BalSwCell96 01 "Active" 00 "Inactive" ;
VAL_ 2555969638 P6_BalSwCell97 01 "Active" 00 "Inactive" ;
VAL_ 2555969638 P6_BalSwCell98 01 "Active" 00 "Inactive" ;
VAL_ 2555969638 P6_BalSwCell99 01 "Active" 00 "Inactive" ;
VAL_ 2555969638 P6_BalSwCell100 01 "Active" 00 "Inactive" ;
VAL_ 2556035174 P6_BalSwCell101 01 "Active" 00 "Inactive" ;
VAL_ 2556035174 P6_BalSwCell102 01 "Active" 00 "Inactive" ;
VAL_ 2556035174 P6_BalSwCell103 01 "Active" 00 "Inactive" ;
VAL_ 2556035174 P6_BalSwCell104 01 "Active" 00 "Inactive" ;
VAL_ 2556100710 P6_BalSwCell105 01 "Active" 00 "Inactive" ;
VAL_ 2556100710 P6_BalSwCell106 01 "Active" 00 "Inactive" ;
VAL_ 2556100710 P6_BalSwCell107 01 "Active" 00 "Inactive" ;
VAL_ 2556100710 P6_BalSwCell108 01 "Active" 00 "Inactive" ;
VAL_ 2556166246 P6_BalSwCell109 01 "Active" 00 "Inactive" ;
VAL_ 2556166246 P6_BalSwCell110 01 "Active" 00 "Inactive" ;
VAL_ 2556166246 P6_BalSwCell111 01 "Active" 00 "Inactive" ;
VAL_ 2556166246 P6_BalSwCell112 01 "Active" 00 "Inactive" ;
VAL_ 2556231782 P6_BalSwCell113 01 "Active" 00 "Inactive" ;
VAL_ 2556231782 P6_BalSwCell114 01 "Active" 00 "Inactive" ;
VAL_ 2556231782 P6_BalSwCell115 01 "Active" 00 "Inactive" ;
VAL_ 2556231782 P6_BalSwCell116 01 "Active" 00 "Inactive" ;
VAL_ 2556297318 P6_BalSwCell117 01 "Active" 00 "Inactive" ;
VAL_ 2556297318 P6_BalSwCell118 01 "Active" 00 "Inactive" ;
VAL_ 2556297318 P6_BalSwCell119 01 "Active" 00 "Inactive" ;
VAL_ 2556297318 P6_BalSwCell120 01 "Active" 00 "Inactive" ;
VAL_ 2556362854 P6_BalSwCell121 01 "Active" 00 "Inactive" ;
VAL_ 2556362854 P6_BalSwCell122 01 "Active" 00 "Inactive" ;
VAL_ 2556362854 P6_BalSwCell123 01 "Active" 00 "Inactive" ;
VAL_ 2556362854 P6_BalSwCell124 01 "Active" 00 "Inactive" ;
VAL_ 2556428390 P6_BalSwCell125 01 "Active" 00 "Inactive" ;
VAL_ 2556428390 P6_BalSwCell126 01 "Active" 00 "Inactive" ;
VAL_ 2556428390 P6_BalSwCell127 01 "Active" 00 "Inactive" ;
VAL_ 2556428390 P6_BalSwCell128 01 "Active" 00 "Inactive" ;
VAL_ 2556493926 P6_BalSwCell129 01 "Active" 00 "Inactive" ;
VAL_ 2556493926 P6_BalSwCell130 01 "Active" 00 "Inactive" ;
VAL_ 2556493926 P6_BalSwCell131 01 "Active" 00 "Inactive" ;
VAL_ 2556493926 P6_BalSwCell132 01 "Active" 00 "Inactive" ;
VAL_ 2556559462 P6_BalSwCell133 01 "Active" 00 "Inactive" ;
VAL_ 2556559462 P6_BalSwCell134 01 "Active" 00 "Inactive" ;
VAL_ 2556559462 P6_BalSwCell135 01 "Active" 00 "Inactive" ;
VAL_ 2556559462 P6_BalSwCell136 01 "Active" 00 "Inactive" ;
VAL_ 2556624998 P6_BalSwCell137 01 "Active" 00 "Inactive" ;
VAL_ 2556624998 P6_BalSwCell138 01 "Active" 00 "Inactive" ;
VAL_ 2556624998 P6_BalSwCell139 01 "Active" 00 "Inactive" ;
VAL_ 2556624998 P6_BalSwCell140 01 "Active" 00 "Inactive" ;
VAL_ 2556690534 P6_BalSwCell141 01 "Active" 00 "Inactive" ;
VAL_ 2556690534 P6_BalSwCell142 01 "Active" 00 "Inactive" ;
VAL_ 2556690534 P6_BalSwCell143 01 "Active" 00 "Inactive" ;
VAL_ 2556690534 P6_BalSwCell144 01 "Active" 00 "Inactive" ;
VAL_ 2556756070 P6_BalSwCell145 01 "Active" 00 "Inactive" ;
VAL_ 2556756070 P6_BalSwCell146 01 "Active" 00 "Inactive" ;
VAL_ 2556756070 P6_BalSwCell147 01 "Active" 00 "Inactive" ;
VAL_ 2556756070 P6_BalSwCell148 01 "Active" 00 "Inactive" ;
VAL_ 2556821606 P6_BalSwCell149 01 "Active" 00 "Inactive" ;
VAL_ 2556821606 P6_BalSwCell150 01 "Active" 00 "Inactive" ;
VAL_ 2556821606 P6_BalSwCell151 01 "Active" 00 "Inactive" ;
VAL_ 2556821606 P6_BalSwCell152 01 "Active" 00 "Inactive" ;
VAL_ 2556887142 P6_BalSwCell153 01 "Active" 00 "Inactive" ;
VAL_ 2556887142 P6_BalSwCell154 01 "Active" 00 "Inactive" ;
VAL_ 2556887142 P6_BalSwCell155 01 "Active" 00 "Inactive" ;
VAL_ 2556887142 P6_BalSwCell156 01 "Active" 00 "Inactive" ;
VAL_ 2556952678 P6_BalSwCell157 01 "Active" 00 "Inactive" ;
VAL_ 2556952678 P6_BalSwCell158 01 "Active" 00 "Inactive" ;
VAL_ 2556952678 P6_BalSwCell159 01 "Active" 00 "Inactive" ;
VAL_ 2556952678 P6_BalSwCell160 01 "Active" 00 "Inactive" ;
VAL_ 2557018214 P6_BalSwCell161 01 "Active" 00 "Inactive" ;
VAL_ 2557018214 P6_BalSwCell162 01 "Active" 00 "Inactive" ;
VAL_ 2557018214 P6_BalSwCell163 01 "Active" 00 "Inactive" ;
VAL_ 2557018214 P6_BalSwCell164 01 "Active" 00 "Inactive" ;
VAL_ 2557083750 P6_BalSwCell165 01 "Active" 00 "Inactive" ;
VAL_ 2557083750 P6_BalSwCell166 01 "Active" 00 "Inactive" ;
VAL_ 2557083750 P6_BalSwCell167 01 "Active" 00 "Inactive" ;
VAL_ 2557083750 P6_BalSwCell168 01 "Active" 00 "Inactive" ;
VAL_ 2557149286 P6_BalSwCell169 01 "Active" 00 "Inactive" ;
VAL_ 2557149286 P6_BalSwCell170 01 "Active" 00 "Inactive" ;
VAL_ 2557149286 P6_BalSwCell171 01 "Active" 00 "Inactive" ;
VAL_ 2557149286 P6_BalSwCell172 01 "Active" 00 "Inactive" ;
VAL_ 2557214822 P6_BalSwCell173 01 "Active" 00 "Inactive" ;
VAL_ 2557214822 P6_BalSwCell174 01 "Active" 00 "Inactive" ;
VAL_ 2557214822 P6_BalSwCell175 01 "Active" 00 "Inactive" ;
VAL_ 2557214822 P6_BalSwCell176 01 "Active" 00 "Inactive" ;
VAL_ 2557280358 P6_BalSwCell177 01 "Active" 00 "Inactive" ;
VAL_ 2557280358 P6_BalSwCell178 01 "Active" 00 "Inactive" ;
VAL_ 2557280358 P6_BalSwCell179 01 "Active" 00 "Inactive" ;
VAL_ 2557280358 P6_BalSwCell180 01 "Active" 00 "Inactive" ;
VAL_ 2557345894 P6_BalSwCell181 01 "Active" 00 "Inactive" ;
VAL_ 2557345894 P6_BalSwCell182 01 "Active" 00 "Inactive" ;
VAL_ 2557345894 P6_BalSwCell183 01 "Active" 00 "Inactive" ;
VAL_ 2557345894 P6_BalSwCell184 01 "Active" 00 "Inactive" ;
VAL_ 2557411430 P6_BalSwCell185 01 "Active" 00 "Inactive" ;
VAL_ 2557411430 P6_BalSwCell186 01 "Active" 00 "Inactive" ;
VAL_ 2557411430 P6_BalSwCell187 01 "Active" 00 "Inactive" ;
VAL_ 2557411430 P6_BalSwCell188 01 "Active" 00 "Inactive" ;
VAL_ 2557476966 P6_BalSwCell189 01 "Active" 00 "Inactive" ;
VAL_ 2557476966 P6_BalSwCell190 01 "Active" 00 "Inactive" ;
VAL_ 2557476966 P6_BalSwCell191 01 "Active" 00 "Inactive" ;
VAL_ 2557476966 P6_BalSwCell192 01 "Active" 00 "Inactive" ;
VAL_ 2550399095 P7_BMSKL15ON 01 "On" 00 "Off" ;
VAL_ 2550530167 P7_PackDschrgPwrStat 02 "鎸佺画鏀剧數鍔熺巼" 01 "30s鏀剧數鍔熺巼" 00 "10s鏀剧數鍔熺巼" ;
VAL_ 2550530167 P7_PackChrgPwrStat 02 "鎸佺画鍏呯數鍔熺巼" 01 "30s鍏呯數鍔熺巼" 00 "10s鍏呯數鍔熺巼" ;
